VERSION "$Format:%h$"

NS_ :

BS_:

BU_: APB APP APS BCCEN BDY DAS DBG EAS EPAS EPAS2 EPAS3S EPB EPBM ESP GTW GTWU IBST IC MCU OCS PARK PARK3 RADAR RCM RT3000 SCCM SDM SEC TAS TAS2 TAS2DBG TOOL TPMS VCSEATD VCSEATP

BO_ 1513 APP_alertLog: 8 APP
 SG_ APP_alertID M : 0|14@1+ (1,0) [0|0] "" GTW
 SG_ APP_sw144_fanctrldErrorType m144 : 16|8@1+ (1,0) [2|255] "" GTW
 SG_ APP_sw145_pitchSpike m145 : 16|1@1+ (1,0) [0|1] "" GTW
 SG_ APP_sw145_yawSpike m145 : 17|1@1+ (1,0) [0|1] "" GTW
 SG_ APP_sw145_rollSpike m145 : 18|1@1+ (1,0) [0|1] "" GTW
 SG_ APP_sw145_insaneCal m145 : 19|1@1+ (1,0) [0|1] "" GTW
 SG_ APP_sw145_problemSaving m145 : 20|1@1+ (1,0) [0|1] "" GTW
 SG_ APP_sw145_problemCamPosition m145 : 24|4@1+ (1,0) [0|9] "" GTW
 SG_ APP_sw145_camExtPitchCal m145 : 32|9@1- (0.05,0) [-12.5|12.5] "deg" GTW
 SG_ APP_sw145_camExtYawCal m145 : 41|9@1- (0.05,0) [-12.5|12.5] "deg" GTW
 SG_ APP_sw145_camExtRollCal m145 : 50|9@1- (0.05,0) [-12.5|12.5] "deg" GTW
 SG_ APP_sw146_telemProblemType m146 : 16|3@1+ (1,0) [0|7] "" GTW
 SG_ APP_sw146_packageType m146 : 19|3@1+ (1,0) [0|7] "" GTW
 SG_ APP_sw146_numElementsQueued m146 : 22|9@1+ (10,0) [0|5110] "elements" GTW
 SG_ APP_sw146_telemSize m146 : 31|9@1+ (100,0) [0|51100] "kB" GTW
 SG_ APP_sw147_selfieCamI2CbusFault m147 : 16|1@1+ (1,0) [0|1] "" GTW
 SG_ APP_sw147_selfieCamDeserFault m147 : 17|3@1+ (1,0) [0|7] "" GTW
 SG_ APP_sw147_selfieCamSerFault m147 : 21|3@1+ (1,0) [0|7] "" GTW
 SG_ APP_sw147_selfieCamSensorFault m147 : 24|3@1+ (1,0) [0|7] "" GTW
 SG_ APP_sw148_unusedW0 m148 : 16|16@1+ (1,0) [0|0] "" GTW
 SG_ APP_sw148_unusedW1 m148 : 32|16@1+ (1,0) [0|0] "" GTW
 SG_ APP_sw148_unusedW2 m148 : 48|16@1+ (1,0) [0|0] "" GTW
 SG_ APP_sw149_diskUsageVar m149 : 16|8@1+ (1,0) [0|100] "percent" GTW
 SG_ APP_sw149_diskUsageHome m149 : 24|8@1+ (1,0) [0|100] "percent" GTW
 SG_ APP_sw149_diskUsageMap m149 : 32|8@1+ (1,0) [0|100] "percent" GTW
 SG_ APP_sw149_diskUsageAutopilot m149 : 40|8@1+ (1,0) [0|100] "percent" GTW
 SG_ APP_sw161_frameTimeout m161 : 16|1@1+ (1,0) [0|1] "" GTW
 SG_ APP_sw161_hdmiDisplayError m161 : 17|1@1+ (1,0) [0|1] "" GTW
 SG_ APP_sw161_rawImageTimeout m161 : 18|1@1+ (1,0) [0|1] "" GTW
 SG_ APP_sw161_imagerOutOfSpecTemp m161 : 19|1@1+ (1,0) [0|1] "" GTW
 SG_ APP_sw162_colorFilterMismatch m162 : 16|1@1+ (1,0) [0|1] "" GTW
 SG_ APP_sw162_detectedColorFilter m162 : 17|2@1+ (1,0) [0|3] "" GTW
 SG_ APP_sw162_expectedColorFilter m162 : 19|2@1+ (1,0) [0|3] "" GTW
 SG_ APP_sw162_cameraPositionMismatch m162 : 21|1@1+ (1,0) [0|1] "" GTW
 SG_ APP_sw162_blacklistedFuseID m162 : 22|1@1+ (1,0) [0|1] "" GTW
 SG_ APP_sw162_detectedPosition m162 : 24|4@1+ (1,0) [0|9] "" GTW
 SG_ APP_sw163_colorFilterMismatch m163 : 16|1@1+ (1,0) [0|1] "" GTW
 SG_ APP_sw163_detectedColorFilter m163 : 17|2@1+ (1,0) [0|3] "" GTW
 SG_ APP_sw163_expectedColorFilter m163 : 19|2@1+ (1,0) [0|3] "" GTW
 SG_ APP_sw163_cameraPositionMismatch m163 : 21|1@1+ (1,0) [0|1] "" GTW
 SG_ APP_sw163_blacklistedFuseID m163 : 22|1@1+ (1,0) [0|1] "" GTW
 SG_ APP_sw163_detectedPosition m163 : 24|4@1+ (1,0) [0|9] "" GTW
 SG_ APP_sw164_colorFilterMismatch m164 : 16|1@1+ (1,0) [0|1] "" GTW
 SG_ APP_sw164_detectedColorFilter m164 : 17|2@1+ (1,0) [0|3] "" GTW
 SG_ APP_sw164_expectedColorFilter m164 : 19|2@1+ (1,0) [0|3] "" GTW
 SG_ APP_sw164_cameraPositionMismatch m164 : 21|1@1+ (1,0) [0|1] "" GTW
 SG_ APP_sw164_blacklistedFuseID m164 : 22|1@1+ (1,0) [0|1] "" GTW
 SG_ APP_sw164_detectedPosition m164 : 24|4@1+ (1,0) [0|9] "" GTW
 SG_ APP_sw165_colorFilterMismatch m165 : 16|1@1+ (1,0) [0|1] "" GTW
 SG_ APP_sw165_detectedColorFilter m165 : 17|2@1+ (1,0) [0|3] "" GTW
 SG_ APP_sw165_expectedColorFilter m165 : 19|2@1+ (1,0) [0|3] "" GTW
 SG_ APP_sw165_cameraPositionMismatch m165 : 21|1@1+ (1,0) [0|1] "" GTW
 SG_ APP_sw165_blacklistedFuseID m165 : 22|1@1+ (1,0) [0|1] "" GTW
 SG_ APP_sw165_detectedPosition m165 : 24|4@1+ (1,0) [0|9] "" GTW
 SG_ APP_sw166_colorFilterMismatch m166 : 16|1@1+ (1,0) [0|1] "" GTW
 SG_ APP_sw166_detectedColorFilter m166 : 17|2@1+ (1,0) [0|3] "" GTW
 SG_ APP_sw166_expectedColorFilter m166 : 19|2@1+ (1,0) [0|3] "" GTW
 SG_ APP_sw166_cameraPositionMismatch m166 : 21|1@1+ (1,0) [0|1] "" GTW
 SG_ APP_sw166_blacklistedFuseID m166 : 22|1@1+ (1,0) [0|1] "" GTW
 SG_ APP_sw166_detectedPosition m166 : 24|4@1+ (1,0) [0|9] "" GTW
 SG_ APP_sw167_colorFilterMismatch m167 : 16|1@1+ (1,0) [0|1] "" GTW
 SG_ APP_sw167_detectedColorFilter m167 : 17|2@1+ (1,0) [0|3] "" GTW
 SG_ APP_sw167_expectedColorFilter m167 : 19|2@1+ (1,0) [0|3] "" GTW
 SG_ APP_sw167_cameraPositionMismatch m167 : 21|1@1+ (1,0) [0|1] "" GTW
 SG_ APP_sw167_blacklistedFuseID m167 : 22|1@1+ (1,0) [0|1] "" GTW
 SG_ APP_sw167_detectedPosition m167 : 24|4@1+ (1,0) [0|9] "" GTW
 SG_ APP_sw168_colorFilterMismatch m168 : 16|1@1+ (1,0) [0|1] "" GTW
 SG_ APP_sw168_detectedColorFilter m168 : 17|2@1+ (1,0) [0|3] "" GTW
 SG_ APP_sw168_expectedColorFilter m168 : 19|2@1+ (1,0) [0|3] "" GTW
 SG_ APP_sw168_cameraPositionMismatch m168 : 21|1@1+ (1,0) [0|1] "" GTW
 SG_ APP_sw168_blacklistedFuseID m168 : 22|1@1+ (1,0) [0|1] "" GTW
 SG_ APP_sw168_detectedPosition m168 : 24|4@1+ (1,0) [0|9] "" GTW
 SG_ APP_sw169_colorFilterMismatch m169 : 16|1@1+ (1,0) [0|1] "" GTW
 SG_ APP_sw169_detectedColorFilter m169 : 17|2@1+ (1,0) [0|3] "" GTW
 SG_ APP_sw169_expectedColorFilter m169 : 19|2@1+ (1,0) [0|3] "" GTW
 SG_ APP_sw169_cameraPositionMismatch m169 : 21|1@1+ (1,0) [0|1] "" GTW
 SG_ APP_sw169_blacklistedFuseID m169 : 22|1@1+ (1,0) [0|1] "" GTW
 SG_ APP_sw169_detectedPosition m169 : 24|4@1+ (1,0) [0|9] "" GTW
 SG_ APP_sw170_colorFilterMismatch m170 : 16|1@1+ (1,0) [0|1] "" GTW
 SG_ APP_sw170_detectedColorFilter m170 : 17|2@1+ (1,0) [0|3] "" GTW
 SG_ APP_sw170_expectedColorFilter m170 : 19|2@1+ (1,0) [0|3] "" GTW
 SG_ APP_sw170_cameraPositionMismatch m170 : 21|1@1+ (1,0) [0|1] "" GTW
 SG_ APP_sw170_blacklistedFuseID m170 : 22|1@1+ (1,0) [0|1] "" GTW
 SG_ APP_sw170_detectedPosition m170 : 24|4@1+ (1,0) [0|9] "" GTW
 SG_ APP_sw172_fisheyeCamExtNoCalFile m172 : 16|1@1+ (1,0) [0|1] "" GTW,MCU
 SG_ APP_sw172_unusedW0 m172 : 32|16@1+ (1,0) [0|0] "" GTW
 SG_ APP_sw172_unusedW1 m172 : 48|16@1+ (1,0) [0|0] "" GTW
 SG_ APP_sw173_lPillarCamExtNoCalFile m173 : 16|1@1+ (1,0) [0|1] "" GTW,MCU
 SG_ APP_sw173_unusedW0 m173 : 32|16@1+ (1,0) [0|0] "" GTW
 SG_ APP_sw173_unusedW1 m173 : 48|16@1+ (1,0) [0|0] "" GTW
 SG_ APP_sw174_rPillarCamExtNoCalFile m174 : 16|1@1+ (1,0) [0|1] "" GTW,MCU
 SG_ APP_sw174_unusedW0 m174 : 32|16@1+ (1,0) [0|0] "" GTW
 SG_ APP_sw174_unusedW1 m174 : 48|16@1+ (1,0) [0|0] "" GTW
 SG_ APP_sw175_lRepeatCamExtNoCalFile m175 : 16|1@1+ (1,0) [0|1] "" GTW,MCU
 SG_ APP_sw175_unusedW0 m175 : 32|16@1+ (1,0) [0|0] "" GTW
 SG_ APP_sw175_unusedW1 m175 : 48|16@1+ (1,0) [0|0] "" GTW
 SG_ APP_sw176_rRepeatCamExtNoCalFile m176 : 16|1@1+ (1,0) [0|1] "" GTW,MCU
 SG_ APP_sw176_unusedW0 m176 : 32|16@1+ (1,0) [0|0] "" GTW
 SG_ APP_sw176_unusedW1 m176 : 48|16@1+ (1,0) [0|0] "" GTW
 SG_ APP_sw177_fisheyeCamExtPitchCal m177 : 16|9@1- (0.05,0) [-12.5|12.5] "deg" GTW
 SG_ APP_sw177_fisheyeCamExtYawCal m177 : 25|9@1- (0.05,0) [-12.5|12.5] "deg" GTW
 SG_ APP_sw177_fisheyeCamExtRollCal m177 : 34|9@1- (0.05,0) [-12.5|12.5] "deg" GTW
 SG_ APP_sw178_lPillarCamExtPitchCal m178 : 16|9@1- (0.05,0) [-12.5|12.5] "deg" GTW
 SG_ APP_sw178_lPillarCamExtYawCal m178 : 25|9@1- (0.05,0) [-12.5|12.5] "deg" GTW
 SG_ APP_sw178_lPillarCamExtRollCal m178 : 34|9@1- (0.05,0) [-12.5|12.5] "deg" GTW
 SG_ APP_sw179_rPillarCamExtPitchCal m179 : 16|9@1- (0.05,0) [-12.5|12.5] "deg" GTW
 SG_ APP_sw179_rPillarCamExtYawCal m179 : 25|9@1- (0.05,0) [-12.5|12.5] "deg" GTW
 SG_ APP_sw179_rPillarCamExtRollCal m179 : 34|9@1- (0.05,0) [-12.5|12.5] "deg" GTW
 SG_ APP_sw180_lRepeatCamExtPitchCal m180 : 16|9@1- (0.05,0) [-12.5|12.5] "deg" GTW
 SG_ APP_sw180_lRepeatCamExtYawCal m180 : 25|9@1- (0.05,0) [-12.5|12.5] "deg" GTW
 SG_ APP_sw180_lRepeatCamExtRollCal m180 : 34|9@1- (0.05,0) [-12.5|12.5] "deg" GTW
 SG_ APP_sw181_rRepeatCamExtPitchCal m181 : 16|9@1- (0.05,0) [-12.5|12.5] "deg" GTW
 SG_ APP_sw181_rRepeatCamExtYawCal m181 : 25|9@1- (0.05,0) [-12.5|12.5] "deg" GTW
 SG_ APP_sw181_rRepeatCamExtRollCal m181 : 34|9@1- (0.05,0) [-12.5|12.5] "deg" GTW
 SG_ APP_sw182_exitStatus m182 : 16|1@1+ (1,0) [0|1] "" GTW
 SG_ APP_sw182_bufferError m182 : 17|1@1+ (1,0) [0|1] "" GTW
 SG_ APP_sw182_frameGrabFailure m182 : 18|1@1+ (1,0) [0|1] "" GTW
 SG_ APP_sw182_gainControlFailure m182 : 19|1@1+ (1,0) [0|1] "" GTW
 SG_ APP_sw182_tempMonitorFailure m182 : 20|2@1+ (1,0) [0|1] "" GTW
 SG_ APP_sw182_firstFrameGrabFailure m182 : 22|1@1+ (1,0) [0|1] "" GTW
 SG_ APP_sw182_deserParityError m182 : 23|1@1+ (1,0) [0|1] "" GTW
 SG_ APP_sw182_deserLockError m182 : 24|1@1+ (1,0) [0|1] "" GTW
 SG_ APP_sw182_deserCrcError m182 : 25|1@1+ (1,0) [0|1] "" GTW
 SG_ APP_sw182_imagerHeartbeat m182 : 26|2@1+ (1,0) [0|1] "" GTW
 SG_ APP_sw182_serializerCrcErrCount m182 : 28|8@1+ (1,0) [0|254] "" GTW
 SG_ APP_sw182_deserLineLengthError m182 : 36|1@1+ (1,0) [0|1] "" GTW
 SG_ APP_sw182_numCaptureRecoveries m182 : 37|3@1+ (1,0) [0|7] "" GTW
 SG_ APP_sw182_currentTemperature m182 : 40|8@1+ (1,-60) [-60|194] "degC" GTW
 SG_ APP_sw182_minTemperature m182 : 48|8@1+ (1,-60) [-60|194] "degC" GTW
 SG_ APP_sw182_maxTemperature m182 : 56|8@1+ (1,-60) [-60|194] "degC" GTW
 SG_ APP_sw183_exitStatus m183 : 16|1@1+ (1,0) [0|1] "" GTW
 SG_ APP_sw183_bufferError m183 : 17|1@1+ (1,0) [0|1] "" GTW
 SG_ APP_sw183_frameGrabFailure m183 : 18|1@1+ (1,0) [0|1] "" GTW
 SG_ APP_sw183_gainControlFailure m183 : 19|1@1+ (1,0) [0|1] "" GTW
 SG_ APP_sw183_tempMonitorFailure m183 : 20|2@1+ (1,0) [0|1] "" GTW
 SG_ APP_sw183_firstFrameGrabFailure m183 : 22|1@1+ (1,0) [0|1] "" GTW
 SG_ APP_sw183_deserParityError m183 : 23|1@1+ (1,0) [0|1] "" GTW
 SG_ APP_sw183_deserLockError m183 : 24|1@1+ (1,0) [0|1] "" GTW
 SG_ APP_sw183_deserCrcError m183 : 25|1@1+ (1,0) [0|1] "" GTW
 SG_ APP_sw183_imagerHeartbeat m183 : 26|2@1+ (1,0) [0|1] "" GTW
 SG_ APP_sw183_serializerCrcErrCount m183 : 28|8@1+ (1,0) [0|254] "" GTW
 SG_ APP_sw183_deserLineLengthError m183 : 36|1@1+ (1,0) [0|1] "" GTW
 SG_ APP_sw183_numCaptureRecoveries m183 : 37|3@1+ (1,0) [0|7] "" GTW
 SG_ APP_sw183_currentTemperature m183 : 40|8@1+ (1,-60) [-60|194] "degC" GTW
 SG_ APP_sw183_minTemperature m183 : 48|8@1+ (1,-60) [-60|194] "degC" GTW
 SG_ APP_sw183_maxTemperature m183 : 56|8@1+ (1,-60) [-60|194] "degC" GTW
 SG_ APP_sw184_exitStatus m184 : 16|1@1+ (1,0) [0|1] "" GTW
 SG_ APP_sw184_bufferError m184 : 17|1@1+ (1,0) [0|1] "" GTW
 SG_ APP_sw184_frameGrabFailure m184 : 18|1@1+ (1,0) [0|1] "" GTW
 SG_ APP_sw184_gainControlFailure m184 : 19|1@1+ (1,0) [0|1] "" GTW
 SG_ APP_sw184_tempMonitorFailure m184 : 20|2@1+ (1,0) [0|1] "" GTW
 SG_ APP_sw184_firstFrameGrabFailure m184 : 22|1@1+ (1,0) [0|1] "" GTW
 SG_ APP_sw184_deserParityError m184 : 23|1@1+ (1,0) [0|1] "" GTW
 SG_ APP_sw184_deserLockError m184 : 24|1@1+ (1,0) [0|1] "" GTW
 SG_ APP_sw184_deserCrcError m184 : 25|1@1+ (1,0) [0|1] "" GTW
 SG_ APP_sw184_imagerHeartbeat m184 : 26|2@1+ (1,0) [0|1] "" GTW
 SG_ APP_sw184_serializerCrcErrCount m184 : 28|8@1+ (1,0) [0|254] "" GTW
 SG_ APP_sw184_deserLineLengthError m184 : 36|1@1+ (1,0) [0|1] "" GTW
 SG_ APP_sw184_numCaptureRecoveries m184 : 37|3@1+ (1,0) [0|7] "" GTW
 SG_ APP_sw184_currentTemperature m184 : 40|8@1+ (1,-60) [-60|194] "degC" GTW
 SG_ APP_sw184_minTemperature m184 : 48|8@1+ (1,-60) [-60|194] "degC" GTW
 SG_ APP_sw184_maxTemperature m184 : 56|8@1+ (1,-60) [-60|194] "degC" GTW
 SG_ APP_sw185_exitStatus m185 : 16|1@1+ (1,0) [0|1] "" GTW
 SG_ APP_sw185_bufferError m185 : 17|1@1+ (1,0) [0|1] "" GTW
 SG_ APP_sw185_frameGrabFailure m185 : 18|1@1+ (1,0) [0|1] "" GTW
 SG_ APP_sw185_gainControlFailure m185 : 19|1@1+ (1,0) [0|1] "" GTW
 SG_ APP_sw185_tempMonitorFailure m185 : 20|2@1+ (1,0) [0|1] "" GTW
 SG_ APP_sw185_firstFrameGrabFailure m185 : 22|1@1+ (1,0) [0|1] "" GTW
 SG_ APP_sw185_deserParityError m185 : 23|1@1+ (1,0) [0|1] "" GTW
 SG_ APP_sw185_deserLockError m185 : 24|1@1+ (1,0) [0|1] "" GTW
 SG_ APP_sw185_deserCrcError m185 : 25|1@1+ (1,0) [0|1] "" GTW
 SG_ APP_sw185_imagerHeartbeat m185 : 26|2@1+ (1,0) [0|1] "" GTW
 SG_ APP_sw185_serializerCrcErrCount m185 : 28|8@1+ (1,0) [0|254] "" GTW
 SG_ APP_sw185_deserLineLengthError m185 : 36|1@1+ (1,0) [0|1] "" GTW
 SG_ APP_sw185_numCaptureRecoveries m185 : 37|3@1+ (1,0) [0|7] "" GTW
 SG_ APP_sw185_currentTemperature m185 : 40|8@1+ (1,-60) [-60|194] "degC" GTW
 SG_ APP_sw185_minTemperature m185 : 48|8@1+ (1,-60) [-60|194] "degC" GTW
 SG_ APP_sw185_maxTemperature m185 : 56|8@1+ (1,-60) [-60|194] "degC" GTW
 SG_ APP_sw186_exitStatus m186 : 16|1@1+ (1,0) [0|1] "" GTW
 SG_ APP_sw186_bufferError m186 : 17|1@1+ (1,0) [0|1] "" GTW
 SG_ APP_sw186_frameGrabFailure m186 : 18|1@1+ (1,0) [0|1] "" GTW
 SG_ APP_sw186_gainControlFailure m186 : 19|1@1+ (1,0) [0|1] "" GTW
 SG_ APP_sw186_tempMonitorFailure m186 : 20|2@1+ (1,0) [0|1] "" GTW
 SG_ APP_sw186_firstFrameGrabFailure m186 : 22|1@1+ (1,0) [0|1] "" GTW
 SG_ APP_sw186_deserParityError m186 : 23|1@1+ (1,0) [0|1] "" GTW
 SG_ APP_sw186_deserLockError m186 : 24|1@1+ (1,0) [0|1] "" GTW
 SG_ APP_sw186_deserCrcError m186 : 25|1@1+ (1,0) [0|1] "" GTW
 SG_ APP_sw186_imagerHeartbeat m186 : 26|2@1+ (1,0) [0|1] "" GTW
 SG_ APP_sw186_serializerCrcErrCount m186 : 28|8@1+ (1,0) [0|254] "" GTW
 SG_ APP_sw186_deserLineLengthError m186 : 36|1@1+ (1,0) [0|1] "" GTW
 SG_ APP_sw186_numCaptureRecoveries m186 : 37|3@1+ (1,0) [0|7] "" GTW
 SG_ APP_sw186_currentTemperature m186 : 40|8@1+ (1,-60) [-60|194] "degC" GTW
 SG_ APP_sw186_minTemperature m186 : 48|8@1+ (1,-60) [-60|194] "degC" GTW
 SG_ APP_sw186_maxTemperature m186 : 56|8@1+ (1,-60) [-60|194] "degC" GTW
 SG_ APP_sw187_exitStatus m187 : 16|1@1+ (1,0) [0|1] "" GTW
 SG_ APP_sw187_bufferError m187 : 17|1@1+ (1,0) [0|1] "" GTW
 SG_ APP_sw187_frameGrabFailure m187 : 18|1@1+ (1,0) [0|1] "" GTW
 SG_ APP_sw187_gainControlFailure m187 : 19|1@1+ (1,0) [0|1] "" GTW
 SG_ APP_sw187_tempMonitorFailure m187 : 20|2@1+ (1,0) [0|1] "" GTW
 SG_ APP_sw187_firstFrameGrabFailure m187 : 22|1@1+ (1,0) [0|1] "" GTW
 SG_ APP_sw187_deserParityError m187 : 23|1@1+ (1,0) [0|1] "" GTW
 SG_ APP_sw187_deserLockError m187 : 24|1@1+ (1,0) [0|1] "" GTW
 SG_ APP_sw187_deserCrcError m187 : 25|1@1+ (1,0) [0|1] "" GTW
 SG_ APP_sw187_imagerHeartbeat m187 : 26|2@1+ (1,0) [0|1] "" GTW
 SG_ APP_sw187_serializerCrcErrCount m187 : 28|8@1+ (1,0) [0|254] "" GTW
 SG_ APP_sw187_deserLineLengthError m187 : 36|1@1+ (1,0) [0|1] "" GTW
 SG_ APP_sw187_numCaptureRecoveries m187 : 37|3@1+ (1,0) [0|7] "" GTW
 SG_ APP_sw187_currentTemperature m187 : 40|8@1+ (1,-60) [-60|194] "degC" GTW
 SG_ APP_sw187_minTemperature m187 : 48|8@1+ (1,-60) [-60|194] "degC" GTW
 SG_ APP_sw187_maxTemperature m187 : 56|8@1+ (1,-60) [-60|194] "degC" GTW
 SG_ APP_sw188_exitStatus m188 : 16|1@1+ (1,0) [0|1] "" GTW
 SG_ APP_sw188_bufferError m188 : 17|1@1+ (1,0) [0|1] "" GTW
 SG_ APP_sw188_frameGrabFailure m188 : 18|1@1+ (1,0) [0|1] "" GTW
 SG_ APP_sw188_gainControlFailure m188 : 19|1@1+ (1,0) [0|1] "" GTW
 SG_ APP_sw188_tempMonitorFailure m188 : 20|2@1+ (1,0) [0|1] "" GTW
 SG_ APP_sw188_firstFrameGrabFailure m188 : 22|1@1+ (1,0) [0|1] "" GTW
 SG_ APP_sw188_deserParityError m188 : 23|1@1+ (1,0) [0|1] "" GTW
 SG_ APP_sw188_deserLockError m188 : 24|1@1+ (1,0) [0|1] "" GTW
 SG_ APP_sw188_deserCrcError m188 : 25|1@1+ (1,0) [0|1] "" GTW
 SG_ APP_sw188_imagerHeartbeat m188 : 26|2@1+ (1,0) [0|1] "" GTW
 SG_ APP_sw188_serializerCrcErrCount m188 : 28|8@1+ (1,0) [0|254] "" GTW
 SG_ APP_sw188_deserLineLengthError m188 : 36|1@1+ (1,0) [0|1] "" GTW
 SG_ APP_sw188_numCaptureRecoveries m188 : 37|3@1+ (1,0) [0|7] "" GTW
 SG_ APP_sw188_currentTemperature m188 : 40|8@1+ (1,-60) [-60|194] "degC" GTW
 SG_ APP_sw188_minTemperature m188 : 48|8@1+ (1,-60) [-60|194] "degC" GTW
 SG_ APP_sw188_maxTemperature m188 : 56|8@1+ (1,-60) [-60|194] "degC" GTW
 SG_ APP_sw189_exitStatus m189 : 16|1@1+ (1,0) [0|1] "" GTW
 SG_ APP_sw189_bufferError m189 : 17|1@1+ (1,0) [0|1] "" GTW
 SG_ APP_sw189_frameGrabFailure m189 : 18|1@1+ (1,0) [0|1] "" GTW
 SG_ APP_sw189_gainControlFailure m189 : 19|1@1+ (1,0) [0|1] "" GTW
 SG_ APP_sw189_tempMonitorFailure m189 : 20|2@1+ (1,0) [0|1] "" GTW
 SG_ APP_sw189_firstFrameGrabFailure m189 : 22|1@1+ (1,0) [0|1] "" GTW
 SG_ APP_sw189_deserParityError m189 : 23|1@1+ (1,0) [0|1] "" GTW
 SG_ APP_sw189_deserLockError m189 : 24|1@1+ (1,0) [0|1] "" GTW
 SG_ APP_sw189_deserCrcError m189 : 25|1@1+ (1,0) [0|1] "" GTW
 SG_ APP_sw189_imagerHeartbeat m189 : 26|2@1+ (1,0) [0|1] "" GTW
 SG_ APP_sw189_serializerCrcErrCount m189 : 28|8@1+ (1,0) [0|254] "" GTW
 SG_ APP_sw189_deserLineLengthError m189 : 36|1@1+ (1,0) [0|1] "" GTW
 SG_ APP_sw189_numCaptureRecoveries m189 : 37|3@1+ (1,0) [0|7] "" GTW
 SG_ APP_sw189_currentTemperature m189 : 40|8@1+ (1,-60) [-60|194] "degC" GTW
 SG_ APP_sw189_minTemperature m189 : 48|8@1+ (1,-60) [-60|194] "degC" GTW
 SG_ APP_sw189_maxTemperature m189 : 56|8@1+ (1,-60) [-60|194] "degC" GTW
 SG_ APP_sw190_exitStatus m190 : 16|1@1+ (1,0) [0|1] "" GTW
 SG_ APP_sw190_bufferError m190 : 17|1@1+ (1,0) [0|1] "" GTW
 SG_ APP_sw190_frameGrabFailure m190 : 18|1@1+ (1,0) [0|1] "" GTW
 SG_ APP_sw190_gainControlFailure m190 : 19|1@1+ (1,0) [0|1] "" GTW
 SG_ APP_sw190_tempMonitorFailure m190 : 20|2@1+ (1,0) [0|1] "" GTW
 SG_ APP_sw190_firstFrameGrabFailure m190 : 22|1@1+ (1,0) [0|1] "" GTW
 SG_ APP_sw190_deserParityError m190 : 23|1@1+ (1,0) [0|1] "" GTW
 SG_ APP_sw190_deserLockError m190 : 24|1@1+ (1,0) [0|1] "" GTW
 SG_ APP_sw190_deserCrcError m190 : 25|1@1+ (1,0) [0|1] "" GTW
 SG_ APP_sw190_imagerHeartbeat m190 : 26|2@1+ (1,0) [0|1] "" GTW
 SG_ APP_sw190_serializerCrcErrCount m190 : 28|8@1+ (1,0) [0|254] "" GTW
 SG_ APP_sw190_deserLineLengthError m190 : 36|1@1+ (1,0) [0|1] "" GTW
 SG_ APP_sw190_numCaptureRecoveries m190 : 37|3@1+ (1,0) [0|7] "" GTW
 SG_ APP_sw190_currentTemperature m190 : 40|8@1+ (1,-60) [-60|194] "degC" GTW
 SG_ APP_sw190_minTemperature m190 : 48|8@1+ (1,-60) [-60|194] "degC" GTW
 SG_ APP_sw190_maxTemperature m190 : 56|8@1+ (1,-60) [-60|194] "degC" GTW
 SG_ APP_sw191_abortReason m191 : 16|8@1+ (1,0) [0|0] "" GTW
 SG_ APP_sw191_handsOnState m191 : 24|4@1+ (1,0) [0|0] "" GTW
 SG_ APP_sw191_cruiseState m191 : 28|4@1+ (1,0) [0|0] "" GTW
 SG_ APP_sw191_epasErrorCode m191 : 32|4@1+ (1,0) [0|0] "" GTW
 SG_ APP_sw191_viewRange m191 : 36|8@1+ (1,0) [0|0] "m" GTW
 SG_ APP_sw191_roadClass m191 : 44|3@1+ (1,0) [0|0] "" GTW
 SG_ APP_sw191_referenceHealth m191 : 47|3@1+ (1,0) [0|0] "" GTW
 SG_ APP_sw191_solverHealth m191 : 50|3@1+ (1,0) [0|0] "" GTW
 SG_ APP_sw191_roadEstHealth m191 : 53|3@1+ (1,0) [0|0] "" GTW
 SG_ APP_sw191_roadEstMode m191 : 56|3@1+ (1,0) [0|0] "" GTW
 SG_ APP_sw191_radarFault m191 : 59|1@1+ (1,0) [0|0] "" GTW
 SG_ APP_sw191_radarBlind m191 : 60|1@1+ (1,0) [0|0] "" GTW
 SG_ APP_sw191_cameraFailsafes m191 : 61|3@1+ (1,0) [0|0] "" GTW
 SG_ APP_sw192_speakerFailureType m192 : 16|4@1+ (1,0) [0|15] "" GTW
 SG_ APP_sw192_chassisType m192 : 20|4@1+ (1,0) [0|15] "" GTW
 SG_ APP_sw192_hardwareType m192 : 24|4@1+ (1,0) [0|15] "" GTW
 SG_ APP_sw193_outOfFocusImage m193 : 16|1@1+ (1,0) [0|1] "" GTW
 SG_ APP_sw193_impairedVD m193 : 17|1@1+ (1,0) [0|1] "" GTW
 SG_ APP_sw193_blurredImage m193 : 18|1@1+ (1,0) [0|1] "" GTW
 SG_ APP_sw193_smearedSpots m193 : 19|1@1+ (1,0) [0|1] "" GTW
 SG_ APP_sw193_partialBlockage m193 : 20|1@1+ (1,0) [0|1] "" GTW
 SG_ APP_sw193_fullBlockage m193 : 21|1@1+ (1,0) [0|1] "" GTW
 SG_ APP_sw193_smearedHalos m193 : 22|1@1+ (1,0) [0|1] "" GTW
 SG_ APP_sw194_numObstacles m194 : 16|4@1+ (1,0) [0|7] "" GTW
 SG_ APP_sw194_numPedstrian m194 : 20|4@1+ (1,0) [0|7] "" GTW
 SG_ APP_sw194_timeInHold m194 : 31|16@0+ (1,0) [0|1] "" GTW
 SG_ APP_sw194_leadDx m194 : 40|8@1+ (0.1,0) [0|25] "m" GTW
 SG_ APP_sw194_leadVx m194 : 48|6@1- (0.2,0) [-6|6] "m/s" GTW
 SG_ APP_sw194_leadAx m194 : 54|6@1- (0.2,0) [-6|6] "m/s^2" GTW
 SG_ APP_sw194_reasonForHold m194 : 60|4@1+ (1,0) [0|15] "" GTW
 SG_ APP_sw195_sdiSystemStatus m195 : 16|1@1+ (1,0) [0|1] "" GTW
 SG_ APP_sw195_sdiSystemNoise m195 : 17|2@1+ (1,0) [0|3] "" GTW
 SG_ APP_sw195_sdiFrontCC m195 : 24|5@1+ (1,0) [0|31] "" GTW
 SG_ APP_sw195_s1Blocked m195 : 29|1@1+ (1,0) [0|1] "" GTW
 SG_ APP_sw195_s6Blocked m195 : 30|1@1+ (1,0) [0|1] "" GTW
 SG_ APP_sw195_s7Blocked m195 : 31|1@1+ (1,0) [0|1] "" GTW
 SG_ APP_sw195_sdiRearCC m195 : 32|5@1+ (1,0) [0|31] "" GTW
 SG_ APP_sw195_s11Blocked m195 : 37|1@1+ (1,0) [0|1] "" GTW
 SG_ APP_sw195_s12Blocked m195 : 38|1@1+ (1,0) [0|1] "" GTW
 SG_ APP_sw195_s8Blocked m195 : 39|1@1+ (1,0) [0|1] "" GTW
 SG_ APP_sw195_vehicleSpeed m195 : 40|12@1+ (0.1,0) [0|409.6] "kph" GTW
 SG_ APP_sw198_tsrMsgInvalid m198 : 16|1@1+ (1,0) [0|1] "" GTW
 SG_ APP_sw198_tflMsgInvalid m198 : 17|1@1+ (1,0) [0|1] "" GTW
 SG_ APP_sw198_partialBlockage m198 : 18|1@1+ (1,0) [0|1] "" GTW
 SG_ APP_sw198_fullBlockage m198 : 19|1@1+ (1,0) [0|1] "" GTW
 SG_ APP_sw199_numShifts m199 : 16|4@1+ (1,0) [0|15] "" GTW
 SG_ APP_sw199_internalState m199 : 20|4@1+ (1,0) [0|15] "" GTW
 SG_ APP_sw199_abortCodePARK m199 : 24|5@1+ (1,0) [0|15] "" GTW
 SG_ APP_sw199_currentSTW m199 : 29|14@1+ (0.1,-819.2) [-819.2|819] "deg" GTW
 SG_ APP_sw199_abortCodeDas m199 : 43|5@1+ (1,0) [0|31] "" GTW
 SG_ APP_sw199_maxSpeed m199 : 48|8@1+ (0.1,-12.2) [-12.2|12.2] "mph" GTW
 SG_ APP_sw199_currentSpeed m199 : 56|8@1+ (0.1,-12.2) [-12.2|12.2] "mph" GTW
 SG_ APP_sw200_startSpeed m200 : 16|10@1+ (0.1,-50) [-10|92.3] "m/s" GTW
 SG_ APP_sw200_endSpeed m200 : 26|10@1+ (0.1,-50) [-10|92.3] "m/s" GTW
 SG_ APP_sw200_epasHandsOnDetected m200 : 36|1@1+ (1,0) [0|1] "" GTW
 SG_ APP_sw200_autopilotRestricted m200 : 37|1@1+ (1,0) [0|1] "" GTW
 SG_ APP_sw200_autopilotIntState m200 : 40|4@1+ (1,0) [0|1] "" GTW
 SG_ APP_sw201_timeHorizon m201 : 16|8@1+ (0.1,0) [0|25.5] "s" GTW
 SG_ APP_sw201_vehSpeed m201 : 24|8@1+ (1,0) [0|255] "kph" GTW
 SG_ APP_sw201_stwAngleReq m201 : 32|8@1- (1,0) [-128|127] "deg" GTW
 SG_ APP_sw201_viewRangeOAL m201 : 43|3@1+ (1,0) [0|5] "" GTW
 SG_ APP_sw201_steeringErrorOAL m201 : 55|3@1+ (1,0) [0|5] "" GTW
 SG_ APP_sw201_virtualLaneInputOAL m201 : 61|3@1+ (1,0) [0|5] "" GTW
 SG_ APP_sw202_sdiSystemStatus m202 : 16|1@1+ (1,0) [0|1] "" GTW
 SG_ APP_sw202_sdiSystemNoise m202 : 17|2@1+ (1,0) [0|3] "" GTW
 SG_ APP_sw202_sdiFrontCC m202 : 24|5@1+ (1,0) [0|31] "" GTW
 SG_ APP_sw202_s1Blocked m202 : 29|1@1+ (1,0) [0|1] "" GTW
 SG_ APP_sw202_s6Blocked m202 : 30|1@1+ (1,0) [0|1] "" GTW
 SG_ APP_sw202_s7Blocked m202 : 31|1@1+ (1,0) [0|1] "" GTW
 SG_ APP_sw202_sdiRearCC m202 : 32|5@1+ (1,0) [0|31] "" GTW
 SG_ APP_sw202_s8Blocked m202 : 37|1@1+ (1,0) [0|1] "" GTW
 SG_ APP_sw202_s11Blocked m202 : 38|1@1+ (1,0) [0|1] "" GTW
 SG_ APP_sw202_s12Blocked m202 : 39|1@1+ (1,0) [0|1] "" GTW
 SG_ APP_sw202_vehicleSpeed m202 : 40|12@1+ (0.1,0) [0|409.6] "kph" GTW
 SG_ APP_sw203_slotSizeX m203 : 16|8@1+ (4,0) [0|1020] "cm" GTW
 SG_ APP_sw203_slotSizeY m203 : 24|8@1+ (4,0) [0|1020] "cm" GTW
 SG_ APP_sw203_startDistance m203 : 32|11@1+ (1,0) [0|2047] "cm" GTW
 SG_ APP_sw203_roadClass m203 : 43|3@1+ (1,0) [0|7] "" GTW
 SG_ APP_sw203_curbType m203 : 46|2@1+ (1,0) [0|3] "" GTW
 SG_ APP_sw203_controlType m203 : 48|4@1+ (1,0) [0|15] "" GTW
 SG_ APP_sw203_vehicleSkew m203 : 52|12@1+ (0.002,0) [0|8.19] "radians" GTW
 SG_ APP_sw204_frLeftMiddle m204 : 16|8@1+ (1,0) [0|255] "cm" GTW
 SG_ APP_sw204_frRightMiddle m204 : 24|8@1+ (1,0) [0|255] "cm" GTW
 SG_ APP_sw204_frRight m204 : 32|8@1+ (1,0) [0|255] "cm" GTW
 SG_ APP_sw204_frLeft m204 : 40|8@1+ (1,0) [0|255] "cm" GTW
 SG_ APP_sw204_frMiddle m204 : 48|8@1+ (1,0) [0|255] "cm" GTW
 SG_ APP_sw204_maxSpeed m204 : 56|8@1+ (0.1,-12.2) [-12.2|12.2] "mph" GTW
 SG_ APP_sw205_rrRightMiddle m205 : 16|8@1+ (1,0) [0|255] "cm" GTW
 SG_ APP_sw205_rrLeftMiddle m205 : 24|8@1+ (1,0) [0|255] "cm" GTW
 SG_ APP_sw205_rrRight m205 : 32|8@1+ (1,0) [0|255] "cm" GTW
 SG_ APP_sw205_rrLeft m205 : 40|8@1+ (1,0) [0|255] "cm" GTW
 SG_ APP_sw205_rrMiddle m205 : 48|8@1+ (1,0) [0|255] "cm" GTW
 SG_ APP_sw205_oocDistance m205 : 56|8@1+ (1,0) [0|255] "cm" GTW
 SG_ APP_sw207_lcUnavailableReason m207 : 16|8@1+ (1,0) [0|255] "" GTW
 SG_ APP_sw207_appMobileyeStatus m207 : 24|8@1+ (1,0) [0|255] "" GTW
 SG_ APP_sw207_eyeq3MainState m207 : 32|8@1+ (1,0) [0|255] "" GTW
 SG_ APP_sw213_startSpeed m213 : 16|10@1+ (0.1,-50) [-10|92.3] "m/s" GTW
 SG_ APP_sw213_endSpeed m213 : 26|10@1+ (0.1,-50) [-10|92.3] "m/s" GTW
 SG_ APP_sw213_epasHandsOnDetected m213 : 36|1@1+ (1,0) [0|1] "" GTW
 SG_ APP_sw213_autopilotRestricted m213 : 37|1@1+ (1,0) [0|1] "" GTW
 SG_ APP_sw213_autopilotIntState m213 : 40|4@1+ (1,0) [0|1] "" GTW
 SG_ APP_sw218_pedalPosition m218 : 16|7@1+ (1,0) [0|127] "%" GTW
 SG_ APP_sw218_cipvDist m218 : 24|8@1+ (0.2,0) [0|51] "m" GTW
 SG_ APP_sw218_handsOnState m218 : 32|4@1+ (1,0) [0|0] "" GTW
 SG_ APP_sw218_mcuAutosteerRestricted m218 : 36|1@1+ (1,0) [0|0] "" GTW
 SG_ APP_sw218_drivingOnHighway m218 : 37|1@1+ (1,0) [0|0] "" GTW
 SG_ APP_sw219_vehicleSpeed m219 : 16|12@1+ (0.05,-25) [-25|179.75] "mph" GTW
 SG_ APP_sw219_controlledAccess m219 : 28|1@1+ (1,0) [0|0] "" GTW
 SG_ APP_sw219_roadClass m219 : 29|3@1+ (1,0) [0|0] "" GTW
 SG_ APP_sw220_vehicleSpeed m220 : 16|12@1+ (0.05,-25) [-25|179.75] "mph" GTW
 SG_ APP_sw220_controlledAccess m220 : 28|1@1+ (1,0) [0|0] "" GTW
 SG_ APP_sw220_roadClass m220 : 29|3@1+ (1,0) [0|0] "" GTW
 SG_ APP_sw227_sensorSide m227 : 16|4@1+ (1,0) [0|15] "" GTW
 SG_ APP_sw227_sensorNumber m227 : 20|4@1+ (1,0) [0|15] "" GTW
 SG_ APP_sw227_sensorMeasurement m227 : 24|9@1+ (1,0) [0|511] "cm" GTW
 SG_ APP_sw227_vehicleSpeed m227 : 33|12@1+ (0.05,-25) [-25|179.75] "mph" GTW
 SG_ APP_sw227_ambientTemperature m227 : 45|8@1+ (0.5,-40) [-40|87.5] "C" GTW
 SG_ APP_sw230_sensor1Blocked m230 : 16|1@1+ (1,0) [0|1] "" GTW
 SG_ APP_sw230_sensor2Blocked m230 : 17|1@1+ (1,0) [0|1] "" GTW
 SG_ APP_sw230_sensor3Blocked m230 : 18|1@1+ (1,0) [0|1] "" GTW
 SG_ APP_sw230_sensor4Blocked m230 : 19|1@1+ (1,0) [0|1] "" GTW
 SG_ APP_sw230_sensor5Blocked m230 : 20|1@1+ (1,0) [0|1] "" GTW
 SG_ APP_sw230_sensor6Blocked m230 : 21|1@1+ (1,0) [0|1] "" GTW
 SG_ APP_sw230_sensor7Blocked m230 : 22|1@1+ (1,0) [0|1] "" GTW
 SG_ APP_sw230_sensor8Blocked m230 : 23|1@1+ (1,0) [0|1] "" GTW
 SG_ APP_sw230_sensor9Blocked m230 : 24|1@1+ (1,0) [0|1] "" GTW
 SG_ APP_sw230_sensor10Blocked m230 : 25|1@1+ (1,0) [0|1] "" GTW
 SG_ APP_sw230_sensor11Blocked m230 : 26|1@1+ (1,0) [0|1] "" GTW
 SG_ APP_sw230_sensor12Blocked m230 : 27|1@1+ (1,0) [0|1] "" GTW
 SG_ APP_sw231_timeToImpact m231 : 16|9@1+ (1,0) [0|511] "ms" GTW
 SG_ APP_sw231_predImpactVelocity m231 : 25|7@1+ (0.5,0) [0|63.5] "m/s" GTW
 SG_ APP_sw231_targetDistance m231 : 32|7@1+ (0.1,0) [0|12.7] "m" GTW
 SG_ APP_sw231_targetRelVelocity m231 : 39|6@1+ (0.5,0) [0|31.5] "m/s" GTW
 SG_ APP_sw231_targetRelAcceleration m231 : 45|8@1+ (0.1,-12.8) [-12.8|12.7] "m/s2" GTW
 SG_ APP_sw231_targetIsACar m231 : 53|1@1+ (1,0) [0|0] "" GTW
 SG_ APP_sw231_egoVehicleSpeed m231 : 54|5@1+ (5,0) [0|155] "kph" GTW
 SG_ APP_sw231_steeringOverride m231 : 59|1@1+ (1,0) [0|1] "" GTW
 SG_ APP_sw231_predOverlap m231 : 60|4@1+ (10,0) [0|150] "%" GTW
 SG_ APP_sw257_target_dx m257 : 16|8@1+ (0.5,0) [0|127.5] "m" GTW
 SG_ APP_sw257_target_vx m257 : 24|8@1+ (0.2,-51) [-51|0] "m/s" GTW
 SG_ APP_sw257_target_ax m257 : 32|8@1+ (0.1,-15.5) [-15.5|10] "m/s2" GTW
 SG_ APP_sw257_ego_speed m257 : 40|8@1+ (0.2,0) [0|51] "m/s" GTW
 SG_ APP_sw257_driver_reaction_time m257 : 48|8@1+ (0.02,0) [0|5.1] "s" GTW
 SG_ APP_sw257_driver_reqd_accel m257 : 56|6@1+ (0.2,-12.6) [-12.6|0] "m/s2" GTW
 SG_ APP_sw257_user_sensitivity m257 : 62|2@1+ (1,0) [0|3] "" GTW
 SG_ APP_sw258_target_dx m258 : 16|8@1+ (0.5,0) [0|127.5] "m" GTW
 SG_ APP_sw258_target_vx m258 : 24|8@1+ (0.2,-51) [-51|0] "m/s" GTW
 SG_ APP_sw258_target_ax m258 : 32|8@1+ (0.1,-15.5) [-15.5|10] "m/s2" GTW
 SG_ APP_sw258_ego_speed m258 : 40|8@1+ (0.2,0) [0|51] "m/s" GTW
 SG_ APP_sw258_ego_acceleration m258 : 48|8@1+ (0.1,-15.5) [-15.5|10] "m/s2" GTW
 SG_ APP_sw258_driver_reqd_accel m258 : 56|8@1+ (0.05,-12.75) [-12.75|0] "m/s2" GTW
 SG_ APP_sw259_do_turn_indicator m259 : 16|1@1+ (1,0) [0|1] "" GTW
 SG_ APP_sw259_do_accel_pedal m259 : 17|1@1+ (1,0) [0|1] "" GTW
 SG_ APP_sw259_do_aeb_accel_pedal m259 : 18|1@1+ (1,0) [0|1] "" GTW
 SG_ APP_sw259_do_brake_pedal m259 : 19|1@1+ (1,0) [0|1] "" GTW
 SG_ APP_sw259_do_aeb_brake_pedal m259 : 20|1@1+ (1,0) [0|1] "" GTW
 SG_ APP_sw259_do_stw_angle m259 : 21|1@1+ (1,0) [0|1] "" GTW
 SG_ APP_sw259_do_stw_rate m259 : 22|1@1+ (1,0) [0|1] "" GTW
 SG_ APP_sw259_max_dv_reached m259 : 23|1@1+ (1,0) [0|1] "" GTW
 SG_ APP_sw259_ego_speed m259 : 24|8@1+ (0.2,0) [0|51] "m/s" GTW
 SG_ APP_sw259_ego_acceleration m259 : 32|8@1+ (0.1,-15.5) [-15.5|10] "m/s2" GTW
 SG_ APP_sw259_previous_lcm_app_state m259 : 40|4@1+ (1,0) [0|1] "" GTW
 SG_ APP_sw259_unusedN01 m259 : 44|4@1+ (1,0) [0|1] "" GTW
 SG_ APP_sw259_unusedB02 m259 : 48|8@1+ (1,0) [0|1] "" GTW
 SG_ APP_sw259_unusedB03 m259 : 56|8@1+ (1,0) [0|1] "" GTW
 SG_ APP_sw260_target_dx m260 : 16|8@1+ (0.5,0) [0|127.5] "m" GTW
 SG_ APP_sw260_target_vx m260 : 24|8@1+ (0.2,-51) [-51|0] "m/s" GTW
 SG_ APP_sw260_target_ax m260 : 32|8@1+ (0.1,-15.5) [-15.5|10] "m/s2" GTW
 SG_ APP_sw260_ego_speed m260 : 40|8@1+ (0.2,0) [0|51] "m/s" GTW
 SG_ APP_sw260_driver_reaction_time m260 : 48|8@1+ (0.02,0) [0|5.1] "s" GTW
 SG_ APP_sw260_driver_reqd_accel m260 : 56|6@1+ (0.2,-12.6) [-12.6|0] "m/s2" GTW
 SG_ APP_sw260_user_sensitivity m260 : 62|2@1+ (1,0) [0|3] "" GTW
 SG_ APP_sw261_correctableErrors m261 : 16|8@1+ (1,0) [0|255] "" GTW
 SG_ APP_sw261_nonFatalUncorrErrors m261 : 24|8@1+ (1,0) [0|255] "" GTW
 SG_ APP_sw261_fatalUncorrErrors m261 : 32|8@1+ (1,0) [0|255] "" GTW
 SG_ APP_sw263_torsionThreshold m263 : 16|1@1+ (1,0) [0|0] "" GTW
 SG_ APP_sw263_eacStatusNotOk m263 : 17|1@1+ (1,0) [0|0] "" GTW
 SG_ APP_sw263_timerExpired m263 : 18|1@1+ (1,0) [0|0] "" GTW
 SG_ APP_sw263_notStableInLane m263 : 19|1@1+ (1,0) [0|0] "" GTW
 SG_ APP_sw263_outOfSpeedRegion m263 : 20|1@1+ (1,0) [0|0] "" GTW
 SG_ APP_sw263_laneTooNarrow m263 : 21|1@1+ (1,0) [0|0] "" GTW
 SG_ APP_sw263_elkConditionsMet m263 : 22|1@1+ (1,0) [0|0] "" GTW
 SG_ APP_sw263_lkaConditionsMet m263 : 23|1@1+ (1,0) [0|0] "" GTW
 SG_ APP_sw263_ldwConditionsMet m263 : 24|1@1+ (1,0) [0|0] "" GTW
 SG_ APP_sw263_laneWidth m263 : 25|7@1+ (0.05,0) [0|6.375] "m" GTW
 SG_ APP_sw263_speed m263 : 32|8@1+ (1,0) [0|255] "m/s" GTW
 SG_ APP_sw263_markerType m263 : 40|4@1+ (1,0) [0|0] "" GTW
 SG_ APP_sw263_side m263 : 44|1@1+ (1,0) [0|0] "" GTW
 SG_ APP_sw263_multiLane m263 : 45|1@1+ (1,0) [0|0] "" GTW
 SG_ APP_sw263_noCollisionImminent m263 : 46|1@1+ (1,0) [0|0] "" GTW
 SG_ APP_sw263_blinkerActive m263 : 47|1@1+ (1,0) [0|0] "" GTW
 SG_ APP_sw263_notEncroaching m263 : 48|1@1+ (1,0) [0|0] "" GTW
 SG_ APP_sw263_dtleAboveThresholdLdw m263 : 49|1@1+ (1,0) [0|0] "" GTW
 SG_ APP_sw263_vdcActive m263 : 50|1@1+ (1,0) [0|0] "" GTW
 SG_ APP_sw263_construction m263 : 51|1@1+ (1,0) [0|0] "" GTW
 SG_ APP_sw263_snowyRoad m263 : 52|1@1+ (1,0) [0|0] "" GTW
 SG_ APP_sw263_sideObstacle m263 : 53|1@1+ (1,0) [0|0] "" GTW
 SG_ APP_sw263_frontObstacle m263 : 54|1@1+ (1,0) [0|0] "" GTW
 SG_ APP_sw263_turnIndicatorOn m263 : 55|1@1+ (1,0) [0|0] "" GTW
 SG_ APP_sw263_vehicleMuLow m263 : 56|1@1+ (1,0) [0|0] "" GTW
 SG_ APP_sw263_lssAbortReason m263 : 57|5@1+ (1,0) [0|31] "" GTW
 SG_ APP_sw264_faultReason m264 : 16|4@1+ (1,0) [0|0] "" GTW
 SG_ APP_sw265_mpHasRoute m265 : 16|1@1+ (1,0) [0|0] "" GTW
 SG_ APP_sw265_mpLocalizedWay m265 : 17|1@1+ (1,0) [0|0] "" GTW
 SG_ APP_sw265_mmHasRoute m265 : 18|1@1+ (1,0) [0|0] "" GTW
 SG_ APP_sw265_mmLocalizedEdge m265 : 19|1@1+ (1,0) [0|0] "" GTW
 SG_ APP_sw265_surroundCameraStatus m265 : 20|2@1+ (1,0) [0|0] "" GTW
 SG_ APP_sw265_leftPillarBlocked m265 : 22|1@1+ (1,0) [0|0] "" GTW
 SG_ APP_sw265_rightPillarBlocked m265 : 23|1@1+ (1,0) [0|0] "" GTW
 SG_ APP_sw265_unavailableReason m265 : 24|6@1+ (1,0) [0|0] "" GTW
 SG_ APP_sw265_leftRepeaterBlocked m265 : 30|1@1+ (1,0) [0|0] "" GTW
 SG_ APP_sw265_rightRepeaterBlocked m265 : 31|1@1+ (1,0) [0|0] "" GTW
 SG_ APP_sw265_backupBlocked m265 : 32|1@1+ (1,0) [0|0] "" GTW
 SG_ APP_sw265_exceptionListInvalid m265 : 33|1@1+ (1,0) [0|0] "" GTW
 SG_ APP_sw265_lPillarLanesFailsafe m265 : 34|1@1+ (1,0) [0|0] "" GTW
 SG_ APP_sw265_rPillarLanesFailsafe m265 : 35|1@1+ (1,0) [0|0] "" GTW
 SG_ APP_sw265_lRepeaterLanesFailsafe m265 : 36|1@1+ (1,0) [0|0] "" GTW
 SG_ APP_sw265_rRepeaterLanesFailsafe m265 : 37|1@1+ (1,0) [0|0] "" GTW
 SG_ APP_sw266_lPillarStreamStatus m266 : 16|3@1+ (1,0) [0|0] "" GTW
 SG_ APP_sw266_rPillarStreamStatus m266 : 19|3@1+ (1,0) [0|0] "" GTW
 SG_ APP_sw266_lRepeaterStreamStatus m266 : 24|3@1+ (1,0) [0|0] "" GTW
 SG_ APP_sw266_rRepeaterStreamStatus m266 : 27|3@1+ (1,0) [0|0] "" GTW
 SG_ APP_sw266_backupStreamStatus m266 : 32|3@1+ (1,0) [0|0] "" GTW
 SG_ APP_sw268_backupCamExtNoCalFile m268 : 16|1@1+ (1,0) [0|1] "" GTW,MCU
 SG_ APP_sw268_unusedW0 m268 : 32|16@1+ (1,0) [0|0] "" GTW
 SG_ APP_sw268_unusedW1 m268 : 48|16@1+ (1,0) [0|0] "" GTW
 SG_ APP_sw269_lPillarStreamExit m269 : 16|1@1+ (1,0) [0|0] "" GTW
 SG_ APP_sw269_rPillarStreamExit m269 : 17|1@1+ (1,0) [0|0] "" GTW
 SG_ APP_sw269_lRepeaterStreamExit m269 : 18|1@1+ (1,0) [0|0] "" GTW
 SG_ APP_sw269_rRepeaterStreamExit m269 : 19|1@1+ (1,0) [0|0] "" GTW
 SG_ APP_sw269_lPillarBlocked m269 : 20|1@1+ (1,0) [0|0] "" GTW
 SG_ APP_sw269_rPillarBlocked m269 : 21|1@1+ (1,0) [0|0] "" GTW
 SG_ APP_sw269_lRepeaterBlocked m269 : 22|1@1+ (1,0) [0|0] "" GTW
 SG_ APP_sw269_rRepeaterBlocked m269 : 23|1@1+ (1,0) [0|0] "" GTW
 SG_ APP_sw269_lPillarLanesFailsafe m269 : 24|1@1+ (1,0) [0|0] "" GTW
 SG_ APP_sw269_rPillarLanesFailsafe m269 : 25|1@1+ (1,0) [0|0] "" GTW
 SG_ APP_sw269_lRepeaterLanesFailsafe m269 : 26|1@1+ (1,0) [0|0] "" GTW
 SG_ APP_sw269_rRepeaterLanesFailsafe m269 : 27|1@1+ (1,0) [0|0] "" GTW
 SG_ APP_sw269_emergencyLaneKeep m269 : 28|5@1+ (1,0) [0|7] "" GTW
 SG_ APP_sw269_laneKeepAssist m269 : 33|5@1+ (1,0) [0|1] "" GTW
 SG_ APP_sw269_blindspot m269 : 38|5@1+ (1,0) [0|1] "" GTW
 SG_ APP_sw269_laneDepartureWarning m269 : 43|5@1+ (1,0) [0|1] "" GTW
 SG_ APP_sw269_mainStreamExit m269 : 48|1@1+ (1,0) [0|0] "" GTW
 SG_ APP_sw269_mainBlocked m269 : 49|1@1+ (1,0) [0|0] "" GTW
 SG_ APP_sw269_narrowStreamExit m269 : 50|1@1+ (1,0) [0|0] "" GTW
 SG_ APP_sw269_narrowBlocked m269 : 51|1@1+ (1,0) [0|0] "" GTW
 SG_ APP_sw269_fisheyeStreamExit m269 : 52|1@1+ (1,0) [0|0] "" GTW
 SG_ APP_sw269_fisheyeBlocked m269 : 53|1@1+ (1,0) [0|0] "" GTW
 SG_ APP_sw269_aebOffInOffRoadMode m269 : 54|1@1+ (1,0) [0|1] "" GTW
 SG_ APP_sw270_lPillarStreamExit m270 : 16|1@1+ (1,0) [0|0] "" GTW
 SG_ APP_sw270_rPillarStreamExit m270 : 17|1@1+ (1,0) [0|0] "" GTW
 SG_ APP_sw270_lRepeaterStreamExit m270 : 18|1@1+ (1,0) [0|0] "" GTW
 SG_ APP_sw270_rRepeaterStreamExit m270 : 19|1@1+ (1,0) [0|0] "" GTW
 SG_ APP_sw270_lPillarBlocked m270 : 20|1@1+ (1,0) [0|0] "" GTW
 SG_ APP_sw270_rPillarBlocked m270 : 21|1@1+ (1,0) [0|0] "" GTW
 SG_ APP_sw270_lRepeaterBlocked m270 : 22|1@1+ (1,0) [0|0] "" GTW
 SG_ APP_sw270_rRepeaterBlocked m270 : 23|1@1+ (1,0) [0|0] "" GTW
 SG_ APP_sw270_lPillarLanesFailsafe m270 : 24|1@1+ (1,0) [0|0] "" GTW
 SG_ APP_sw270_rPillarLanesFailsafe m270 : 25|1@1+ (1,0) [0|0] "" GTW
 SG_ APP_sw270_lRepeaterLanesFailsafe m270 : 26|1@1+ (1,0) [0|0] "" GTW
 SG_ APP_sw270_rRepeaterLanesFailsafe m270 : 27|1@1+ (1,0) [0|0] "" GTW
 SG_ APP_sw270_mainBlocked m270 : 28|1@1+ (1,0) [0|0] "" GTW
 SG_ APP_sw270_narrowBlocked m270 : 29|1@1+ (1,0) [0|0] "" GTW
 SG_ APP_sw270_fisheyeBlocked m270 : 30|1@1+ (1,0) [0|0] "" GTW
 SG_ APP_sw270_mainStreamExit m270 : 31|1@1+ (1,0) [0|0] "" GTW
 SG_ APP_sw270_emergencyLaneKeep m270 : 32|5@1+ (1,0) [0|7] "" GTW
 SG_ APP_sw270_laneKeepAssist m270 : 37|5@1+ (1,0) [0|1] "" GTW
 SG_ APP_sw270_blindspot m270 : 42|5@1+ (1,0) [0|1] "" GTW
 SG_ APP_sw270_laneDepartureWarning m270 : 47|5@1+ (1,0) [0|1] "" GTW
 SG_ APP_sw270_aebOffInOffRoadMode m270 : 52|1@1+ (1,0) [0|1] "" GTW
 SG_ APP_sw271_abortReason m271 : 16|5@1+ (0,0) [0|0] "" GTW
 SG_ APP_sw271_progress m271 : 21|8@1+ (0.0039215,0) [0|1] "%" GTW
 SG_ APP_sw271_egoSpeed m271 : 29|8@1+ (0.2,0) [0|51] "m/s" GTW
 SG_ APP_sw271_direction m271 : 37|1@1+ (1,0) [0|0] "" GTW
 SG_ APP_sw272_unavailableReason m272 : 16|4@1+ (0,0) [0|0] "" GTW
 SG_ APP_sw272_lPillarStreamExit m272 : 20|1@1+ (0,0) [0|0] "" GTW
 SG_ APP_sw272_rPillarStreamExit m272 : 21|1@1+ (0,0) [0|0] "" GTW
 SG_ APP_sw272_lRepeaterStreamExit m272 : 22|1@1+ (0,0) [0|0] "" GTW
 SG_ APP_sw272_rRepeaterStreamExit m272 : 23|1@1+ (0,0) [0|0] "" GTW
 SG_ APP_sw272_lPillarBlocked m272 : 24|1@1+ (0,0) [0|0] "" GTW
 SG_ APP_sw272_rPillarBlocked m272 : 25|1@1+ (0,0) [0|0] "" GTW
 SG_ APP_sw272_lRepeaterBlocked m272 : 26|1@1+ (0,0) [0|0] "" GTW
 SG_ APP_sw272_rRepeaterBlocked m272 : 27|1@1+ (0,0) [0|0] "" GTW
 SG_ APP_sw273_eventType m273 : 16|1@1+ (1,0) [0|0] "" GTW
 SG_ APP_sw273_collisionType m273 : 17|3@1+ (1,0) [0|7] "" GTW
 SG_ APP_sw273_side m273 : 20|1@1+ (1,0) [0|1] "" GTW
 SG_ APP_sw273_alarmStrikes m273 : 21|3@1+ (1,0) [0|7] "" GTW
 SG_ APP_sw273_timeToCollision m273 : 24|8@1+ (0.02,0) [0|5.11] "s" GTW
 SG_ APP_sw273_lngDistanceToVehicle m273 : 32|8@1+ (0.02,0) [0|5.11] "m" GTW
 SG_ APP_sw273_latDistanceToVehicle m273 : 40|8@1+ (0.02,0) [0|5.11] "m" GTW
 SG_ APP_sw273_timeToLaneExit m273 : 48|7@1+ (0.02,0) [0|2.53] "s" GTW
 SG_ APP_sw273_distanceToLaneExit m273 : 55|8@1+ (0.02,0) [-2.53|2.53] "s" GTW
 SG_ APP_sw273_handsOn m273 : 63|1@1+ (1,0) [0|1] "" GTW
 SG_ APP_sw274_exitStatus m274 : 16|1@1+ (1,0) [0|1] "" GTW
 SG_ APP_sw274_bufferError m274 : 17|1@1+ (1,0) [0|1] "" GTW
 SG_ APP_sw274_frameGrabFailure m274 : 18|1@1+ (1,0) [0|1] "" GTW
 SG_ APP_sw274_gainControlFailure m274 : 19|1@1+ (1,0) [0|1] "" GTW
 SG_ APP_sw274_tempMonitorFailure m274 : 20|2@1+ (1,0) [0|1] "" GTW
 SG_ APP_sw274_firstFrameGrabFailure m274 : 22|1@1+ (1,0) [0|1] "" GTW
 SG_ APP_sw274_deserParityError m274 : 23|1@1+ (1,0) [0|1] "" GTW
 SG_ APP_sw274_deserLockError m274 : 24|1@1+ (1,0) [0|1] "" GTW
 SG_ APP_sw274_deserCrcError m274 : 25|1@1+ (1,0) [0|1] "" GTW
 SG_ APP_sw274_imagerHeartbeat m274 : 26|2@1+ (1,0) [0|1] "" GTW
 SG_ APP_sw274_serializerCrcErrCount m274 : 28|8@1+ (1,0) [0|254] "" GTW
 SG_ APP_sw274_deserLineLengthError m274 : 36|1@1+ (1,0) [0|1] "" GTW
 SG_ APP_sw274_numCaptureRecoveries m274 : 37|3@1+ (1,0) [0|7] "" GTW
 SG_ APP_sw274_currentTemperature m274 : 40|8@1+ (1,-60) [-60|194] "degC" GTW
 SG_ APP_sw274_minTemperature m274 : 48|8@1+ (1,-60) [-60|194] "degC" GTW
 SG_ APP_sw274_maxTemperature m274 : 56|8@1+ (1,-60) [-60|194] "degC" GTW
 SG_ APP_sw275_exitStatus m275 : 16|1@1+ (1,0) [0|1] "" GTW
 SG_ APP_sw275_bufferError m275 : 17|1@1+ (1,0) [0|1] "" GTW
 SG_ APP_sw275_frameGrabFailure m275 : 18|1@1+ (1,0) [0|1] "" GTW
 SG_ APP_sw275_gainControlFailure m275 : 19|1@1+ (1,0) [0|1] "" GTW
 SG_ APP_sw275_tempMonitorFailure m275 : 20|2@1+ (1,0) [0|1] "" GTW
 SG_ APP_sw275_firstFrameGrabFailure m275 : 22|1@1+ (1,0) [0|1] "" GTW
 SG_ APP_sw275_deserParityError m275 : 23|1@1+ (1,0) [0|1] "" GTW
 SG_ APP_sw275_deserLockError m275 : 24|1@1+ (1,0) [0|1] "" GTW
 SG_ APP_sw275_deserCrcError m275 : 25|1@1+ (1,0) [0|1] "" GTW
 SG_ APP_sw275_imagerHeartbeat m275 : 26|2@1+ (1,0) [0|1] "" GTW
 SG_ APP_sw275_serializerCrcErrCount m275 : 28|8@1+ (1,0) [0|254] "" GTW
 SG_ APP_sw275_deserLineLengthError m275 : 36|1@1+ (1,0) [0|1] "" GTW
 SG_ APP_sw275_numCaptureRecoveries m275 : 37|3@1+ (1,0) [0|7] "" GTW
 SG_ APP_sw275_currentTemperature m275 : 40|8@1+ (1,-60) [-60|194] "degC" GTW
 SG_ APP_sw275_minTemperature m275 : 48|8@1+ (1,-60) [-60|194] "degC" GTW
 SG_ APP_sw275_maxTemperature m275 : 56|8@1+ (1,-60) [-60|194] "degC" GTW
 SG_ APP_sw276_exitStatus m276 : 16|1@1+ (1,0) [0|1] "" GTW
 SG_ APP_sw276_bufferError m276 : 17|1@1+ (1,0) [0|1] "" GTW
 SG_ APP_sw276_frameGrabFailure m276 : 18|1@1+ (1,0) [0|1] "" GTW
 SG_ APP_sw276_gainControlFailure m276 : 19|1@1+ (1,0) [0|1] "" GTW
 SG_ APP_sw276_tempMonitorFailure m276 : 20|2@1+ (1,0) [0|1] "" GTW
 SG_ APP_sw276_firstFrameGrabFailure m276 : 22|1@1+ (1,0) [0|1] "" GTW
 SG_ APP_sw276_deserParityError m276 : 23|1@1+ (1,0) [0|1] "" GTW
 SG_ APP_sw276_deserLockError m276 : 24|1@1+ (1,0) [0|1] "" GTW
 SG_ APP_sw276_deserCrcError m276 : 25|1@1+ (1,0) [0|1] "" GTW
 SG_ APP_sw276_imagerHeartbeat m276 : 26|2@1+ (1,0) [0|1] "" GTW
 SG_ APP_sw276_serializerCrcErrCount m276 : 28|8@1+ (1,0) [0|254] "" GTW
 SG_ APP_sw276_deserLineLengthError m276 : 36|1@1+ (1,0) [0|1] "" GTW
 SG_ APP_sw276_numCaptureRecoveries m276 : 37|3@1+ (1,0) [0|7] "" GTW
 SG_ APP_sw276_currentTemperature m276 : 40|8@1+ (1,-60) [-60|194] "degC" GTW
 SG_ APP_sw276_minTemperature m276 : 48|8@1+ (1,-60) [-60|194] "degC" GTW
 SG_ APP_sw276_maxTemperature m276 : 56|8@1+ (1,-60) [-60|194] "degC" GTW
 SG_ APP_sw277_exitStatus m277 : 16|1@1+ (1,0) [0|1] "" GTW
 SG_ APP_sw277_bufferError m277 : 17|1@1+ (1,0) [0|1] "" GTW
 SG_ APP_sw277_frameGrabFailure m277 : 18|1@1+ (1,0) [0|1] "" GTW
 SG_ APP_sw277_gainControlFailure m277 : 19|1@1+ (1,0) [0|1] "" GTW
 SG_ APP_sw277_tempMonitorFailure m277 : 20|2@1+ (1,0) [0|1] "" GTW
 SG_ APP_sw277_firstFrameGrabFailure m277 : 22|1@1+ (1,0) [0|1] "" GTW
 SG_ APP_sw277_deserParityError m277 : 23|1@1+ (1,0) [0|1] "" GTW
 SG_ APP_sw277_deserLockError m277 : 24|1@1+ (1,0) [0|1] "" GTW
 SG_ APP_sw277_deserCrcError m277 : 25|1@1+ (1,0) [0|1] "" GTW
 SG_ APP_sw277_imagerHeartbeat m277 : 26|2@1+ (1,0) [0|1] "" GTW
 SG_ APP_sw277_serializerCrcErrCount m277 : 28|8@1+ (1,0) [0|254] "" GTW
 SG_ APP_sw277_deserLineLengthError m277 : 36|1@1+ (1,0) [0|1] "" GTW
 SG_ APP_sw277_numCaptureRecoveries m277 : 37|3@1+ (1,0) [0|7] "" GTW
 SG_ APP_sw277_currentTemperature m277 : 40|8@1+ (1,-60) [-60|194] "degC" GTW
 SG_ APP_sw277_minTemperature m277 : 48|8@1+ (1,-60) [-60|194] "degC" GTW
 SG_ APP_sw277_maxTemperature m277 : 56|8@1+ (1,-60) [-60|194] "degC" GTW
 SG_ APP_sw278_exitStatus m278 : 16|1@1+ (1,0) [0|1] "" GTW
 SG_ APP_sw278_bufferError m278 : 17|1@1+ (1,0) [0|1] "" GTW
 SG_ APP_sw278_frameGrabFailure m278 : 18|1@1+ (1,0) [0|1] "" GTW
 SG_ APP_sw278_gainControlFailure m278 : 19|1@1+ (1,0) [0|1] "" GTW
 SG_ APP_sw278_tempMonitorFailure m278 : 20|2@1+ (1,0) [0|1] "" GTW
 SG_ APP_sw278_firstFrameGrabFailure m278 : 22|1@1+ (1,0) [0|1] "" GTW
 SG_ APP_sw278_deserParityError m278 : 23|1@1+ (1,0) [0|1] "" GTW
 SG_ APP_sw278_deserLockError m278 : 24|1@1+ (1,0) [0|1] "" GTW
 SG_ APP_sw278_deserCrcError m278 : 25|1@1+ (1,0) [0|1] "" GTW
 SG_ APP_sw278_imagerHeartbeat m278 : 26|2@1+ (1,0) [0|1] "" GTW
 SG_ APP_sw278_serializerCrcErrCount m278 : 28|8@1+ (1,0) [0|254] "" GTW
 SG_ APP_sw278_deserLineLengthError m278 : 36|1@1+ (1,0) [0|1] "" GTW
 SG_ APP_sw278_numCaptureRecoveries m278 : 37|3@1+ (1,0) [0|7] "" GTW
 SG_ APP_sw278_currentTemperature m278 : 40|8@1+ (1,-60) [-60|194] "degC" GTW
 SG_ APP_sw278_minTemperature m278 : 48|8@1+ (1,-60) [-60|194] "degC" GTW
 SG_ APP_sw278_maxTemperature m278 : 56|8@1+ (1,-60) [-60|194] "degC" GTW
 SG_ APP_sw279_exitStatus m279 : 16|1@1+ (1,0) [0|1] "" GTW
 SG_ APP_sw279_bufferError m279 : 17|1@1+ (1,0) [0|1] "" GTW
 SG_ APP_sw279_frameGrabFailure m279 : 18|1@1+ (1,0) [0|1] "" GTW
 SG_ APP_sw279_gainControlFailure m279 : 19|1@1+ (1,0) [0|1] "" GTW
 SG_ APP_sw279_tempMonitorFailure m279 : 20|2@1+ (1,0) [0|1] "" GTW
 SG_ APP_sw279_firstFrameGrabFailure m279 : 22|1@1+ (1,0) [0|1] "" GTW
 SG_ APP_sw279_deserParityError m279 : 23|1@1+ (1,0) [0|1] "" GTW
 SG_ APP_sw279_deserLockError m279 : 24|1@1+ (1,0) [0|1] "" GTW
 SG_ APP_sw279_deserCrcError m279 : 25|1@1+ (1,0) [0|1] "" GTW
 SG_ APP_sw279_imagerHeartbeat m279 : 26|2@1+ (1,0) [0|1] "" GTW
 SG_ APP_sw279_serializerCrcErrCount m279 : 28|8@1+ (1,0) [0|254] "" GTW
 SG_ APP_sw279_deserLineLengthError m279 : 36|1@1+ (1,0) [0|1] "" GTW
 SG_ APP_sw279_numCaptureRecoveries m279 : 37|3@1+ (1,0) [0|7] "" GTW
 SG_ APP_sw279_currentTemperature m279 : 40|8@1+ (1,-60) [-60|194] "degC" GTW
 SG_ APP_sw279_minTemperature m279 : 48|8@1+ (1,-60) [-60|194] "degC" GTW
 SG_ APP_sw279_maxTemperature m279 : 56|8@1+ (1,-60) [-60|194] "degC" GTW
 SG_ APP_sw280_exitStatus m280 : 16|1@1+ (1,0) [0|1] "" GTW
 SG_ APP_sw280_bufferError m280 : 17|1@1+ (1,0) [0|1] "" GTW
 SG_ APP_sw280_frameGrabFailure m280 : 18|1@1+ (1,0) [0|1] "" GTW
 SG_ APP_sw280_gainControlFailure m280 : 19|1@1+ (1,0) [0|1] "" GTW
 SG_ APP_sw280_tempMonitorFailure m280 : 20|2@1+ (1,0) [0|1] "" GTW
 SG_ APP_sw280_firstFrameGrabFailure m280 : 22|1@1+ (1,0) [0|1] "" GTW
 SG_ APP_sw280_deserParityError m280 : 23|1@1+ (1,0) [0|1] "" GTW
 SG_ APP_sw280_deserLockError m280 : 24|1@1+ (1,0) [0|1] "" GTW
 SG_ APP_sw280_deserCrcError m280 : 25|1@1+ (1,0) [0|1] "" GTW
 SG_ APP_sw280_imagerHeartbeat m280 : 26|2@1+ (1,0) [0|1] "" GTW
 SG_ APP_sw280_serializerCrcErrCount m280 : 28|8@1+ (1,0) [0|254] "" GTW
 SG_ APP_sw280_deserLineLengthError m280 : 36|1@1+ (1,0) [0|1] "" GTW
 SG_ APP_sw280_numCaptureRecoveries m280 : 37|3@1+ (1,0) [0|7] "" GTW
 SG_ APP_sw280_currentTemperature m280 : 40|8@1+ (1,-60) [-60|194] "degC" GTW
 SG_ APP_sw280_minTemperature m280 : 48|8@1+ (1,-60) [-60|194] "degC" GTW
 SG_ APP_sw280_maxTemperature m280 : 56|8@1+ (1,-60) [-60|194] "degC" GTW
 SG_ APP_sw281_exitStatus m281 : 16|1@1+ (1,0) [0|1] "" GTW
 SG_ APP_sw281_bufferError m281 : 17|1@1+ (1,0) [0|1] "" GTW
 SG_ APP_sw281_frameGrabFailure m281 : 18|1@1+ (1,0) [0|1] "" GTW
 SG_ APP_sw281_gainControlFailure m281 : 19|1@1+ (1,0) [0|1] "" GTW
 SG_ APP_sw281_tempMonitorFailure m281 : 20|2@1+ (1,0) [0|1] "" GTW
 SG_ APP_sw281_firstFrameGrabFailure m281 : 22|1@1+ (1,0) [0|1] "" GTW
 SG_ APP_sw281_deserParityError m281 : 23|1@1+ (1,0) [0|1] "" GTW
 SG_ APP_sw281_deserLockError m281 : 24|1@1+ (1,0) [0|1] "" GTW
 SG_ APP_sw281_deserCrcError m281 : 25|1@1+ (1,0) [0|1] "" GTW
 SG_ APP_sw281_imagerHeartbeat m281 : 26|2@1+ (1,0) [0|1] "" GTW
 SG_ APP_sw281_serializerCrcErrCount m281 : 28|8@1+ (1,0) [0|254] "" GTW
 SG_ APP_sw281_deserLineLengthError m281 : 36|1@1+ (1,0) [0|1] "" GTW
 SG_ APP_sw281_numCaptureRecoveries m281 : 37|3@1+ (1,0) [0|7] "" GTW
 SG_ APP_sw281_currentTemperature m281 : 40|8@1+ (1,-60) [-60|194] "degC" GTW
 SG_ APP_sw281_minTemperature m281 : 48|8@1+ (1,-60) [-60|194] "degC" GTW
 SG_ APP_sw281_maxTemperature m281 : 56|8@1+ (1,-60) [-60|194] "degC" GTW
 SG_ APP_sw282_exitStatus m282 : 16|1@1+ (1,0) [0|1] "" GTW
 SG_ APP_sw282_bufferError m282 : 17|1@1+ (1,0) [0|1] "" GTW
 SG_ APP_sw282_frameGrabFailure m282 : 18|1@1+ (1,0) [0|1] "" GTW
 SG_ APP_sw282_gainControlFailure m282 : 19|1@1+ (1,0) [0|1] "" GTW
 SG_ APP_sw282_tempMonitorFailure m282 : 20|2@1+ (1,0) [0|1] "" GTW
 SG_ APP_sw282_firstFrameGrabFailure m282 : 22|1@1+ (1,0) [0|1] "" GTW
 SG_ APP_sw282_deserParityError m282 : 23|1@1+ (1,0) [0|1] "" GTW
 SG_ APP_sw282_deserLockError m282 : 24|1@1+ (1,0) [0|1] "" GTW
 SG_ APP_sw282_deserCrcError m282 : 25|1@1+ (1,0) [0|1] "" GTW
 SG_ APP_sw282_imagerHeartbeat m282 : 26|2@1+ (1,0) [0|1] "" GTW
 SG_ APP_sw282_serializerCrcErrCount m282 : 28|8@1+ (1,0) [0|254] "" GTW
 SG_ APP_sw282_deserLineLengthError m282 : 36|1@1+ (1,0) [0|1] "" GTW
 SG_ APP_sw282_numCaptureRecoveries m282 : 37|3@1+ (1,0) [0|7] "" GTW
 SG_ APP_sw282_currentTemperature m282 : 40|8@1+ (1,-60) [-60|194] "degC" GTW
 SG_ APP_sw282_minTemperature m282 : 48|8@1+ (1,-60) [-60|194] "degC" GTW
 SG_ APP_sw282_maxTemperature m282 : 56|8@1+ (1,-60) [-60|194] "degC" GTW
 SG_ APP_sw283_appAbortReason m283 : 16|5@1+ (1,0) [0|31] "" GTW
 SG_ APP_sw283_apsAbortReason m283 : 21|5@1+ (1,0) [0|31] "" GTW
 SG_ APP_sw283_distanceTravelled m283 : 26|10@1+ (1,0.1) [0|102.3] "m" GTW
 SG_ APP_sw283_phoneDistance m283 : 36|10@1+ (1,0.1) [0|102.3] "m" GTW
 SG_ APP_sw283_goalDistance m283 : 46|10@1+ (1,0.1) [0|102.3] "m" GTW
 SG_ APP_sw283_mainCam m283 : 56|1@1+ (1,0) [0|1] "" GTW
 SG_ APP_sw283_narrowCam m283 : 57|1@1+ (1,0) [0|1] "" GTW
 SG_ APP_sw283_fisheyeCam m283 : 58|1@1+ (1,0) [0|1] "" GTW
 SG_ APP_sw283_leftRepeaterCam m283 : 59|1@1+ (1,0) [0|1] "" GTW
 SG_ APP_sw283_rightRepeaterCam m283 : 60|1@1+ (1,0) [0|1] "" GTW
 SG_ APP_sw283_leftPillarCam m283 : 61|1@1+ (1,0) [0|1] "" GTW
 SG_ APP_sw283_rightPillarCam m283 : 62|1@1+ (1,0) [0|1] "" GTW
 SG_ APP_sw283_bucCam m283 : 63|1@1+ (1,0) [0|1] "" GTW
 SG_ APP_sw284_antennaDisconnected m284 : 16|1@1+ (1,0) [0|1] "" GTW
 SG_ APP_sw285_gpsCommMissing m285 : 16|1@1+ (1,0) [0|0] "" GTW
 SG_ APP_sw285_gpsJunkData m285 : 17|1@1+ (1,0) [0|0] "" GTW
 SG_ APP_sw285_gpsNMEAmissing m285 : 18|1@1+ (1,0) [0|0] "" GTW
 SG_ APP_sw285_gpsUBXmissing m285 : 19|1@1+ (1,0) [0|0] "" GTW
 SG_ APP_sw285_fusionModeDisabled m285 : 20|1@1+ (1,0) [0|0] "" GTW
 SG_ APP_sw285_gpsCfgFail m285 : 21|1@1+ (1,0) [0|0] "" GTW
 SG_ APP_sw285_esfStatusMsgMIA m285 : 22|1@1+ (1,0) [0|0] "" GTW
 SG_ APP_sw285_wheelTickCfgMissmatch m285 : 23|1@1+ (1,0) [0|0] "" GTW
 SG_ APP_sw285_exitTransportMode m285 : 24|1@1+ (1,0) [0|0] "" GTW
 SG_ APP_sw285_satRejectionTimeout m285 : 25|1@1+ (1,0) [0|0] "" GTW
 SG_ APP_sw286_cfgBufNull m286 : 16|1@1+ (1,0) [0|0] "" GTW
 SG_ APP_sw286_invalidID m286 : 17|1@1+ (1,0) [0|0] "" GTW
 SG_ APP_sw286_gpsBufferOverflow m286 : 18|1@1+ (1,0) [0|0] "" GTW
 SG_ APP_sw286_navx5CfgFailed m286 : 19|1@1+ (1,0) [0|0] "" GTW
 SG_ APP_sw286_mcuNMEAmsgUDPinvalid m286 : 20|1@1+ (1,0) [0|0] "" GTW
 SG_ APP_sw286_mcuDbgMsgInvalid m286 : 21|1@1+ (1,0) [0|0] "" GTW
 SG_ APP_sw286_mcuDbgMsgTooBig m286 : 22|1@1+ (1,0) [0|0] "" GTW
 SG_ APP_sw286_mcuFwdNMEAfail m286 : 23|1@1+ (1,0) [0|0] "" GTW
 SG_ APP_sw286_NMEAinvalidChecksum m286 : 24|1@1+ (1,0) [0|0] "" GTW
 SG_ APP_sw286_unexpectedNMEAmsg m286 : 25|1@1+ (1,0) [0|0] "" GTW
 SG_ APP_sw286_UARTbusFull m286 : 26|1@1+ (1,0) [0|0] "" GTW
 SG_ APP_sw286_UARTframeError m286 : 27|1@1+ (1,0) [0|0] "" GTW
 SG_ APP_sw286_UBXrxFrameTooBig m286 : 28|1@1+ (1,0) [0|0] "" GTW
 SG_ APP_sw286_emptyValidNMEA m286 : 29|1@1+ (1,0) [0|0] "" GTW
 SG_ APP_sw286_invalidAsciiNMEA m286 : 30|1@1+ (1,0) [0|0] "" GTW
 SG_ APP_sw286_wheeltickUARTfault m286 : 31|1@1+ (1,0) [0|0] "" GTW
 SG_ APP_sw286_baudrateMismatch m286 : 32|1@1+ (1,0) [0|0] "" GTW
 SG_ APP_sw286_wheelTickInvalidSrc m286 : 33|1@1+ (1,0) [0|0] "" GTW
 SG_ APP_sw286_UARTparityError m286 : 34|1@1+ (1,0) [0|0] "" GTW
 SG_ APP_sw286_UARTrxFifoOverflow m286 : 35|1@1+ (1,0) [0|0] "" GTW
 SG_ APP_sw286_UARTrxFifoUnderflow m286 : 36|1@1+ (1,0) [0|0] "" GTW
 SG_ APP_sw286_UARTtxFifoOverflow m286 : 37|1@1+ (1,0) [0|0] "" GTW
 SG_ APP_sw286_esfWtMsgTimeout m286 : 38|1@1+ (1,0) [0|0] "" GTW
 SG_ APP_sw286_PFLASHReadError m286 : 39|1@1+ (1,0) [0|0] "" GTW
 SG_ APP_sw286_PFLASHWriteError m286 : 40|1@1+ (1,0) [0|0] "" GTW
 SG_ APP_sw286_gpsCfgNack m286 : 41|1@1+ (1,0) [0|0] "" GTW
 SG_ APP_sw286_gpsCfgIdFail m286 : 42|6@1+ (1,0) [0|63] "" GTW
 SG_ APP_sw286_gpsSetCfgNoAck m286 : 48|1@1+ (1,0) [0|0] "" GTW
 SG_ APP_sw286_gpsReadCfgNoResponse m286 : 49|1@1+ (1,0) [0|0] "" GTW
 SG_ APP_sw286_ubxErrorReported m286 : 50|1@1+ (1,0) [0|0] "" GTW
 SG_ APP_sw287_fusionStatus m287 : 16|2@1+ (1,0) [0|3] "" GTW
 SG_ APP_sw288_dist_to_stop m288 : 16|8@1+ (0.5,0) [0|127.5] "m" GTW
 SG_ APP_sw288_ego_speed m288 : 24|8@1+ (0.2,0) [0|51] "m/s" GTW
 SG_ APP_sw288_ego_acceleration m288 : 32|8@1+ (0.1,-15.5) [-15.5|10] "m/s2" GTW
 SG_ APP_sw289_numCorrectableErrors m289 : 16|32@1+ (1,0) [0|255] "" GTW
 SG_ APP_sw290_numUncorrectableErrors m290 : 16|32@1+ (1,0) [0|255] "" GTW
 SG_ APP_sw291_dist_to_stop m291 : 16|8@1+ (0.5,0) [0|127.5] "m" GTW
 SG_ APP_sw291_ego_speed m291 : 24|8@1+ (0.2,0) [0|51] "m/s" GTW
 SG_ APP_sw291_ego_acceleration m291 : 32|8@1+ (0.1,-15.5) [-15.5|10] "m/s2" GTW
 SG_ APP_sw292_driverRestraintStsMia m292 : 16|1@1+ (1,0) [0|255] "" GTW
 SG_ APP_sw293_clockFrequencyDrift m293 : 16|16@1- (0.0005,0) [-16.384|16.3835] "%" GTW
 SG_ APP_sw294_clockFrequencyDrift m294 : 16|16@1- (0.0005,0) [-16.384|16.3835] "%" GTW
 SG_ APP_sw295_clockFrequencyDrift m295 : 16|16@1- (0.0005,0) [-16.384|16.3835] "%" GTW
 SG_ APP_sw296_clockFrequencyDrift m296 : 16|16@1- (0.0005,0) [-16.384|16.3835] "%" GTW
 SG_ APP_sw297_clockFrequencyDrift m297 : 16|16@1- (0.0005,0) [-16.384|16.3835] "%" GTW
 SG_ APP_sw298_clockFrequencyDrift m298 : 16|16@1- (0.0005,0) [-16.384|16.3835] "%" GTW
 SG_ APP_sw299_clockFrequencyDrift m299 : 16|16@1- (0.0005,0) [-16.384|16.3835] "%" GTW
 SG_ APP_sw300_clockFrequencyDrift m300 : 16|16@1- (0.0005,0) [-16.384|16.3835] "%" GTW
 SG_ APP_sw301_clockFrequencyDrift m301 : 16|16@1- (0.0005,0) [-16.384|16.3835] "%" GTW
 SG_ APP_sw304_lssLPillarBlocked m304 : 16|1@1+ (1,0) [0|0] "" GTW
 SG_ APP_sw304_lssRPillarBlocked m304 : 17|1@1+ (1,0) [0|0] "" GTW
 SG_ APP_sw304_lssLRepeaterBlocked m304 : 18|1@1+ (1,0) [0|0] "" GTW
 SG_ APP_sw304_lssRRepeaterBlocked m304 : 19|1@1+ (1,0) [0|0] "" GTW
 SG_ APP_sw304_lssMainBlocked m304 : 20|1@1+ (1,0) [0|0] "" GTW
 SG_ APP_sw305_lssLPillarStreamExit m305 : 16|1@1+ (1,0) [0|0] "" GTW
 SG_ APP_sw305_lssRPillarStreamExit m305 : 17|1@1+ (1,0) [0|0] "" GTW
 SG_ APP_sw305_lssLRepeaterStreamExit m305 : 18|1@1+ (1,0) [0|0] "" GTW
 SG_ APP_sw305_lssRRepeaterStreamExit m305 : 19|1@1+ (1,0) [0|0] "" GTW
 SG_ APP_sw306_lssUssS1Blocked m306 : 16|1@1+ (1,0) [0|0] "" GTW
 SG_ APP_sw306_lssUssS2Blocked m306 : 17|1@1+ (1,0) [0|0] "" GTW
 SG_ APP_sw306_lssUssS3Blocked m306 : 18|1@1+ (1,0) [0|0] "" GTW
 SG_ APP_sw306_lssUssS4Blocked m306 : 19|1@1+ (1,0) [0|0] "" GTW
 SG_ APP_sw306_lssUssS5Blocked m306 : 20|1@1+ (1,0) [0|0] "" GTW
 SG_ APP_sw306_lssUssS6Blocked m306 : 21|1@1+ (1,0) [0|0] "" GTW
 SG_ APP_sw306_lssUssS7Blocked m306 : 22|1@1+ (1,0) [0|0] "" GTW
 SG_ APP_sw306_lssUssS8Blocked m306 : 23|1@1+ (1,0) [0|0] "" GTW
 SG_ APP_sw306_lssUssS9Blocked m306 : 24|1@1+ (1,0) [0|0] "" GTW
 SG_ APP_sw306_lssUssS10Blocked m306 : 25|1@1+ (1,0) [0|0] "" GTW
 SG_ APP_sw306_lssUssS11Blocked m306 : 26|1@1+ (1,0) [0|0] "" GTW
 SG_ APP_sw306_lssUssS12Blocked m306 : 27|1@1+ (1,0) [0|0] "" GTW
 SG_ APP_sw307_lssTurnSignalFLFault m307 : 16|1@1+ (1,0) [0|0] "" GTW
 SG_ APP_sw307_lssTurnSignalFRFault m307 : 17|1@1+ (1,0) [0|0] "" GTW
 SG_ APP_sw307_lssTurnSignalRLFault m307 : 18|1@1+ (1,0) [0|0] "" GTW
 SG_ APP_sw307_lssTurnSignalRRFault m307 : 19|1@1+ (1,0) [0|0] "" GTW
 SG_ APP_sw310_txErrThresholdReached m310 : 16|1@1+ (1,0) [0|0] "" GTW
 SG_ APP_sw310_rxErrThresholdReached m310 : 17|1@1+ (1,0) [0|0] "" GTW
 SG_ APP_sw311_txErrThresholdReached m311 : 16|1@1+ (1,0) [0|0] "" GTW
 SG_ APP_sw311_rxErrThresholdReached m311 : 17|1@1+ (1,0) [0|0] "" GTW
 SG_ APP_sw312_expectedSensorModel m312 : 16|2@1+ (1,0) [0|2] "" GTW
 SG_ APP_sw312_detectedSensorModel m312 : 18|2@1+ (1,0) [0|2] "" GTW
 SG_ APP_sw312_sensorModelMismatch m312 : 20|1@1+ (1,0) [0|1] "" GTW
 SG_ APP_sw313_expectedSensorModel m313 : 16|2@1+ (1,0) [0|2] "" GTW
 SG_ APP_sw313_detectedSensorModel m313 : 18|2@1+ (1,0) [0|2] "" GTW
 SG_ APP_sw313_sensorModelMismatch m313 : 20|1@1+ (1,0) [0|1] "" GTW
 SG_ APP_sw314_expectedSensorModel m314 : 16|2@1+ (1,0) [0|2] "" GTW
 SG_ APP_sw314_detectedSensorModel m314 : 18|2@1+ (1,0) [0|2] "" GTW
 SG_ APP_sw314_sensorModelMismatch m314 : 20|1@1+ (1,0) [0|1] "" GTW
 SG_ APP_sw315_expectedSensorModel m315 : 16|2@1+ (1,0) [0|2] "" GTW
 SG_ APP_sw315_detectedSensorModel m315 : 18|2@1+ (1,0) [0|2] "" GTW
 SG_ APP_sw315_sensorModelMismatch m315 : 20|1@1+ (1,0) [0|1] "" GTW
 SG_ APP_sw316_expectedSensorModel m316 : 16|2@1+ (1,0) [0|2] "" GTW
 SG_ APP_sw316_detectedSensorModel m316 : 18|2@1+ (1,0) [0|2] "" GTW
 SG_ APP_sw316_sensorModelMismatch m316 : 20|1@1+ (1,0) [0|1] "" GTW
 SG_ APP_sw317_expectedSensorModel m317 : 16|2@1+ (1,0) [0|2] "" GTW
 SG_ APP_sw317_detectedSensorModel m317 : 18|2@1+ (1,0) [0|2] "" GTW
 SG_ APP_sw317_sensorModelMismatch m317 : 20|1@1+ (1,0) [0|1] "" GTW
 SG_ APP_sw318_expectedSensorModel m318 : 16|2@1+ (1,0) [0|2] "" GTW
 SG_ APP_sw318_detectedSensorModel m318 : 18|2@1+ (1,0) [0|2] "" GTW
 SG_ APP_sw318_sensorModelMismatch m318 : 20|1@1+ (1,0) [0|1] "" GTW
 SG_ APP_sw319_expectedSensorModel m319 : 16|2@1+ (1,0) [0|2] "" GTW
 SG_ APP_sw319_detectedSensorModel m319 : 18|2@1+ (1,0) [0|2] "" GTW
 SG_ APP_sw319_sensorModelMismatch m319 : 20|1@1+ (1,0) [0|1] "" GTW
 SG_ APP_sw320_expectedSensorModel m320 : 16|2@1+ (1,0) [0|2] "" GTW
 SG_ APP_sw320_detectedSensorModel m320 : 18|2@1+ (1,0) [0|2] "" GTW
 SG_ APP_sw320_sensorModelMismatch m320 : 20|1@1+ (1,0) [0|1] "" GTW

BO_ 1045 APP_backupDashCamStatus: 1 APP
 SG_ APP_backupDashCamFeedGood : 0|1@1+ (1,0) [0|1] "" GTW
 SG_ APP_backupDashCamFrameRate : 1|7@1+ (1,0) [0|127] "" GTW

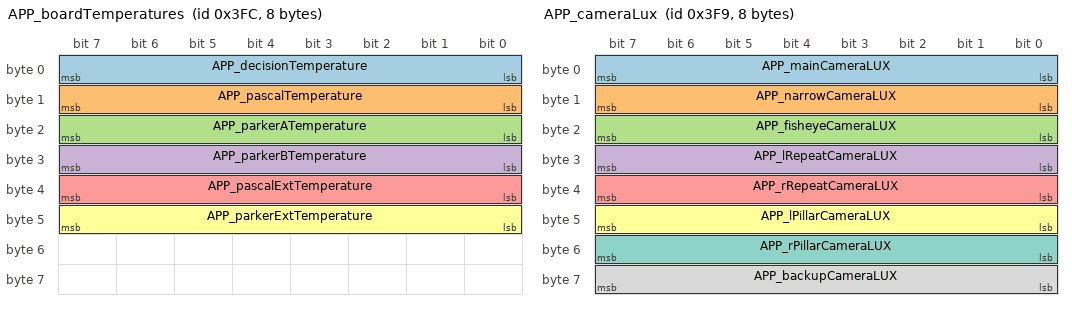
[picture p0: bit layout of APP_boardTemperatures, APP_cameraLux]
BO_ 1020 APP_boardTemperatures: 8 APP
 SG_ APP_decisionTemperature : 0|8@1+ (1,-128) [-128|127] "C" GTW
 SG_ APP_pascalTemperature : 8|8@1+ (1,-128) [-128|127] "C" GTW
 SG_ APP_parkerATemperature : 16|8@1+ (1,-128) [-128|127] "C" GTW
 SG_ APP_parkerBTemperature : 24|8@1+ (1,-128) [-128|127] "C" GTW
 SG_ APP_pascalExtTemperature : 32|8@1+ (1,-128) [-128|127] "C" GTW
 SG_ APP_parkerExtTemperature : 40|8@1+ (1,-128) [-128|127] "C" GTW

BO_ 1010 APP_camCalibrationStatus: 6 APP
 SG_ APP_cameraPosition M : 0|4@1+ (1,0) [0|8] "" GTW
 SG_ APP_mainCamExtPitchCal m1 : 8|9@1+ (0.05,-12.5) [-12.5|12.5] "deg" GTW
 SG_ APP_mainCamExtYawCal m1 : 17|9@1+ (0.05,-12.5) [-12.5|12.5] "deg" GTW
 SG_ APP_mainCalibTime m1 : 26|7@1+ (1,0) [0|512] "min" GTW
 SG_ APP_mainCalibProgress m1 : 33|7@1+ (1,0) [0|100] "percent" GTW
 SG_ APP_mainCalibrated m1 : 40|1@1+ (1,0) [0|1] "" GTW
 SG_ APP_narrowCamExtPitchCal m2 : 8|9@1+ (0.05,-12.5) [-12.5|12.5] "deg" GTW
 SG_ APP_narrowCamExtYawCal m2 : 17|9@1+ (0.05,-12.5) [-12.5|12.5] "deg" GTW
 SG_ APP_narrowCalibTime m2 : 26|7@1+ (1,0) [0|512] "min" GTW
 SG_ APP_narrowCalibProgress m2 : 33|7@1+ (1,0) [0|100] "percent" GTW
 SG_ APP_narrowCalibrated m2 : 40|1@1+ (1,0) [0|1] "" GTW
 SG_ APP_fisheyeCamExtPitchCal m3 : 8|9@1+ (0.05,-12.5) [-12.5|12.5] "deg" GTW
 SG_ APP_fisheyeCamExtYawCal m3 : 17|9@1+ (0.05,-12.5) [-12.5|12.5] "deg" GTW
 SG_ APP_fisheyeCalibTime m3 : 26|7@1+ (1,0) [0|512] "min" GTW
 SG_ APP_fisheyeCalibProgress m3 : 33|7@1+ (1,0) [0|100] "percent" GTW
 SG_ APP_fisheyeCalibrated m3 : 40|1@1+ (1,0) [0|1] "" GTW
 SG_ APP_lPillarCamExtPitchCal m4 : 8|9@1+ (0.05,-12.5) [-12.5|12.5] "deg" GTW
 SG_ APP_lPillarCamExtYawCal m4 : 17|9@1+ (0.05,-12.5) [-12.5|12.5] "deg" GTW
 SG_ APP_lPillarCalibTime m4 : 26|7@1+ (1,0) [0|512] "min" GTW
 SG_ APP_lPillarCalibProgress m4 : 33|7@1+ (1,0) [0|100] "percent" GTW
 SG_ APP_lPillarCalibrated m4 : 40|1@1+ (1,0) [0|1] "" GTW
 SG_ APP_rPillarCamExtPitchCal m5 : 8|9@1+ (0.05,-12.5) [-12.5|12.5] "deg" GTW
 SG_ APP_rPillarCamExtYawCal m5 : 17|9@1+ (0.05,-12.5) [-12.5|12.5] "deg" GTW
 SG_ APP_rPillarCalibTime m5 : 26|7@1+ (1,0) [0|512] "min" GTW
 SG_ APP_rPillarCalibProgress m5 : 33|7@1+ (1,0) [0|100] "percent" GTW
 SG_ APP_rPillarCalibrated m5 : 40|1@1+ (1,0) [0|1] "" GTW
 SG_ APP_lRepeatCamExtPitchCal m6 : 8|9@1+ (0.05,-12.5) [-12.5|12.5] "deg" GTW
 SG_ APP_lRepeatCamExtYawCal m6 : 17|9@1+ (0.05,-12.5) [-12.5|12.5] "deg" GTW
 SG_ APP_lRepeatCalibTime m6 : 26|7@1+ (1,0) [0|512] "min" GTW
 SG_ APP_lRepeatCalibProgress m6 : 33|7@1+ (1,0) [0|100] "percent" GTW
 SG_ APP_lRepeatCalibrated m6 : 40|1@1+ (1,0) [0|1] "" GTW
 SG_ APP_rRepeatCamExtPitchCal m7 : 8|9@1+ (0.05,-12.5) [-12.5|12.5] "deg" GTW
 SG_ APP_rRepeatCamExtYawCal m7 : 17|9@1+ (0.05,-12.5) [-12.5|12.5] "deg" GTW
 SG_ APP_rRepeatCalibTime m7 : 26|7@1+ (1,0) [0|512] "min" GTW
 SG_ APP_rRepeatCalibProgress m7 : 33|7@1+ (1,0) [0|100] "percent" GTW
 SG_ APP_rRepeatCalibrated m7 : 40|1@1+ (1,0) [0|1] "" GTW
 SG_ APP_backupCamExtPitchCal m8 : 8|9@1+ (0.05,-12.5) [-12.5|12.5] "deg" GTW
 SG_ APP_backupCamExtYawCal m8 : 17|9@1+ (0.05,-12.5) [-12.5|12.5] "deg" GTW
 SG_ APP_backupCalibTime m8 : 26|7@1+ (1,0) [0|512] "min" GTW
 SG_ APP_backupCalibProgress m8 : 33|7@1+ (1,0) [0|100] "percent" GTW
 SG_ APP_backupCalibrated m8 : 40|1@1+ (1,0) [0|1] "" GTW

BO_ 1017 APP_cameraLux: 8 APP
 SG_ APP_mainCameraLUX : 0|8@1+ (50,0) [0|12750] "lux" GTW
 SG_ APP_narrowCameraLUX : 8|8@1+ (50,0) [0|12750] "lux" GTW
 SG_ APP_fisheyeCameraLUX : 16|8@1+ (50,0) [0|12750] "lux" GTW
 SG_ APP_lRepeatCameraLUX : 24|8@1+ (50,0) [0|12750] "lux" GTW
 SG_ APP_rRepeatCameraLUX : 32|8@1+ (50,0) [0|12750] "lux" GTW
 SG_ APP_lPillarCameraLUX : 40|8@1+ (50,0) [0|12750] "lux" GTW
 SG_ APP_rPillarCameraLUX : 48|8@1+ (50,0) [0|12750] "lux" GTW
 SG_ APP_backupCameraLUX : 56|8@1+ (50,0) [0|12750] "lux" GTW

BO_ 1040 APP_cameraStatus: 1 APP
 SG_ APP_backupCameraFeedGood : 0|1@1+ (1,0) [0|1] "" GTW
 SG_ APP_backupCameraFrameRate : 1|6@1+ (1,0) [0|63] "" GTW

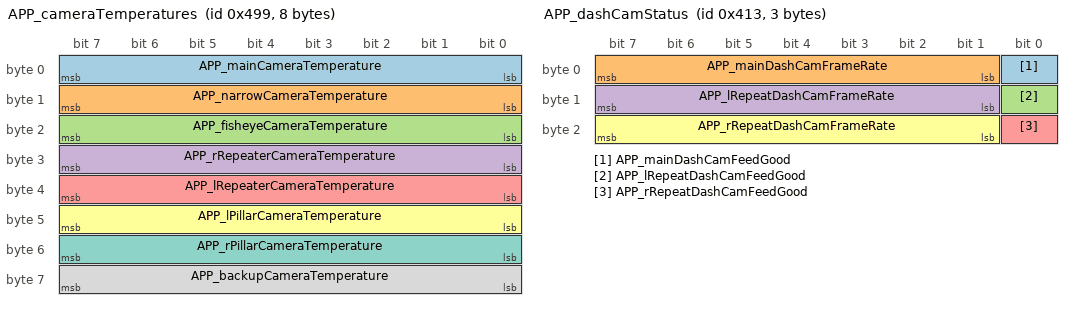
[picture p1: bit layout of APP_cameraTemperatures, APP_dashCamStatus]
BO_ 1177 APP_cameraTemperatures: 8 APP
 SG_ APP_mainCameraTemperature : 0|8@1+ (1,-60) [-60|195] "C" GTW
 SG_ APP_narrowCameraTemperature : 8|8@1+ (1,-60) [-60|195] "C" GTW
 SG_ APP_fisheyeCameraTemperature : 16|8@1+ (1,-60) [-60|195] "C" GTW
 SG_ APP_rRepeaterCameraTemperature : 24|8@1+ (1,-60) [-60|195] "C" GTW
 SG_ APP_lRepeaterCameraTemperature : 32|8@1+ (1,-60) [-60|195] "C" GTW
 SG_ APP_lPillarCameraTemperature : 40|8@1+ (1,-60) [-60|195] "C" GTW
 SG_ APP_rPillarCameraTemperature : 48|8@1+ (1,-60) [-60|195] "C" GTW
 SG_ APP_backupCameraTemperature : 56|8@1+ (1,-60) [-60|195] "C" GTW

BO_ 1043 APP_dashCamStatus: 3 APP
 SG_ APP_mainDashCamFeedGood : 0|1@1+ (1,0) [0|1] "" GTW
 SG_ APP_mainDashCamFrameRate : 1|7@1+ (1,0) [0|127] "" GTW
 SG_ APP_lRepeatDashCamFeedGood : 8|1@1+ (1,0) [0|1] "" GTW
 SG_ APP_lRepeatDashCamFrameRate : 9|7@1+ (1,0) [0|127] "" GTW
 SG_ APP_rRepeatDashCamFeedGood : 16|1@1+ (1,0) [0|1] "" GTW
 SG_ APP_rRepeatDashCamFrameRate : 17|7@1+ (1,0) [0|127] "" GTW

BO_ 608 APP_environment: 1 APP
 SG_ APP_environmentRainy : 0|1@1+ (1,0) [0|1] "" GTW,APS
 SG_ APP_environmentSnowy : 1|1@1+ (1,0) [0|1] "" GTW,APS

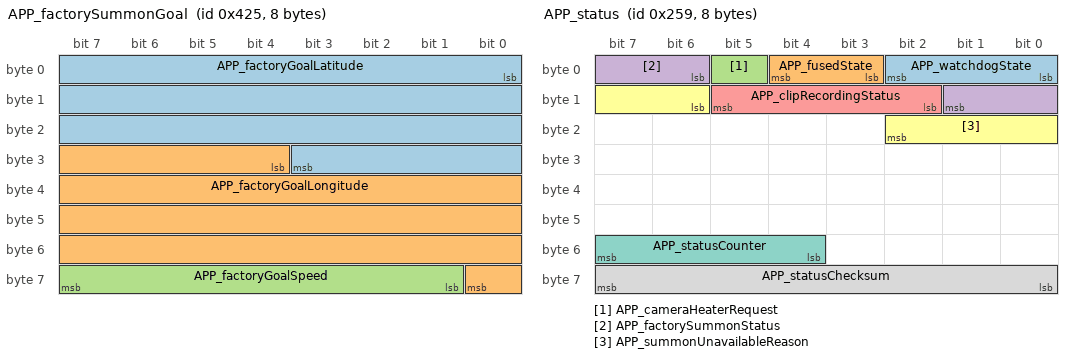
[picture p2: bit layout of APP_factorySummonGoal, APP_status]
BO_ 1061 APP_factorySummonGoal: 8 APP
 SG_ APP_factoryGoalLatitude : 0|28@1- (1E-06,0) [0|0] "deg" GTW
 SG_ APP_factoryGoalLongitude : 28|29@1- (1E-06,0) [0|0] "deg" GTW
 SG_ APP_factoryGoalSpeed : 57|7@1+ (1,0) [0|100] "mph" GTW

BO_ 714 APP_gpsTime: 8 APP
 SG_ APP_gpsSeconds : 0|32@1+ (1,0) [0|4294967295] "" Vector__XXX
 SG_ APP_gpsNanoseconds : 32|32@1+ (1,0) [0|4294967295] "" Vector__XXX

BO_ 1353 APP_info: 8 APP
 SG_ APP_infoIndex M : 0|8@1+ (1,0) [0|0] "" GTW,APS
 SG_ APP_buildType m0 : 8|8@1+ (1,0) [0|0] "" GTW,APS
 SG_ APP_infoAppFwGitHashBytes m1 : 8|56@1+ (1,0) [0|0] "" GTW,APS
 SG_ APP_infoAppApGitHashBytes m2 : 8|56@1+ (1,0) [0|0] "" GTW,APS

BO_ 601 APP_status: 8 APP
 SG_ APP_watchdogState : 0|3@1+ (1,0) [0|7] "" GTW,APS,APB
 SG_ APP_fusedState : 3|2@1+ (1,0) [0|3] "" GTW,APS
 SG_ APP_cameraHeaterRequest : 5|1@1+ (1,0) [0|1] "" GTW,APS
 SG_ APP_factorySummonStatus : 6|4@1+ (1,0) [0|15] "" GTW,APS
 SG_ APP_clipRecordingStatus : 10|4@1+ (1,0) [0|15] "" GTW,APS
 SG_ APP_summonUnavailableReason : 14|5@1+ (1,0) [0|21] "" GTW,APS
 SG_ APP_statusCounter : 52|4@1+ (1,0) [0|15] "" GTW,APS,APB
 SG_ APP_statusChecksum : 56|8@1+ (1,0) [0|255] "" GTW,APS,APB

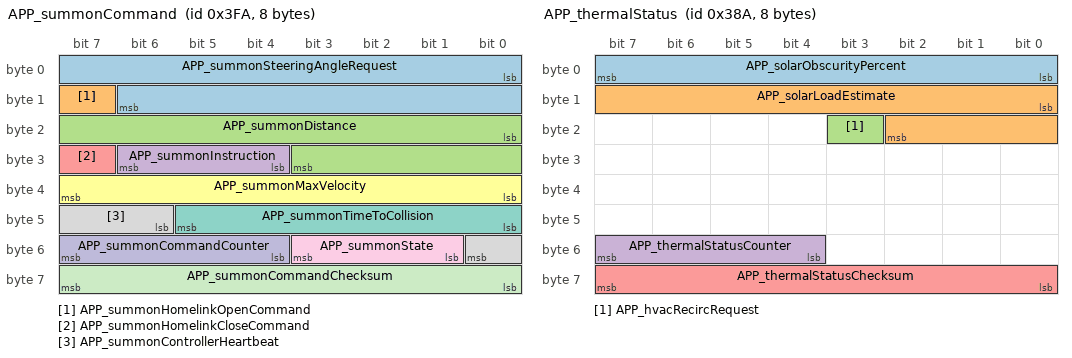
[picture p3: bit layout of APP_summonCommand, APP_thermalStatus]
BO_ 1018 APP_summonCommand: 8 APP
 SG_ APP_summonSteeringAngleRequest : 0|15@1+ (0.1,-1638.35) [-1638.35|1638.35] "deg" APS
 SG_ APP_summonHomelinkOpenCommand : 15|1@1+ (1,0) [0|1] "" APS
 SG_ APP_summonDistance : 16|12@1+ (0.01,0) [0|40.95] "m" APS
 SG_ APP_summonInstruction : 28|3@1+ (1,0) [0|7] "" APS
 SG_ APP_summonHomelinkCloseCommand : 31|1@1+ (1,0) [0|1] "" APS
 SG_ APP_summonMaxVelocity : 32|8@1+ (0.05,0) [0|12.7] "kph" APS
 SG_ APP_summonTimeToCollision : 40|6@1+ (0.1,0) [0|6.3] "s" APS
 SG_ APP_summonControllerHeartbeat : 46|3@1+ (1,0) [0|1] "" APS
 SG_ APP_summonState : 49|3@1+ (1,0) [0|7] "" APS
 SG_ APP_summonCommandCounter : 52|4@1+ (1,0) [0|0] "" APS
 SG_ APP_summonCommandChecksum : 56|8@1+ (1,0) [0|0] "" APS

BO_ 906 APP_thermalStatus: 8 APP
 SG_ APP_solarObscurityPercent : 0|8@1+ (0.5,-25) [-25|100] "%" GTW
 SG_ APP_solarLoadEstimate : 8|11@1+ (1,0) [0|1500] "W/m^2" GTW
 SG_ APP_hvacRecircRequest : 19|1@1+ (1,0) [0|1] "" GTW
 SG_ APP_thermalStatusCounter : 52|4@1+ (1,0) [0|0] "" GTW
 SG_ APP_thermalStatusChecksum : 56|8@1+ (1,0) [0|0] "" GTW

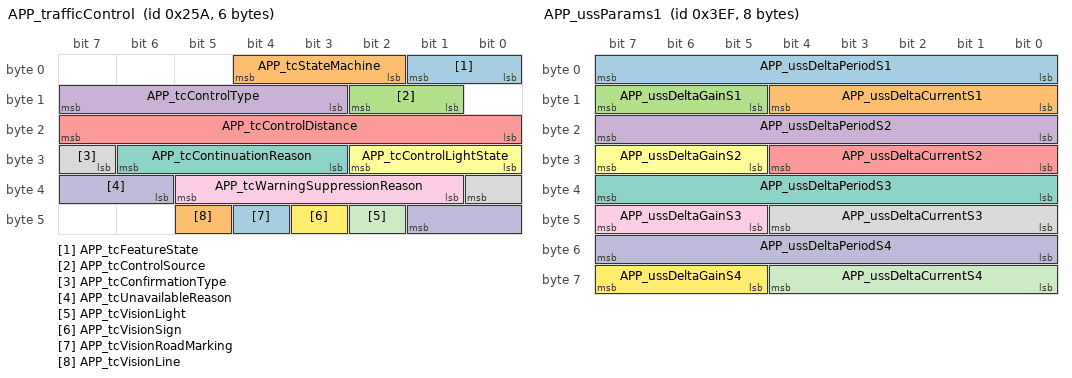
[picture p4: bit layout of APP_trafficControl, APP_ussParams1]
BO_ 602 APP_trafficControl: 6 APP
 SG_ APP_tcFeatureState : 0|2@1+ (1,0) [0|3] "" GTW
 SG_ APP_tcStateMachine : 2|3@1+ (1,0) [0|6] "" GTW
 SG_ APP_tcControlSource : 9|2@1+ (1,0) [0|3] "" GTW
 SG_ APP_tcControlType : 11|5@1+ (1,0) [0|22] "" GTW
 SG_ APP_tcControlDistance : 16|8@1+ (1,0) [0|255] "m" GTW
 SG_ APP_tcControlLightState : 24|3@1+ (1,0) [0|6] "" GTW
 SG_ APP_tcContinuationReason : 27|4@1+ (1,0) [0|14] "" GTW
 SG_ APP_tcConfirmationType : 31|2@1+ (1,0) [0|2] "" GTW
 SG_ APP_tcWarningSuppressionReason : 33|5@1+ (1,0) [0|17] "" GTW
 SG_ APP_tcUnavailableReason : 38|4@1+ (1,0) [0|15] "" GTW
 SG_ APP_tcVisionLight : 42|1@1+ (1,0) [0|1] "" GTW
 SG_ APP_tcVisionSign : 43|1@1+ (1,0) [0|1] "" GTW
 SG_ APP_tcVisionRoadMarking : 44|1@1+ (1,0) [0|1] "" GTW
 SG_ APP_tcVisionLine : 45|1@1+ (1,0) [0|1] "" GTW

BO_ 1007 APP_ussParams1: 8 APP
 SG_ APP_ussDeltaPeriodS1 : 0|8@1- (1,0) [-128|127] "" PARK
 SG_ APP_ussDeltaCurrentS1 : 8|5@1- (1,0) [-16|15] "" PARK
 SG_ APP_ussDeltaGainS1 : 13|3@1- (1,0) [-4|3] "" PARK
 SG_ APP_ussDeltaPeriodS2 : 16|8@1- (1,0) [-128|127] "" PARK
 SG_ APP_ussDeltaCurrentS2 : 24|5@1- (1,0) [-16|15] "" PARK
 SG_ APP_ussDeltaGainS2 : 29|3@1- (1,0) [-4|3] "" PARK
 SG_ APP_ussDeltaPeriodS3 : 32|8@1- (1,0) [-128|127] "" PARK
 SG_ APP_ussDeltaCurrentS3 : 40|5@1- (1,0) [-16|15] "" PARK
 SG_ APP_ussDeltaGainS3 : 45|3@1- (1,0) [-4|3] "" PARK
 SG_ APP_ussDeltaPeriodS4 : 48|8@1- (1,0) [-128|127] "" PARK
 SG_ APP_ussDeltaCurrentS4 : 56|5@1- (1,0) [-16|15] "" PARK
 SG_ APP_ussDeltaGainS4 : 61|3@1- (1,0) [-4|3] "" PARK

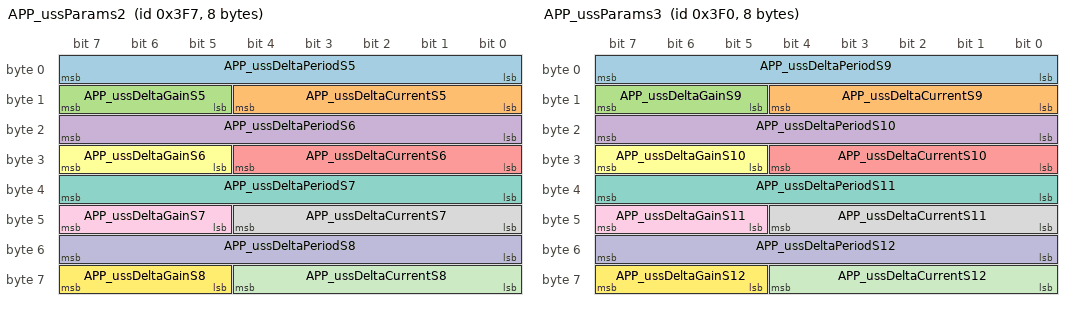
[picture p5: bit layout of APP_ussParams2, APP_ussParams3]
BO_ 1015 APP_ussParams2: 8 APP
 SG_ APP_ussDeltaPeriodS5 : 0|8@1- (1,0) [-128|127] "" PARK
 SG_ APP_ussDeltaCurrentS5 : 8|5@1- (1,0) [-16|15] "" PARK
 SG_ APP_ussDeltaGainS5 : 13|3@1- (1,0) [-4|3] "" PARK
 SG_ APP_ussDeltaPeriodS6 : 16|8@1- (1,0) [-128|127] "" PARK
 SG_ APP_ussDeltaCurrentS6 : 24|5@1- (1,0) [-16|15] "" PARK
 SG_ APP_ussDeltaGainS6 : 29|3@1- (1,0) [-4|3] "" PARK
 SG_ APP_ussDeltaPeriodS7 : 32|8@1- (1,0) [-128|127] "" PARK
 SG_ APP_ussDeltaCurrentS7 : 40|5@1- (1,0) [-16|15] "" PARK
 SG_ APP_ussDeltaGainS7 : 45|3@1- (1,0) [-4|3] "" PARK
 SG_ APP_ussDeltaPeriodS8 : 48|8@1- (1,0) [-128|127] "" PARK
 SG_ APP_ussDeltaCurrentS8 : 56|5@1- (1,0) [-16|15] "" PARK
 SG_ APP_ussDeltaGainS8 : 61|3@1- (1,0) [-4|3] "" PARK

BO_ 1008 APP_ussParams3: 8 APP
 SG_ APP_ussDeltaPeriodS9 : 0|8@1- (1,0) [-128|127] "" PARK
 SG_ APP_ussDeltaCurrentS9 : 8|5@1- (1,0) [-16|15] "" PARK
 SG_ APP_ussDeltaGainS9 : 13|3@1- (1,0) [-4|3] "" PARK
 SG_ APP_ussDeltaPeriodS10 : 16|8@1- (1,0) [-128|127] "" PARK
 SG_ APP_ussDeltaCurrentS10 : 24|5@1- (1,0) [-16|15] "" PARK
 SG_ APP_ussDeltaGainS10 : 29|3@1- (1,0) [-4|3] "" PARK
 SG_ APP_ussDeltaPeriodS11 : 32|8@1- (1,0) [-128|127] "" PARK
 SG_ APP_ussDeltaCurrentS11 : 40|5@1- (1,0) [-16|15] "" PARK
 SG_ APP_ussDeltaGainS11 : 45|3@1- (1,0) [-4|3] "" PARK
 SG_ APP_ussDeltaPeriodS12 : 48|8@1- (1,0) [-128|127] "" PARK
 SG_ APP_ussDeltaCurrentS12 : 56|5@1- (1,0) [-16|15] "" PARK
 SG_ APP_ussDeltaGainS12 : 61|3@1- (1,0) [-4|3] "" PARK

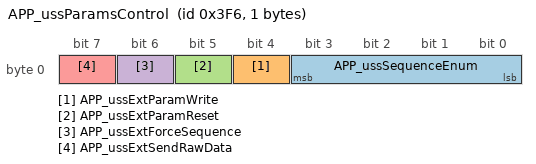
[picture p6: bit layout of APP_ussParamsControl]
BO_ 1014 APP_ussParamsControl: 1 APP
 SG_ APP_ussSequenceEnum : 0|4@1+ (1,0) [0|0] "" PARK
 SG_ APP_ussExtParamWrite : 4|1@1+ (1,0) [0|0] "" PARK
 SG_ APP_ussExtParamReset : 5|1@1+ (1,0) [0|0] "" PARK
 SG_ APP_ussExtForceSequence : 6|1@1+ (1,0) [0|1] "" PARK
 SG_ APP_ussExtSendRawData : 7|1@1+ (1,0) [0|1] "" PARK

BO_ 1097 APP_warningMatrix0: 8 APP
 SG_ APP_w002_ldwDisabled : 1|1@1+ (1,0) [0|1] "" GTW,MCU
 SG_ APP_w003_isaDisabled : 2|1@1+ (1,0) [0|1] "" GTW,MCU
 SG_ APP_w004_accDisabled : 3|1@1+ (1,0) [0|1] "" GTW,MCU
 SG_ APP_w005_fcwCancelled : 4|1@1+ (1,0) [0|1] "" GTW,MCU
 SG_ APP_w006_aebCancelled : 5|1@1+ (1,0) [0|1] "" GTW,MCU
 SG_ APP_w007_ahlbDisabled : 6|1@1+ (1,0) [0|1] "" GTW,MCU
 SG_ APP_w008_parkDisabled : 7|1@1+ (1,0) [0|1] "" GTW,MCU
 SG_ APP_w009_aebFault : 8|1@1+ (1,0) [0|1] "" GTW,MCU
 SG_ APP_w010_radcCalibIssue : 9|1@1+ (1,0) [0|0] "" GTW,MCU
 SG_ APP_w011_scaEvent : 10|1@1+ (1,0) [0|0] "" GTW,MCU
 SG_ APP_w012_Cam_BootFailure : 11|1@1+ (1,0) [0|0] "" GTW,MCU
 SG_ APP_w013_Cam_Watchdog : 12|1@1+ (1,0) [0|0] "" GTW,MCU
 SG_ APP_w014_swAssert : 13|1@1+ (1,0) [0|0] "" GTW,MCU
 SG_ APP_w015_Camera_Failsafes : 14|1@1+ (1,0) [0|0] "" GTW,MCU
 SG_ APP_w016_aeb_e_event : 15|1@1+ (1,0) [0|0] "" GTW,MCU
 SG_ APP_w017_Cam_Msg_MIA : 16|1@1+ (1,0) [0|0] "" GTW,MCU
 SG_ APP_w018_ECU_Power_Issue : 17|1@1+ (1,0) [0|0] "" GTW,MCU
 SG_ APP_w019_ECU_Stack_Overflow : 18|1@1+ (1,0) [0|0] "" GTW,MCU
 SG_ APP_w020_ECU_checkstopError : 19|1@1+ (1,0) [0|0] "" GTW,MCU
 SG_ APP_w021_ECU_Temperature_Issue : 20|1@1+ (1,0) [0|0] "" GTW,MCU
 SG_ APP_w022_ECU_EEPROM_Failure : 21|1@1+ (1,0) [0|0] "" GTW,MCU
 SG_ APP_w023_ECU_Cam_Statemismatc : 22|1@1+ (1,0) [0|0] "" GTW,MCU
 SG_ APP_w024_ECU_Watchdog_Reset : 23|1@1+ (1,0) [0|0] "" GTW,MCU
 SG_ APP_w025_LC_Steering_Override : 24|1@1+ (1,0) [0|0] "" GTW,MCU
 SG_ APP_w026_ECU_timingIssue : 25|1@1+ (1,0) [0|0] "" GTW,MCU
 SG_ APP_w027_ECU_Reset_Fault : 26|1@1+ (1,0) [0|0] "" GTW,MCU
 SG_ APP_w028_spi_rx_error : 27|1@1+ (1,0) [0|0] "" GTW,MCU
 SG_ APP_w029_spi_tx_error : 28|1@1+ (1,0) [0|0] "" GTW,MCU
 SG_ APP_w030_Heater_Issue : 29|1@1+ (1,0) [0|0] "" GTW,MCU
 SG_ APP_w031_canRxError : 30|1@1+ (1,0) [0|0] "" GTW,MCU
 SG_ APP_w032_canTxError : 31|1@1+ (1,0) [0|0] "" GTW,MCU
 SG_ APP_w033_gtwMia : 32|1@1+ (1,0) [0|0] "" GTW,MCU
 SG_ APP_w034_sccmMia : 33|1@1+ (1,0) [0|0] "" GTW,MCU
 SG_ APP_w035_espMia : 34|1@1+ (1,0) [0|0] "" GTW,MCU
 SG_ APP_w036_bdyMia : 35|1@1+ (1,0) [0|0] "" GTW,MCU
 SG_ APP_w037_camTacIssue : 36|1@1+ (1,0) [0|0] "" GTW,MCU
 SG_ APP_w038_camFailure : 37|1@1+ (1,0) [0|0] "" GTW,MCU
 SG_ APP_w039_sdm_rcm_Mia : 38|1@1+ (1,0) [0|0] "" GTW,MCU
 SG_ APP_w040_autopilotAngleSaturated : 39|1@1+ (1,0) [0|0] "" GTW,MCU
 SG_ APP_w041_autopilotRateSaturated : 40|1@1+ (1,0) [0|0] "" GTW,MCU
 SG_ APP_w042_autopilotAborting : 41|1@1+ (1,0) [0|1] "" GTW,MCU
 SG_ APP_w043_camLongRunTime : 42|1@1+ (1,0) [0|1] "" GTW,MCU
 SG_ APP_w044_appMobileyeFailure : 43|1@1+ (1,0) [0|0] "" GTW,MCU
 SG_ APP_w045_radMia : 44|1@1+ (1,0) [0|0] "" GTW,MCU
 SG_ APP_w046_eepromRecordAbsent : 45|1@1+ (1,0) [0|1] "" GTW,MCU
 SG_ APP_w047_edrEvent : 46|1@1+ (1,0) [0|0] "" GTW,MCU
 SG_ APP_w048_APP_Features_Disabled : 47|1@1+ (1,0) [0|0] "" GTW,MCU
 SG_ APP_w049_eyeqVersionMismatch : 48|1@1+ (1,0) [0|1] "" GTW,MCU
 SG_ APP_w050_aeb_event : 49|1@1+ (1,0) [0|1] "" GTW,MCU
 SG_ APP_w051_radcEcuIssue : 50|1@1+ (1,0) [0|1] "" GTW,MCU
 SG_ APP_w052_radcSensorIssue : 51|1@1+ (1,0) [0|1] "" GTW,MCU
 SG_ APP_w053_radcCommIssue : 52|1@1+ (1,0) [0|1] "" GTW,MCU
 SG_ APP_w054_camAutofix : 53|1@1+ (1,0) [0|1] "" GTW,MCU
 SG_ APP_w055_radcVersionMismatch : 54|1@1+ (1,0) [0|1] "" GTW,MCU
 SG_ APP_w056_diMia : 55|1@1+ (1,0) [0|1] "" GTW,MCU
 SG_ APP_w057_mcuMia : 56|1@1+ (1,0) [0|1] "" GTW,MCU
 SG_ APP_w058_epbMia : 57|1@1+ (1,0) [0|1] "" GTW,MCU
 SG_ APP_w059_parkMia : 58|1@1+ (1,0) [0|1] "" GTW,MCU
 SG_ APP_w060_fcw_event : 59|1@1+ (1,0) [0|1] "" GTW,MCU
 SG_ APP_w061_airSuspensionMia : 60|1@1+ (1,0) [0|1] "" GTW,MCU
 SG_ APP_w062_radcAlignment : 61|1@1+ (1,0) [0|1] "" GTW,MCU
 SG_ APP_w063_parkVersionMismatch : 62|1@1+ (1,0) [0|1] "" GTW,MCU
 SG_ APP_w064_epasMia : 63|1@1+ (1,0) [0|1] "" GTW,MCU

BO_ 1049 APP_warningMatrix1: 8 APP
 SG_ APP_w065_deserializerOvercurrent : 0|1@1+ (1,0) [0|1] "" GTW,MCU
 SG_ APP_w066_deserializerLockLost : 1|1@1+ (1,0) [0|1] "" GTW,MCU
 SG_ APP_w067_steeringAlignment : 2|1@1+ (1,0) [0|1] "" GTW,MCU
 SG_ APP_w068_vlInconsistency : 3|1@1+ (1,0) [0|1] "" GTW,MCU
 SG_ APP_w069_apcSpaceMasked : 4|1@1+ (1,0) [0|1] "" GTW,MCU
 SG_ APP_w070_apcIncompleteCal : 5|1@1+ (1,0) [0|1] "" GTW,MCU
 SG_ APP_w071_selfparkStarted : 6|1@1+ (1,0) [0|1] "" GTW,MCU
 SG_ APP_w072_selfparkComplete : 7|1@1+ (1,0) [0|1] "" GTW,MCU
 SG_ APP_w073_issueEscalatedLDW : 8|1@1+ (1,0) [0|1] "" GTW,MCU
 SG_ APP_w074_inPathStationaryObst : 9|1@1+ (1,0) [0|1] "" GTW,MCU
 SG_ APP_w075_scMia : 10|1@1+ (1,0) [0|1] "" GTW,MCU
 SG_ APP_w076_mobilEyeSetC : 11|1@1+ (1,0) [0|1] "" GTW,MCU
 SG_ APP_w077_pmmActive : 12|1@1+ (1,0) [0|1] "" GTW,MCU
 SG_ APP_w078_pmmActive2 : 13|1@1+ (1,0) [0|1] "" GTW,MCU
 SG_ APP_w079_edrAvailable : 14|1@1+ (1,0) [0|1] "" GTW,MCU
 SG_ APP_w080_accFailedActivation : 15|1@1+ (1,0) [0|1] "" GTW,MCU
 SG_ APP_w081_pmmActiveBraking : 16|1@1+ (1,0) [0|1] "" GTW,MCU
 SG_ APP_w082_inPathFSviolation : 17|1@1+ (1,0) [0|1] "" GTW,MCU
 SG_ APP_w083_inPathRADObject : 18|1@1+ (1,0) [0|1] "" GTW,MCU
 SG_ APP_w084_pmmIPSO : 19|1@1+ (1,0) [0|1] "" GTW,MCU
 SG_ APP_w085_pmmSteering : 20|1@1+ (1,0) [0|1] "" GTW,MCU
 SG_ APP_w086_robCollision : 21|1@1+ (1,0) [0|1] "" GTW,MCU
 SG_ APP_w087_DEPRECATED : 22|1@1+ (1,0) [0|1] "" GTW,MCU
 SG_ APP_w088_DEPRECATED : 23|1@1+ (1,0) [0|1] "" GTW,MCU
 SG_ APP_w089_DEPRECATED : 24|1@1+ (1,0) [0|1] "" GTW,MCU
 SG_ APP_w090_DEPRECATED : 25|1@1+ (1,0) [0|1] "" GTW,MCU
 SG_ APP_w091_DEPRECATED : 26|1@1+ (1,0) [0|1] "" GTW,MCU
 SG_ APP_w092_DEPRECATED : 27|1@1+ (1,0) [0|1] "" GTW,MCU
 SG_ APP_w093_DEPRECATED : 28|1@1+ (1,0) [0|1] "" GTW,MCU
 SG_ APP_w094_DEPRECATED : 29|1@1+ (1,0) [0|1] "" GTW,MCU
 SG_ APP_w095_DEPRECATED : 30|1@1+ (1,0) [0|1] "" GTW,MCU
 SG_ APP_w096_DEPRECATED : 31|1@1+ (1,0) [0|1] "" GTW,MCU
 SG_ APP_w097_DEPRECATED : 32|1@1+ (1,0) [0|1] "" GTW,MCU
 SG_ APP_w098_DEPRECATED : 33|1@1+ (1,0) [0|1] "" GTW,MCU
 SG_ APP_w099_DEPRECATED : 34|1@1+ (1,0) [0|1] "" GTW,MCU
 SG_ APP_w100_DEPRECATED : 35|1@1+ (1,0) [0|1] "" GTW,MCU
 SG_ APP_w101_DEPRECATED : 36|1@1+ (1,0) [0|1] "" GTW,MCU
 SG_ APP_w102_DEPRECATED : 37|1@1+ (1,0) [0|1] "" GTW,MCU
 SG_ APP_w103_robExperimentalAEB : 38|1@1+ (1,0) [0|1] "" GTW,MCU
 SG_ APP_w104_DEPRECATED : 39|1@1+ (1,0) [0|1] "" GTW,MCU
 SG_ APP_w105_DEPRECATED : 40|1@1+ (1,0) [0|1] "" GTW,MCU
 SG_ APP_w106_torsionBarCalibrated : 41|1@1+ (1,0) [0|1] "" GTW,MCU

BO_ 1065 APP_warningMatrix2: 8 APP
 SG_ APP_w129_mainCamExtNotCal : 0|1@1+ (1,0) [0|1] "" GTW,MCU
 SG_ APP_w130_narrowCamExtNotCal : 1|1@1+ (1,0) [0|1] "" GTW,MCU
 SG_ APP_w131_mainCamCalSaved : 2|1@1+ (1,0) [0|1] "" GTW,MCU
 SG_ APP_w132_narrowCamCalSaved : 3|1@1+ (1,0) [0|1] "" GTW,MCU
 SG_ APP_w133_mainCamInitFault : 4|1@1+ (1,0) [0|1] "" GTW,MCU
 SG_ APP_w134_narrowCamInitFault : 5|1@1+ (1,0) [0|1] "" GTW,MCU
 SG_ APP_w135_fisheyeCamInitFault : 6|1@1+ (1,0) [0|1] "" GTW,MCU
 SG_ APP_w136_lPillarCamInitFault : 7|1@1+ (1,0) [0|1] "" GTW,MCU
 SG_ APP_w137_rPillarCamInitFault : 8|1@1+ (1,0) [0|1] "" GTW,MCU
 SG_ APP_w138_lRepeatCamInitFault : 9|1@1+ (1,0) [0|1] "" GTW,MCU
 SG_ APP_w139_rRepeatCamInitFault : 10|1@1+ (1,0) [0|1] "" GTW,MCU
 SG_ APP_w140_backupCamInitFault : 11|1@1+ (1,0) [0|1] "" GTW,MCU
 SG_ APP_w141_ECU_Thermal_Issue : 12|1@1+ (1,0) [0|1] "" GTW,MCU
 SG_ APP_w142_fwdCamPitchProblem : 13|1@1+ (1,0) [0|1] "" GTW,MCU
 SG_ APP_w143_IDF_event : 14|1@1+ (1,0) [0|1] "" GTW,MCU
 SG_ APP_w144_fanctrldError : 15|1@1+ (1,0) [0|1] "" GTW,MCU
 SG_ APP_w145_camSelfCalIssue : 16|1@1+ (1,0) [0|1] "" GTW,MCU
 SG_ APP_w146_telemetryProblem : 17|1@1+ (1,0) [0|1] "" GTW,MCU
 SG_ APP_w147_selfieCamInitFault : 18|1@1+ (1,0) [0|1] "" GTW,MCU
 SG_ APP_w148_overlayActive : 19|1@1+ (1,0) [0|1] "" GTW,MCU
 SG_ APP_w149_diskFull : 20|1@1+ (1,0) [0|1] "" GTW,MCU
 SG_ APP_w161_backupCameraUnavailable : 32|1@1+ (1,0) [0|1] "" GTW,MCU
 SG_ APP_w162_mainCameraTypeError : 33|1@1+ (1,0) [0|1] "" GTW,MCU
 SG_ APP_w163_narrowCameraTypeError : 34|1@1+ (1,0) [0|1] "" GTW,MCU
 SG_ APP_w164_fisheyeCameraTypeError : 35|1@1+ (1,0) [0|1] "" GTW,MCU
 SG_ APP_w165_lPillarCameraTypeError : 36|1@1+ (1,0) [0|1] "" GTW,MCU
 SG_ APP_w166_rPillarCameraTypeError : 37|1@1+ (1,0) [0|1] "" GTW,MCU
 SG_ APP_w167_lRepeatCameraTypeError : 38|1@1+ (1,0) [0|1] "" GTW,MCU
 SG_ APP_w168_rRepeatCameraTypeError : 39|1@1+ (1,0) [0|1] "" GTW,MCU
 SG_ APP_w169_backupCameraTypeError : 40|1@1+ (1,0) [0|1] "" GTW,MCU
 SG_ APP_w170_selfieCameraTypeError : 41|1@1+ (1,0) [0|1] "" GTW,MCU
 SG_ APP_w172_fisheyeCamExtNotCal : 43|1@1+ (1,0) [0|1] "" GTW,MCU
 SG_ APP_w173_lPillarCamExtNotCal : 44|1@1+ (1,0) [0|1] "" GTW,MCU
 SG_ APP_w174_rPillarCamExtNotCal : 45|1@1+ (1,0) [0|1] "" GTW,MCU
 SG_ APP_w175_lRepeatCamExtNotCal : 46|1@1+ (1,0) [0|1] "" GTW,MCU
 SG_ APP_w176_rRepeatCamExtNotCal : 47|1@1+ (1,0) [0|1] "" GTW,MCU
 SG_ APP_w177_fisheyeCamCalSaved : 48|1@1+ (1,0) [0|1] "" GTW,MCU
 SG_ APP_w178_lPillarCamCalSaved : 49|1@1+ (1,0) [0|1] "" GTW,MCU
 SG_ APP_w179_rPillarCamCalSaved : 50|1@1+ (1,0) [0|1] "" GTW,MCU
 SG_ APP_w180_lRepeatCamCalSaved : 51|1@1+ (1,0) [0|1] "" GTW,MCU
 SG_ APP_w181_rRepeatCamCalSaved : 52|1@1+ (1,0) [0|1] "" GTW,MCU
 SG_ APP_w182_mainCameraStreamExit : 53|1@1+ (1,0) [0|1] "" GTW,MCU
 SG_ APP_w183_narrowCameraStreamExit : 54|1@1+ (1,0) [0|1] "" GTW,MCU
 SG_ APP_w184_fisheyeCameraStreamExit : 55|1@1+ (1,0) [0|1] "" GTW,MCU
 SG_ APP_w185_lPillarCameraStreamExit : 56|1@1+ (1,0) [0|1] "" GTW,MCU
 SG_ APP_w186_rPillarCameraStreamExit : 57|1@1+ (1,0) [0|1] "" GTW,MCU
 SG_ APP_w187_lRepeatCameraStreamExit : 58|1@1+ (1,0) [0|1] "" GTW,MCU
 SG_ APP_w188_rRepeatCameraStreamExit : 59|1@1+ (1,0) [0|1] "" GTW,MCU
 SG_ APP_w189_backupCameraStreamExit : 60|1@1+ (1,0) [0|1] "" GTW,MCU
 SG_ APP_w190_selfieCameraStreamExit : 61|1@1+ (1,0) [0|1] "" GTW,MCU
 SG_ APP_w191_autopilotAborting : 62|1@1+ (1,0) [0|1] "" GTW,MCU
 SG_ APP_w192_emergencySpeakerFail : 63|1@1+ (1,0) [0|1] "" GTW,MCU

BO_ 1081 APP_warningMatrix3: 8 APP
 SG_ APP_w193_camWindshieldUnclean : 0|1@1+ (1,0) [0|0] "" GTW,MCU
 SG_ APP_w194_accDriverResumeRqrd : 1|1@1+ (1,0) [0|0] "" GTW,MCU
 SG_ APP_w195_scwUnavailable : 2|1@1+ (1,0) [0|0] "" GTW,MCU
 SG_ APP_w196_stopSignWarning : 3|1@1+ (1,0) [0|0] "" GTW,MCU
 SG_ APP_w197_redLightWarning : 4|1@1+ (1,0) [0|0] "" GTW,MCU
 SG_ APP_w198_tsrUnavailable : 5|1@1+ (1,0) [0|0] "" GTW,MCU
 SG_ APP_w199_apcAbort : 6|1@1+ (1,0) [0|0] "" GTW,MCU
 SG_ APP_w200_lcSlowdown : 7|1@1+ (1,0) [0|0] "" GTW,MCU
 SG_ APP_w201_lcAborting : 8|1@1+ (1,0) [0|0] "" GTW,MCU
 SG_ APP_w202_scwNoisyEnvironment : 9|1@1+ (1,0) [0|0] "" GTW,MCU
 SG_ APP_w203_apcActivation : 10|1@1+ (1,0) [0|0] "" GTW,MCU
 SG_ APP_w204_apcFinalFront : 11|1@1+ (1,0) [0|0] "" GTW,MCU
 SG_ APP_w205_apcFinalRear : 12|1@1+ (1,0) [0|0] "" GTW,MCU
 SG_ APP_w206_autosteerNotEnabled : 13|1@1+ (1,0) [0|0] "" GTW,MCU
 SG_ APP_w207_autosteerUnavailable : 14|1@1+ (1,0) [0|0] "" GTW,MCU
 SG_ APP_w208_rackDetected : 15|1@1+ (1,0) [0|0] "" GTW,MCU
 SG_ APP_w209_autoSummonRequest : 16|1@1+ (1,0) [0|0] "" GTW,MCU
 SG_ APP_w210_camObstrcted : 17|1@1+ (1,0) [0|0] "" GTW,MCU
 SG_ APP_w211_accNoSeatBelt : 18|1@1+ (1,0) [0|0] "" GTW,MCU
 SG_ APP_w212_lcUnavailableStrikeOut : 19|1@1+ (1,0) [0|0] "" GTW,MCU
 SG_ APP_w213_autosteerStruckOut : 20|1@1+ (1,0) [0|0] "" GTW,MCU
 SG_ APP_w214_driverNotIntracting : 21|1@1+ (1,0) [0|0] "" GTW,MCU
 SG_ APP_w215_contDriverNotIntracting : 22|1@1+ (1,0) [0|0] "" GTW,MCU
 SG_ APP_w216_driverOverriding : 23|1@1+ (1,0) [0|0] "" GTW,MCU
 SG_ APP_w217_lcUnavailableSpeeding : 24|1@1+ (1,0) [0|0] "" GTW,MCU
 SG_ APP_w218_lcSpeedExceededLimit : 25|1@1+ (1,0) [0|0] "" GTW,MCU
 SG_ APP_w219_lcTempUnavailableSpeed : 26|1@1+ (1,0) [0|0] "" GTW,MCU
 SG_ APP_w220_lcTempUnavailableRoad : 27|1@1+ (1,0) [0|0] "" GTW,MCU
 SG_ APP_w221_accRadarBlind : 28|1@1+ (1,0) [0|0] "" GTW,MCU
 SG_ APP_w222_accCameraBlind : 29|1@1+ (1,0) [0|0] "" GTW,MCU
 SG_ APP_w223_accObjectInPath : 30|1@1+ (1,0) [0|0] "" GTW,MCU
 SG_ APP_w224_accCameraCalibration : 31|1@1+ (1,0) [0|0] "" GTW,MCU
 SG_ APP_w225_lcDegradedVisSpeedLmt : 32|1@1+ (1,0) [0|0] "" GTW,MCU
 SG_ APP_w226_lcCamCalNeededSpeedLmt : 33|1@1+ (1,0) [0|0] "" GTW,MCU
 SG_ APP_w227_virtualWallBlocked : 34|1@1+ (1,0) [0|0] "" GTW,MCU
 SG_ APP_w228_DEPRECATED : 35|1@1+ (1,0) [0|0] "" GTW,MCU
 SG_ APP_w229_alcUltrasoundDamaged : 36|1@1+ (1,0) [0|1] "" GTW,MCU
 SG_ APP_w230_alcUltrasoundBlocked : 37|1@1+ (1,0) [0|1] "" GTW,MCU
 SG_ APP_w231_idfEvent : 38|1@1+ (1,0) [0|1] "" GTW,MCU
 SG_ APP_w232_laneChangeRequested : 39|1@1+ (1,0) [0|1] "" GTW,MCU
 SG_ APP_w233_laneChangeCancelled : 40|1@1+ (1,0) [0|1] "" GTW,MCU

BO_ 1129 APP_warningMatrix4: 8 APP
 SG_ APP_w257_brakeJerkEvent : 0|1@1+ (1,0) [0|1] "" GTW,MCU
 SG_ APP_w258_aebEvent : 1|1@1+ (1,0) [0|1] "" GTW,MCU
 SG_ APP_w259_aebOverrideEvent : 2|1@1+ (1,0) [0|1] "" GTW,MCU
 SG_ APP_w260_collisionWarningEvent : 3|1@1+ (1,0) [0|1] "" GTW,MCU
 SG_ APP_w261_pcieHardwareErrors : 4|1@1+ (1,0) [0|1] "" GTW,MCU
 SG_ APP_w262_apeCalibMode : 5|1@1+ (1,0) [0|1] "" GTW,MCU
 SG_ APP_w263_lssAbort : 6|1@1+ (1,0) [0|1] "" GTW,MCU
 SG_ APP_w264_lssFault : 7|1@1+ (1,0) [0|1] "" GTW,MCU
 SG_ APP_w265_drvOnNavUnavailable : 8|1@1+ (1,0) [0|1] "" GTW,MCU
 SG_ APP_w266_visionScheduleFallback : 9|1@1+ (1,0) [0|1] "" GTW,MCU
 SG_ APP_w267_benchtopEcu : 10|1@1+ (1,0) [0|1] "" GTW,MCU
 SG_ APP_w268_backupCamExtNotCal : 11|1@1+ (1,0) [0|1] "" GTW,MCU
 SG_ APP_w269_autopilotLimited : 12|1@1+ (1,0) [0|1] "" GTW,MCU
 SG_ APP_w270_blindspotRestricted : 13|1@1+ (1,0) [0|1] "" GTW,MCU
 SG_ APP_w271_laneChangeAborted : 14|1@1+ (1,0) [0|1] "" GTW,MCU
 SG_ APP_w272_laneChangeUnavailable : 15|1@1+ (1,0) [0|1] "" GTW,MCU
 SG_ APP_w273_lssEvent : 16|1@1+ (1,0) [0|1] "" GTW,MCU
 SG_ APP_w274_mainCameraStreamErr : 17|1@1+ (1,0) [0|1] "" GTW,MCU
 SG_ APP_w275_narrowCameraStreamErr : 18|1@1+ (1,0) [0|1] "" GTW,MCU
 SG_ APP_w276_fisheyeCameraStreamErr : 19|1@1+ (1,0) [0|1] "" GTW,MCU
 SG_ APP_w277_lPillarCameraStreamErr : 20|1@1+ (1,0) [0|1] "" GTW,MCU
 SG_ APP_w278_rPillarCameraStreamErr : 21|1@1+ (1,0) [0|1] "" GTW,MCU
 SG_ APP_w279_lRepeatCameraStreamErr : 22|1@1+ (1,0) [0|1] "" GTW,MCU
 SG_ APP_w280_rRepeatCameraStreamErr : 23|1@1+ (1,0) [0|1] "" GTW,MCU
 SG_ APP_w281_backupCameraStreamErr : 24|1@1+ (1,0) [0|1] "" GTW,MCU
 SG_ APP_w282_selfieCameraStreamErr : 25|1@1+ (1,0) [0|1] "" GTW,MCU
 SG_ APP_w283_enhancedSummonAbort : 26|1@1+ (1,0) [0|1] "" GTW,MCU
 SG_ APP_w284_gpsAntennaDisconnected : 27|1@1+ (1,0) [0|1] "" GTW,MCU
 SG_ APP_w285_gpsFaultReset : 28|1@1+ (1,0) [0|1] "" GTW,MCU
 SG_ APP_w286_gpsComIssue : 29|1@1+ (1,0) [0|1] "" GTW,MCU
 SG_ APP_w287_gpsFusionStatus : 30|1@1+ (1,0) [0|1] "" GTW,MCU
 SG_ APP_w288_trafficLightWarning : 31|1@1+ (1,0) [0|1] "" GTW,MCU
 SG_ APP_w289_dramCorrEccErrors : 32|1@1+ (1,0) [0|1] "" GTW,MCU
 SG_ APP_w290_dramUncorrEccErrors : 33|1@1+ (1,0) [0|1] "" GTW,MCU
 SG_ APP_w291_stopSignWarning : 34|1@1+ (1,0) [0|1] "" GTW,MCU
 SG_ APP_w292_vcseatMIA : 35|1@1+ (1,0) [0|1] "" GTW,MCU
 SG_ APP_w293_mainCameraSyncFailed : 36|1@1+ (1,0) [0|1] "" GTW,MCU
 SG_ APP_w294_narrowCameraSyncFailed : 37|1@1+ (1,0) [0|1] "" GTW,MCU
 SG_ APP_w295_fisheyeCameraSyncFailed : 38|1@1+ (1,0) [0|1] "" GTW,MCU
 SG_ APP_w296_lPillarCameraSyncFailed : 39|1@1+ (1,0) [0|1] "" GTW,MCU
 SG_ APP_w297_rPillarCameraSyncFailed : 40|1@1+ (1,0) [0|1] "" GTW,MCU
 SG_ APP_w298_lRepeatCameraSyncFailed : 41|1@1+ (1,0) [0|1] "" GTW,MCU
 SG_ APP_w299_rRepeatCameraSyncFailed : 42|1@1+ (1,0) [0|1] "" GTW,MCU
 SG_ APP_w300_backupCameraSyncFailed : 43|1@1+ (1,0) [0|1] "" GTW,MCU
 SG_ APP_w301_selfieCameraSyncFailed : 44|1@1+ (1,0) [0|1] "" GTW,MCU
 SG_ APP_w303_imuIrational : 46|1@1+ (1,0) [0|1] "" GTW,MCU
 SG_ APP_w304_lssCamBlockedStatus : 47|1@1+ (1,0) [0|1] "" GTW,MCU
 SG_ APP_w305_lssCamStreamExit : 48|1@1+ (1,0) [0|1] "" GTW,MCU
 SG_ APP_w306_lssUltrasonicsBlocked : 49|1@1+ (1,0) [0|1] "" GTW,MCU
 SG_ APP_w307_lssTurnSignalFault : 50|1@1+ (1,0) [0|1] "" GTW,MCU
 SG_ APP_w309_selfieDisabledOnCar : 52|1@1+ (1,0) [0|1] "" GTW,MCU
 SG_ APP_w310_eth0FrameErrors : 53|1@1+ (1,0) [0|1] "" GTW,MCU
 SG_ APP_w311_eth1FrameErrors : 54|1@1+ (1,0) [0|1] "" GTW,MCU
 SG_ APP_w312_mainCamTypeMismatch : 55|1@1+ (1,0) [0|1] "" GTW,MCU
 SG_ APP_w313_narrowCamTypeMismatch : 56|1@1+ (1,0) [0|1] "" GTW,MCU
 SG_ APP_w314_fisheyeCamTypeMismatch : 57|1@1+ (1,0) [0|1] "" GTW,MCU
 SG_ APP_w315_lPillarCamTypeMismatch : 58|1@1+ (1,0) [0|1] "" GTW,MCU
 SG_ APP_w316_rPillarCamTypeMismatch : 59|1@1+ (1,0) [0|1] "" GTW,MCU
 SG_ APP_w317_lRepeatCamTypeMismatch : 60|1@1+ (1,0) [0|1] "" GTW,MCU
 SG_ APP_w318_rRepeatCamTypeMismatch : 61|1@1+ (1,0) [0|1] "" GTW,MCU
 SG_ APP_w319_backupCamTypeMismatch : 62|1@1+ (1,0) [0|1] "" GTW,MCU
 SG_ APP_w320_selfieCamTypeMismatch : 63|1@1+ (1,0) [0|1] "" GTW,MCU

CM_ SG_ 1513 APP_sw182_currentTemperature "Last known temprature of image sensor";
CM_ SG_ 1513 APP_sw182_minTemperature "Minimum recorded temperature of image sensor";
CM_ SG_ 1513 APP_sw182_maxTemperature "Maximum recorded temperature of image sensor";
CM_ SG_ 1513 APP_sw183_currentTemperature "Last known temprature of image sensor";
CM_ SG_ 1513 APP_sw183_minTemperature "Minimum recorded temperature of image sensor";
CM_ SG_ 1513 APP_sw183_maxTemperature "Maximum recorded temperature of image sensor";
CM_ SG_ 1513 APP_sw184_currentTemperature "Last known temprature of image sensor";
CM_ SG_ 1513 APP_sw184_minTemperature "Minimum recorded temperature of image sensor";
CM_ SG_ 1513 APP_sw184_maxTemperature "Maximum recorded temperature of image sensor";
CM_ SG_ 1513 APP_sw185_currentTemperature "Last known temprature of image sensor";
CM_ SG_ 1513 APP_sw185_minTemperature "Minimum recorded temperature of image sensor";
CM_ SG_ 1513 APP_sw185_maxTemperature "Maximum recorded temperature of image sensor";
CM_ SG_ 1513 APP_sw186_currentTemperature "Last known temprature of image sensor";
CM_ SG_ 1513 APP_sw186_minTemperature "Minimum recorded temperature of image sensor";
CM_ SG_ 1513 APP_sw186_maxTemperature "Maximum recorded temperature of image sensor";
CM_ SG_ 1513 APP_sw187_currentTemperature "Last known temprature of image sensor";
CM_ SG_ 1513 APP_sw187_minTemperature "Minimum recorded temperature of image sensor";
CM_ SG_ 1513 APP_sw187_maxTemperature "Maximum recorded temperature of image sensor";
CM_ SG_ 1513 APP_sw188_currentTemperature "Last known temprature of image sensor";
CM_ SG_ 1513 APP_sw188_minTemperature "Minimum recorded temperature of image sensor";
CM_ SG_ 1513 APP_sw188_maxTemperature "Maximum recorded temperature of image sensor";
CM_ SG_ 1513 APP_sw189_currentTemperature "Last known temprature of image sensor";
CM_ SG_ 1513 APP_sw189_minTemperature "Minimum recorded temperature of image sensor";
CM_ SG_ 1513 APP_sw189_maxTemperature "Maximum recorded temperature of image sensor";
CM_ SG_ 1513 APP_sw190_currentTemperature "Last known temprature of image sensor";
CM_ SG_ 1513 APP_sw190_minTemperature "Minimum recorded temperature of image sensor";
CM_ SG_ 1513 APP_sw190_maxTemperature "Maximum recorded temperature of image sensor";
CM_ SG_ 1513 APP_sw194_timeInHold "Time in ms since ACC entered HOLD state";
CM_ SG_ 1513 APP_sw274_currentTemperature "Last known temprature of image sensor";
CM_ SG_ 1513 APP_sw274_minTemperature "Minimum recorded temperature of image sensor";
CM_ SG_ 1513 APP_sw274_maxTemperature "Maximum recorded temperature of image sensor";
CM_ SG_ 1513 APP_sw275_currentTemperature "Last known temprature of image sensor";
CM_ SG_ 1513 APP_sw275_minTemperature "Minimum recorded temperature of image sensor";
CM_ SG_ 1513 APP_sw275_maxTemperature "Maximum recorded temperature of image sensor";
CM_ SG_ 1513 APP_sw276_currentTemperature "Last known temprature of image sensor";
CM_ SG_ 1513 APP_sw276_minTemperature "Minimum recorded temperature of image sensor";
CM_ SG_ 1513 APP_sw276_maxTemperature "Maximum recorded temperature of image sensor";
CM_ SG_ 1513 APP_sw277_currentTemperature "Last known temprature of image sensor";
CM_ SG_ 1513 APP_sw277_minTemperature "Minimum recorded temperature of image sensor";
CM_ SG_ 1513 APP_sw277_maxTemperature "Maximum recorded temperature of image sensor";
CM_ SG_ 1513 APP_sw278_currentTemperature "Last known temprature of image sensor";
CM_ SG_ 1513 APP_sw278_minTemperature "Minimum recorded temperature of image sensor";
CM_ SG_ 1513 APP_sw278_maxTemperature "Maximum recorded temperature of image sensor";
CM_ SG_ 1513 APP_sw279_currentTemperature "Last known temprature of image sensor";
CM_ SG_ 1513 APP_sw279_minTemperature "Minimum recorded temperature of image sensor";
CM_ SG_ 1513 APP_sw279_maxTemperature "Maximum recorded temperature of image sensor";
CM_ SG_ 1513 APP_sw280_currentTemperature "Last known temprature of image sensor";
CM_ SG_ 1513 APP_sw280_minTemperature "Minimum recorded temperature of image sensor";
CM_ SG_ 1513 APP_sw280_maxTemperature "Maximum recorded temperature of image sensor";
CM_ SG_ 1513 APP_sw281_currentTemperature "Last known temprature of image sensor";
CM_ SG_ 1513 APP_sw281_minTemperature "Minimum recorded temperature of image sensor";
CM_ SG_ 1513 APP_sw281_maxTemperature "Maximum recorded temperature of image sensor";
CM_ SG_ 1513 APP_sw282_currentTemperature "Last known temprature of image sensor";
CM_ SG_ 1513 APP_sw282_minTemperature "Minimum recorded temperature of image sensor";
CM_ SG_ 1513 APP_sw282_maxTemperature "Maximum recorded temperature of image sensor";
CM_ SG_ 1020 APP_decisionTemperature "Rolling average of Parker and Pascal temperature.";
CM_ SG_ 1020 APP_pascalTemperature "Temperature of Autopilot GPU";
CM_ SG_ 1020 APP_parkerATemperature "Temperature of Autopilot CPU(1)";
CM_ SG_ 1020 APP_parkerBTemperature "Temperature of Autopilot CPU(1)";
CM_ SG_ 1020 APP_pascalExtTemperature "External temperature of Autopilot GPU";
CM_ SG_ 1020 APP_parkerExtTemperature "External temperature of Parker";
CM_ SG_ 714 APP_gpsSeconds "GPS time, integer seconds";
CM_ SG_ 714 APP_gpsNanoseconds "GPS time, integer nanoseconds";
CM_ SG_ 601 APP_statusChecksum "Checksum method for APP_status: sum of all bytes in message + originating CAN ID (0x2 + 0x09 = 0xB)";
CM_ SG_ 602 APP_tcFeatureState "The feature level state of stopping for traffic controls";
CM_ SG_ 602 APP_tcStateMachine "The traffic control state machine's internal control state.";
CM_ SG_ 602 APP_tcControlSource "The input data source for the traffic control object";
CM_ SG_ 602 APP_tcControlType "The specific type of traffic control, note not all are control worthy.";
CM_ SG_ 602 APP_tcControlDistance "The distance to the nearest critical traffic control object.";
CM_ SG_ 602 APP_tcControlLightState "The color of the light of the most relevant traffic control if the traffic control is a light.";
CM_ SG_ 602 APP_tcContinuationReason "The reason the traffic control state machine entered the continue state.";
CM_ SG_ 602 APP_tcConfirmationType "The mechanism of how the driver confirmed the traffic control.";
CM_ SG_ 602 APP_tcWarningSuppressionReason "The suppression reason for the traffic control warning feature.";
CM_ SG_ 602 APP_tcUnavailableReason "The reason why the traffic control feature is currently unavailable.";
CM_ SG_ 602 APP_tcVisionLight "Whether or not the traffic light has a vision measurement.";
CM_ SG_ 602 APP_tcVisionSign "Whether or not the traffic sign has a vision measurement.";
CM_ SG_ 602 APP_tcVisionRoadMarking "Whether or not the road marking has a vision measurement.";
CM_ SG_ 602 APP_tcVisionLine "Whether or not the traffic control line has a vision measurement.";
BA_DEF_ BO_ "AlertLogSubSystemId" INT 0 0;
BA_DEF_ BO_ "AlertType" INT 0 4;
BA_DEF_ BO_ "AppBotschaft" ENUM "nein","ja";
BA_DEF_ BO_ "DiagRequest" ENUM "No","Yes";
BA_DEF_ BO_ "DiagResponse" ENUM "No","Yes";
BA_DEF_ BO_ "ETHGatewayMessageSendType" ENUM "UseGenMsgSendType","onWrite","noAutoCode";
BA_DEF_ BO_ "ETHId" STRING ;
BA_DEF_ BO_ "GatewayHandlerEnum" ENUM "noHandler","uds","alertLog","messageLogOnReception","udsClient";
BA_DEF_ BO_ "GatewayMessageAtomic" ENUM "No","Yes";
BA_DEF_ BO_ "GatewayMessageSendType" ENUM "UseGenMsgSendType","onWrite","noAutoCode";
BA_DEF_ BO_ "GenMsgCycleTime" INT 0 0;
BA_DEF_ BO_ "GenMsgCycleTimeFast" INT 0 0;
BA_DEF_ BO_ "GenMsgDelayTime" INT 0 0;
BA_DEF_ BO_ "GenMsgForceMiaCheck" ENUM "No","Yes";
BA_DEF_ BO_ "GenMsgGatewayNotification" STRING ;
BA_DEF_ BO_ "GenMsgILSupport" ENUM "No","Yes";
BA_DEF_ BO_ "GenMsgSaltingFunction" ENUM "No","Yes";
BA_DEF_ BO_ "GenMsgSendType" ENUM "Cyclic","NotUsed","NotUsed","NotUsed","NotUsed","NotUsed","NotUsed","IfActive","NoMsgSendType","Sporadic";
BA_DEF_ BO_ "GenMsgStartValue" STRING ;
BA_DEF_ BO_ "GenMsgTimeOut" INT 0 0;
BA_DEF_ BO_ "MessageIdType" ENUM "normal","udsRequest","udsResponse","udsReserved","udsFunctionalRequest","networkManagement","bootloader","xcp","dtc","diagnostic","vendorExempt";
BA_DEF_ BO_ "NWMBotschaft" ENUM "nein","ja";
BA_DEF_ BO_ "NmMessage" ENUM "No","Yes";
BA_DEF_ BO_ "SubSystemId" INT 0 256;
BA_DEF_ BO_ "UsesChecksum" ENUM "No","Yes";
BA_DEF_ SG_ "FieldType" STRING ;
BA_DEF_ SG_ "FlexKomComment" STRING ;
BA_DEF_ SG_ "FlexKomIsMotorola" ENUM "nein","ja";
BA_DEF_ SG_ "FlexKomSID" INT 0 2147483647;
BA_DEF_ SG_ "FlexKomSigLaenge" INT 0 64;
BA_DEF_ SG_ "FlexKomSigName" STRING ;
BA_DEF_ SG_ "FlexKomSigStartPos" INT 0 63;
BA_DEF_ SG_ "FlexKomSigStartValue" STRING ;
BA_DEF_ SG_ "Gatewaysignal" INT 0 1;
BA_DEF_ SG_ "GenSigCycleTime" INT 0 0;
BA_DEF_ SG_ "GenSigCycleTimeActive" INT 0 0;
BA_DEF_ SG_ "GenSigPersistent" ENUM "No","Yes";
BA_DEF_ SG_ "GenSigSNA" STRING ;
BA_DEF_ SG_ "GenSigSendType" ENUM "Cyclic","OnWrite","OnWriteWithRepetition","OnChange","OnChangeWithRepetition","IfActive","IfActiveWithRepetition","NoSigSendType","NotUsed","NotUsed","NotUsed","NotUsed","NotUsed";
BA_DEF_ SG_ "GenSigStartValue" INT 0 0;
BA_DEF_ SG_ "GenSigTimeout_CGW" INT 0 65535;
BA_DEF_ SG_ "GenSigTimeout_DRVU" INT 0 65535;
BA_DEF_ SG_ "GenSigTimeout_ECM" INT 0 65535;
BA_DEF_ SG_ "GenSigTimeout_EIS" INT 0 65535;
BA_DEF_ SG_ "GenSigTimeout_EPS" INT 0 65535;
BA_DEF_ SG_ "GenSigTimeout_ESP_ABR" INT 0 65535;
BA_DEF_ SG_ "GenSigTimeout_IC" INT 0 65535;
BA_DEF_ SG_ "GenSigTimeout_MPC" INT 0 65535;
BA_DEF_ SG_ "GenSigTimeout_NV" INT 0 65535;
BA_DEF_ SG_ "GenSigTimeout_ORC" INT 0 65535;
BA_DEF_ SG_ "GenSigTimeout_PTS" INT 0 65535;
BA_DEF_ SG_ "GenSigTimeout_RBTM_FL" INT 0 65535;
BA_DEF_ SG_ "GenSigTimeout_RBTM_FR" INT 0 65535;
BA_DEF_ SG_ "GenSigTimeout_RDU" INT 0 65535;
BA_DEF_ SG_ "GenSigTimeout_SCCM" INT 0 65535;
BA_DEF_ SG_ "GenSigTimeout_SPC" INT 0 65535;
BA_DEF_ SG_ "GenSigTimeout_TPM" INT 0 65535;
BA_DEF_ SG_ "LogSignal" STRING ;
BA_DEF_ SG_ "PektronUpdateBitType" ENUM "Not used","Has update bit","Is update bit";
BA_DEF_REL_ BU_SG_REL_ "GenSigTimeoutTime" INT 0 0;

BA_DEF_DEF_ "AlertLogSubSystemId" 0;
BA_DEF_DEF_ "AlertType" 4;
BA_DEF_DEF_ "AppBotschaft" "nein";
BA_DEF_DEF_ "DiagRequest" "No";
BA_DEF_DEF_ "DiagResponse" "No";
BA_DEF_DEF_ "ETHGatewayMessageSendType" "UseGenMsgSendType";
BA_DEF_DEF_ "ETHId" "";
BA_DEF_DEF_ "FieldType" "";
BA_DEF_DEF_ "FlexKomComment" "";
BA_DEF_DEF_ "FlexKomIsMotorola" "";
BA_DEF_DEF_ "FlexKomSID" 0;
BA_DEF_DEF_ "FlexKomSigLaenge" 0;
BA_DEF_DEF_ "FlexKomSigName" "";
BA_DEF_DEF_ "FlexKomSigStartPos" 0;
BA_DEF_DEF_ "FlexKomSigStartValue" "";
BA_DEF_DEF_ "GatewayHandlerEnum" "noHandler";
BA_DEF_DEF_ "GatewayMessageAtomic" "No";
BA_DEF_DEF_ "GatewayMessageSendType" "UseGenMsgSendType";
BA_DEF_DEF_ "Gatewaysignal" 0;
BA_DEF_DEF_ "GenMsgCycleTime" 0;
BA_DEF_DEF_ "GenMsgCycleTimeFast" 0;
BA_DEF_DEF_ "GenMsgDelayTime" 0;
BA_DEF_DEF_ "GenMsgForceMiaCheck" "No";
BA_DEF_DEF_ "GenMsgGatewayNotification" "";
BA_DEF_DEF_ "GenMsgILSupport" "Yes";
BA_DEF_DEF_ "GenMsgSaltingFunction" "No";
BA_DEF_DEF_ "GenMsgSendType" "Cyclic";
BA_DEF_DEF_ "GenMsgStartValue" "";
BA_DEF_DEF_ "GenMsgTimeOut" 0;
BA_DEF_DEF_ "GenSigCycleTime" 0;
BA_DEF_DEF_ "GenSigCycleTimeActive" 0;
BA_DEF_DEF_ "GenSigPersistent" "No";
BA_DEF_DEF_ "GenSigSNA" "";
BA_DEF_DEF_ "GenSigSendType" "Cyclic";
BA_DEF_DEF_ "GenSigStartValue" 0;
BA_DEF_DEF_ "GenSigTimeout_CGW" 0;
BA_DEF_DEF_ "GenSigTimeout_DRVU" 0;
BA_DEF_DEF_ "GenSigTimeout_ECM" 0;
BA_DEF_DEF_ "GenSigTimeout_EIS" 0;
BA_DEF_DEF_ "GenSigTimeout_EPS" 0;
BA_DEF_DEF_ "GenSigTimeout_ESP_ABR" 0;
BA_DEF_DEF_ "GenSigTimeout_IC" 0;
BA_DEF_DEF_ "GenSigTimeout_MPC" 0;
BA_DEF_DEF_ "GenSigTimeout_NV" 0;
BA_DEF_DEF_ "GenSigTimeout_ORC" 0;
BA_DEF_DEF_ "GenSigTimeout_PTS" 0;
BA_DEF_DEF_ "GenSigTimeout_RBTM_FL" 0;
BA_DEF_DEF_ "GenSigTimeout_RBTM_FR" 0;
BA_DEF_DEF_ "GenSigTimeout_RDU" 0;
BA_DEF_DEF_ "GenSigTimeout_SCCM" 0;
BA_DEF_DEF_ "GenSigTimeout_SPC" 0;
BA_DEF_DEF_ "GenSigTimeout_TPM" 0;
BA_DEF_DEF_ "LogSignal" "";
BA_DEF_DEF_ "MessageIdType" "normal";
BA_DEF_DEF_ "NWMBotschaft" "nein";
BA_DEF_DEF_ "NmMessage" "No";
BA_DEF_DEF_ "PektronUpdateBitType" "Not used";
BA_DEF_DEF_ "SubSystemId" 0;
BA_DEF_DEF_ "UsesChecksum" "No";
BA_DEF_DEF_REL_ "GenSigTimeoutTime" 0;
BA_ "GatewayMessageSendType" BO_ 1045 1;
BA_ "GenMsgCycleTime" BO_ 1045 500;
BA_ "GenMsgCycleTime" BO_ 1020 1000;
BA_ "GenMsgCycleTime" BO_ 1010 1000;
BA_ "GatewayMessageSendType" BO_ 1017 1;
BA_ "GenMsgCycleTime" BO_ 1017 500;
BA_ "GatewayMessageSendType" BO_ 1040 1;
BA_ "GenMsgCycleTime" BO_ 1040 500;
BA_ "GenMsgCycleTime" BO_ 1177 1000;
BA_ "GatewayMessageSendType" BO_ 1043 1;
BA_ "GenMsgCycleTime" BO_ 1043 500;
BA_ "GatewayMessageSendType" BO_ 608 1;
BA_ "GenMsgCycleTime" BO_ 608 1000;
BA_ "GenMsgCycleTime" BO_ 1061 1000;
BA_ "GenMsgSendType" BO_ 1061 1;
BA_ "GenMsgCycleTime" BO_ 714 1000;
BA_ "GenMsgCycleTime" BO_ 1353 1000;
BA_ "GenMsgTimeOut" BO_ 1353 1000;
BA_ "GatewayMessageSendType" BO_ 601 1;
BA_ "GenMsgCycleTime" BO_ 601 100;
BA_ "GenMsgCycleTime" BO_ 1018 40;
BA_ "GatewayMessageSendType" BO_ 906 1;
BA_ "GenMsgCycleTime" BO_ 906 1000;
BA_ "GatewayMessageSendType" BO_ 602 1;
BA_ "GenMsgCycleTime" BO_ 602 500;
BA_ "GenMsgSendType" BO_ 1007 9;
BA_ "GenMsgSendType" BO_ 1015 9;
BA_ "GenMsgSendType" BO_ 1008 9;
BA_ "GenMsgSendType" BO_ 1014 9;
BA_ "AlertType" BO_ 1097 0;
BA_ "ETHId" BO_ 1097 "RETAIN_ID";
BA_ "GatewayMessageSendType" BO_ 1097 1;
BA_ "GenMsgCycleTime" BO_ 1097 1000;
BA_ "AlertType" BO_ 1049 0;
BA_ "ETHId" BO_ 1049 "RETAIN_ID";
BA_ "GatewayMessageSendType" BO_ 1049 1;
BA_ "GenMsgCycleTime" BO_ 1049 1000;
BA_ "AlertType" BO_ 1065 0;
BA_ "ETHId" BO_ 1065 "RETAIN_ID";
BA_ "GatewayMessageSendType" BO_ 1065 1;
BA_ "GenMsgCycleTime" BO_ 1065 1000;
BA_ "AlertType" BO_ 1081 1;
BA_ "ETHId" BO_ 1081 "RETAIN_ID";
BA_ "GatewayMessageSendType" BO_ 1081 1;
BA_ "GenMsgCycleTime" BO_ 1081 1000;
BA_ "AlertType" BO_ 1129 0;
BA_ "ETHId" BO_ 1129 "RETAIN_ID";
BA_ "GatewayMessageSendType" BO_ 1129 1;
BA_ "GenMsgCycleTime" BO_ 1129 1000;
BA_ "FieldType" SG_ 1513 APP_sw144_fanctrldErrorType "FanctrldError";
BA_ "FieldType" SG_ 1513 APP_sw145_problemCamPosition "APP_cameraPosition";
BA_ "FieldType" SG_ 1513 APP_sw147_selfieCamDeserFault "I2C_fault";
BA_ "FieldType" SG_ 1513 APP_sw147_selfieCamSerFault "I2C_fault";
BA_ "FieldType" SG_ 1513 APP_sw147_selfieCamSensorFault "I2C_fault";
BA_ "FieldType" SG_ 1513 APP_sw162_detectedColorFilter "APP_cameraColorFilter";
BA_ "FieldType" SG_ 1513 APP_sw162_expectedColorFilter "APP_cameraColorFilter";
BA_ "FieldType" SG_ 1513 APP_sw162_detectedPosition "APP_cameraPosition";
BA_ "FieldType" SG_ 1513 APP_sw163_detectedColorFilter "APP_cameraColorFilter";
BA_ "FieldType" SG_ 1513 APP_sw163_expectedColorFilter "APP_cameraColorFilter";
BA_ "FieldType" SG_ 1513 APP_sw163_detectedPosition "APP_cameraPosition";
BA_ "FieldType" SG_ 1513 APP_sw164_detectedColorFilter "APP_cameraColorFilter";
BA_ "FieldType" SG_ 1513 APP_sw164_expectedColorFilter "APP_cameraColorFilter";
BA_ "FieldType" SG_ 1513 APP_sw164_detectedPosition "APP_cameraPosition";
BA_ "FieldType" SG_ 1513 APP_sw165_detectedColorFilter "APP_cameraColorFilter";
BA_ "FieldType" SG_ 1513 APP_sw165_expectedColorFilter "APP_cameraColorFilter";
BA_ "FieldType" SG_ 1513 APP_sw165_detectedPosition "APP_cameraPosition";
BA_ "FieldType" SG_ 1513 APP_sw166_detectedColorFilter "APP_cameraColorFilter";
BA_ "FieldType" SG_ 1513 APP_sw166_expectedColorFilter "APP_cameraColorFilter";
BA_ "FieldType" SG_ 1513 APP_sw166_detectedPosition "APP_cameraPosition";
BA_ "FieldType" SG_ 1513 APP_sw167_detectedColorFilter "APP_cameraColorFilter";
BA_ "FieldType" SG_ 1513 APP_sw167_expectedColorFilter "APP_cameraColorFilter";
BA_ "FieldType" SG_ 1513 APP_sw167_detectedPosition "APP_cameraPosition";
BA_ "FieldType" SG_ 1513 APP_sw168_detectedColorFilter "APP_cameraColorFilter";
BA_ "FieldType" SG_ 1513 APP_sw168_expectedColorFilter "APP_cameraColorFilter";
BA_ "FieldType" SG_ 1513 APP_sw168_detectedPosition "APP_cameraPosition";
BA_ "FieldType" SG_ 1513 APP_sw169_detectedColorFilter "APP_cameraColorFilter";
BA_ "FieldType" SG_ 1513 APP_sw169_expectedColorFilter "APP_cameraColorFilter";
BA_ "FieldType" SG_ 1513 APP_sw169_detectedPosition "APP_cameraPosition";
BA_ "FieldType" SG_ 1513 APP_sw170_detectedColorFilter "APP_cameraColorFilter";
BA_ "FieldType" SG_ 1513 APP_sw170_expectedColorFilter "APP_cameraColorFilter";
BA_ "FieldType" SG_ 1513 APP_sw170_detectedPosition "APP_cameraPosition";
BA_ "FieldType" SG_ 1513 APP_sw182_exitStatus "CameraStreamExitStatus";
BA_ "FieldType" SG_ 1513 APP_sw182_tempMonitorFailure "CameraTemperatureMonitorFailure";
BA_ "FieldType" SG_ 1513 APP_sw182_imagerHeartbeat "ImagerHeartbeat";
BA_ "GenSigSNA" SG_ 1513 APP_sw182_imagerHeartbeat "3";
BA_ "GenSigSNA" SG_ 1513 APP_sw182_serializerCrcErrCount "255";
BA_ "GenSigSNA" SG_ 1513 APP_sw182_currentTemperature "255";
BA_ "GenSigSNA" SG_ 1513 APP_sw182_minTemperature "255";
BA_ "GenSigSNA" SG_ 1513 APP_sw182_maxTemperature "255";
BA_ "FieldType" SG_ 1513 APP_sw183_exitStatus "CameraStreamExitStatus";
BA_ "FieldType" SG_ 1513 APP_sw183_tempMonitorFailure "CameraTemperatureMonitorFailure";
BA_ "FieldType" SG_ 1513 APP_sw183_imagerHeartbeat "ImagerHeartbeat";
BA_ "GenSigSNA" SG_ 1513 APP_sw183_imagerHeartbeat "3";
BA_ "GenSigSNA" SG_ 1513 APP_sw183_serializerCrcErrCount "255";
BA_ "GenSigSNA" SG_ 1513 APP_sw183_currentTemperature "255";
BA_ "GenSigSNA" SG_ 1513 APP_sw183_minTemperature "255";
BA_ "GenSigSNA" SG_ 1513 APP_sw183_maxTemperature "255";
BA_ "FieldType" SG_ 1513 APP_sw184_exitStatus "CameraStreamExitStatus";
BA_ "FieldType" SG_ 1513 APP_sw184_tempMonitorFailure "CameraTemperatureMonitorFailure";
BA_ "FieldType" SG_ 1513 APP_sw184_imagerHeartbeat "ImagerHeartbeat";
BA_ "GenSigSNA" SG_ 1513 APP_sw184_imagerHeartbeat "3";
BA_ "GenSigSNA" SG_ 1513 APP_sw184_serializerCrcErrCount "255";
BA_ "GenSigSNA" SG_ 1513 APP_sw184_currentTemperature "255";
BA_ "GenSigSNA" SG_ 1513 APP_sw184_minTemperature "255";
BA_ "GenSigSNA" SG_ 1513 APP_sw184_maxTemperature "255";
BA_ "FieldType" SG_ 1513 APP_sw185_exitStatus "CameraStreamExitStatus";
BA_ "FieldType" SG_ 1513 APP_sw185_tempMonitorFailure "CameraTemperatureMonitorFailure";
BA_ "FieldType" SG_ 1513 APP_sw185_imagerHeartbeat "ImagerHeartbeat";
BA_ "GenSigSNA" SG_ 1513 APP_sw185_imagerHeartbeat "3";
BA_ "GenSigSNA" SG_ 1513 APP_sw185_serializerCrcErrCount "255";
BA_ "GenSigSNA" SG_ 1513 APP_sw185_currentTemperature "255";
BA_ "GenSigSNA" SG_ 1513 APP_sw185_minTemperature "255";
BA_ "GenSigSNA" SG_ 1513 APP_sw185_maxTemperature "255";
BA_ "FieldType" SG_ 1513 APP_sw186_exitStatus "CameraStreamExitStatus";
BA_ "FieldType" SG_ 1513 APP_sw186_tempMonitorFailure "CameraTemperatureMonitorFailure";
BA_ "FieldType" SG_ 1513 APP_sw186_imagerHeartbeat "ImagerHeartbeat";
BA_ "GenSigSNA" SG_ 1513 APP_sw186_imagerHeartbeat "3";
BA_ "GenSigSNA" SG_ 1513 APP_sw186_serializerCrcErrCount "255";
BA_ "GenSigSNA" SG_ 1513 APP_sw186_currentTemperature "255";
BA_ "GenSigSNA" SG_ 1513 APP_sw186_minTemperature "255";
BA_ "GenSigSNA" SG_ 1513 APP_sw186_maxTemperature "255";
BA_ "FieldType" SG_ 1513 APP_sw187_exitStatus "CameraStreamExitStatus";
BA_ "FieldType" SG_ 1513 APP_sw187_tempMonitorFailure "CameraTemperatureMonitorFailure";
BA_ "FieldType" SG_ 1513 APP_sw187_imagerHeartbeat "ImagerHeartbeat";
BA_ "GenSigSNA" SG_ 1513 APP_sw187_imagerHeartbeat "3";
BA_ "GenSigSNA" SG_ 1513 APP_sw187_serializerCrcErrCount "255";
BA_ "GenSigSNA" SG_ 1513 APP_sw187_currentTemperature "255";
BA_ "GenSigSNA" SG_ 1513 APP_sw187_minTemperature "255";
BA_ "GenSigSNA" SG_ 1513 APP_sw187_maxTemperature "255";
BA_ "FieldType" SG_ 1513 APP_sw188_exitStatus "CameraStreamExitStatus";
BA_ "FieldType" SG_ 1513 APP_sw188_tempMonitorFailure "CameraTemperatureMonitorFailure";
BA_ "FieldType" SG_ 1513 APP_sw188_imagerHeartbeat "ImagerHeartbeat";
BA_ "GenSigSNA" SG_ 1513 APP_sw188_imagerHeartbeat "3";
BA_ "GenSigSNA" SG_ 1513 APP_sw188_serializerCrcErrCount "255";
BA_ "GenSigSNA" SG_ 1513 APP_sw188_currentTemperature "255";
BA_ "GenSigSNA" SG_ 1513 APP_sw188_minTemperature "255";
BA_ "GenSigSNA" SG_ 1513 APP_sw188_maxTemperature "255";
BA_ "FieldType" SG_ 1513 APP_sw189_exitStatus "CameraStreamExitStatus";
BA_ "FieldType" SG_ 1513 APP_sw189_tempMonitorFailure "CameraTemperatureMonitorFailure";
BA_ "FieldType" SG_ 1513 APP_sw189_imagerHeartbeat "ImagerHeartbeat";
BA_ "GenSigSNA" SG_ 1513 APP_sw189_imagerHeartbeat "3";
BA_ "GenSigSNA" SG_ 1513 APP_sw189_serializerCrcErrCount "255";
BA_ "GenSigSNA" SG_ 1513 APP_sw189_currentTemperature "255";
BA_ "GenSigSNA" SG_ 1513 APP_sw189_minTemperature "255";
BA_ "GenSigSNA" SG_ 1513 APP_sw189_maxTemperature "255";
BA_ "FieldType" SG_ 1513 APP_sw190_exitStatus "CameraStreamExitStatus";
BA_ "FieldType" SG_ 1513 APP_sw190_tempMonitorFailure "CameraTemperatureMonitorFailure";
BA_ "FieldType" SG_ 1513 APP_sw190_imagerHeartbeat "ImagerHeartbeat";
BA_ "GenSigSNA" SG_ 1513 APP_sw190_imagerHeartbeat "3";
BA_ "GenSigSNA" SG_ 1513 APP_sw190_serializerCrcErrCount "255";
BA_ "GenSigSNA" SG_ 1513 APP_sw190_currentTemperature "255";
BA_ "GenSigSNA" SG_ 1513 APP_sw190_minTemperature "255";
BA_ "GenSigSNA" SG_ 1513 APP_sw190_maxTemperature "255";
BA_ "GenSigSNA" SG_ 1513 APP_sw191_handsOnState "15";
BA_ "GenSigSNA" SG_ 1513 APP_sw191_epasErrorCode "15";
BA_ "GenSigSNA" SG_ 1513 APP_sw194_leadDx "255";
BA_ "GenSigSNA" SG_ 1513 APP_sw194_leadVx "31";
BA_ "GenSigSNA" SG_ 1513 APP_sw194_leadAx "31";
BA_ "GenSigSNA" SG_ 1513 APP_sw194_reasonForHold "15";
BA_ "GenSigSNA" SG_ 1513 APP_sw199_abortCodePARK "31";
BA_ "GenSigSNA" SG_ 1513 APP_sw203_roadClass "0";
BA_ "GenSigSNA" SG_ 1513 APP_sw203_controlType "15";
BA_ "GenSigSNA" SG_ 1513 APP_sw204_frLeftMiddle "255";
BA_ "GenSigSNA" SG_ 1513 APP_sw204_frRightMiddle "255";
BA_ "GenSigSNA" SG_ 1513 APP_sw204_frRight "255";
BA_ "GenSigSNA" SG_ 1513 APP_sw204_frLeft "255";
BA_ "GenSigSNA" SG_ 1513 APP_sw204_frMiddle "255";
BA_ "GenSigSNA" SG_ 1513 APP_sw205_rrRightMiddle "255";
BA_ "GenSigSNA" SG_ 1513 APP_sw205_rrLeftMiddle "255";
BA_ "GenSigSNA" SG_ 1513 APP_sw205_rrRight "255";
BA_ "GenSigSNA" SG_ 1513 APP_sw205_rrLeft "255";
BA_ "GenSigSNA" SG_ 1513 APP_sw205_rrMiddle "255";
BA_ "GenSigSNA" SG_ 1513 APP_sw205_oocDistance "255";
BA_ "FieldType" SG_ 1513 APP_sw207_lcUnavailableReason "LC_unavailableReason";
BA_ "GenSigSNA" SG_ 1513 APP_sw218_handsOnState "15";
BA_ "GenSigSNA" SG_ 1513 APP_sw257_user_sensitivity "3";
BA_ "GenSigSNA" SG_ 1513 APP_sw260_user_sensitivity "3";
BA_ "FieldType" SG_ 1513 APP_sw263_markerType "LSS_markerType";
BA_ "FieldType" SG_ 1513 APP_sw263_side "LSS_side";
BA_ "FieldType" SG_ 1513 APP_sw263_lssAbortReason "LSS_abortReason";
BA_ "FieldType" SG_ 1513 APP_sw264_faultReason "LSS_faultReason";
BA_ "FieldType" SG_ 1513 APP_sw265_surroundCameraStatus "APP_visionCameraStatus";
BA_ "FieldType" SG_ 1513 APP_sw265_unavailableReason "DON_unavailableReason";
BA_ "FieldType" SG_ 1513 APP_sw266_lPillarStreamStatus "APP_cameraStreamStatus";
BA_ "FieldType" SG_ 1513 APP_sw266_rPillarStreamStatus "APP_cameraStreamStatus";
BA_ "FieldType" SG_ 1513 APP_sw266_lRepeaterStreamStatus "APP_cameraStreamStatus";
BA_ "FieldType" SG_ 1513 APP_sw266_rRepeaterStreamStatus "APP_cameraStreamStatus";
BA_ "FieldType" SG_ 1513 APP_sw266_backupStreamStatus "APP_cameraStreamStatus";
BA_ "FieldType" SG_ 1513 APP_sw269_emergencyLaneKeep "LSS_limitedReason";
BA_ "GenSigSNA" SG_ 1513 APP_sw269_emergencyLaneKeep "31";
BA_ "FieldType" SG_ 1513 APP_sw269_laneKeepAssist "LSS_limitedReason";
BA_ "GenSigSNA" SG_ 1513 APP_sw269_laneKeepAssist "31";
BA_ "FieldType" SG_ 1513 APP_sw269_blindspot "LSS_limitedReason";
BA_ "GenSigSNA" SG_ 1513 APP_sw269_blindspot "31";
BA_ "FieldType" SG_ 1513 APP_sw269_laneDepartureWarning "LSS_limitedReason";
BA_ "GenSigSNA" SG_ 1513 APP_sw269_laneDepartureWarning "31";
BA_ "FieldType" SG_ 1513 APP_sw270_emergencyLaneKeep "LSS_limitedReason";
BA_ "GenSigSNA" SG_ 1513 APP_sw270_emergencyLaneKeep "31";
BA_ "FieldType" SG_ 1513 APP_sw270_laneKeepAssist "LSS_limitedReason";
BA_ "GenSigSNA" SG_ 1513 APP_sw270_laneKeepAssist "31";
BA_ "FieldType" SG_ 1513 APP_sw270_blindspot "LSS_limitedReason";
BA_ "GenSigSNA" SG_ 1513 APP_sw270_blindspot "31";
BA_ "FieldType" SG_ 1513 APP_sw270_laneDepartureWarning "LSS_limitedReason";
BA_ "GenSigSNA" SG_ 1513 APP_sw270_laneDepartureWarning "31";
BA_ "FieldType" SG_ 1513 APP_sw271_abortReason "APP_alcAbortReason";
BA_ "FieldType" SG_ 1513 APP_sw271_direction "APP_alcDirection";
BA_ "FieldType" SG_ 1513 APP_sw272_unavailableReason "APP_alcUnavailableReason";
BA_ "FieldType" SG_ 1513 APP_sw273_eventType "APP_lssEventType";
BA_ "FieldType" SG_ 1513 APP_sw273_collisionType "APP_lssCollisionType";
BA_ "FieldType" SG_ 1513 APP_sw273_side "LSS_side";
BA_ "FieldType" SG_ 1513 APP_sw274_exitStatus "CameraStreamExitStatus";
BA_ "FieldType" SG_ 1513 APP_sw274_tempMonitorFailure "CameraTemperatureMonitorFailure";
BA_ "FieldType" SG_ 1513 APP_sw274_imagerHeartbeat "ImagerHeartbeat";
BA_ "GenSigSNA" SG_ 1513 APP_sw274_imagerHeartbeat "3";
BA_ "GenSigSNA" SG_ 1513 APP_sw274_serializerCrcErrCount "255";
BA_ "GenSigSNA" SG_ 1513 APP_sw274_currentTemperature "255";
BA_ "GenSigSNA" SG_ 1513 APP_sw274_minTemperature "255";
BA_ "GenSigSNA" SG_ 1513 APP_sw274_maxTemperature "255";
BA_ "FieldType" SG_ 1513 APP_sw275_exitStatus "CameraStreamExitStatus";
BA_ "FieldType" SG_ 1513 APP_sw275_tempMonitorFailure "CameraTemperatureMonitorFailure";
BA_ "FieldType" SG_ 1513 APP_sw275_imagerHeartbeat "ImagerHeartbeat";
BA_ "GenSigSNA" SG_ 1513 APP_sw275_imagerHeartbeat "3";
BA_ "GenSigSNA" SG_ 1513 APP_sw275_serializerCrcErrCount "255";
BA_ "GenSigSNA" SG_ 1513 APP_sw275_currentTemperature "255";
BA_ "GenSigSNA" SG_ 1513 APP_sw275_minTemperature "255";
BA_ "GenSigSNA" SG_ 1513 APP_sw275_maxTemperature "255";
BA_ "FieldType" SG_ 1513 APP_sw276_exitStatus "CameraStreamExitStatus";
BA_ "FieldType" SG_ 1513 APP_sw276_tempMonitorFailure "CameraTemperatureMonitorFailure";
BA_ "FieldType" SG_ 1513 APP_sw276_imagerHeartbeat "ImagerHeartbeat";
BA_ "GenSigSNA" SG_ 1513 APP_sw276_imagerHeartbeat "3";
BA_ "GenSigSNA" SG_ 1513 APP_sw276_serializerCrcErrCount "255";
BA_ "GenSigSNA" SG_ 1513 APP_sw276_currentTemperature "255";
BA_ "GenSigSNA" SG_ 1513 APP_sw276_minTemperature "255";
BA_ "GenSigSNA" SG_ 1513 APP_sw276_maxTemperature "255";
BA_ "FieldType" SG_ 1513 APP_sw277_exitStatus "CameraStreamExitStatus";
BA_ "FieldType" SG_ 1513 APP_sw277_tempMonitorFailure "CameraTemperatureMonitorFailure";
BA_ "FieldType" SG_ 1513 APP_sw277_imagerHeartbeat "ImagerHeartbeat";
BA_ "GenSigSNA" SG_ 1513 APP_sw277_imagerHeartbeat "3";
BA_ "GenSigSNA" SG_ 1513 APP_sw277_serializerCrcErrCount "255";
BA_ "GenSigSNA" SG_ 1513 APP_sw277_currentTemperature "255";
BA_ "GenSigSNA" SG_ 1513 APP_sw277_minTemperature "255";
BA_ "GenSigSNA" SG_ 1513 APP_sw277_maxTemperature "255";
BA_ "FieldType" SG_ 1513 APP_sw278_exitStatus "CameraStreamExitStatus";
BA_ "FieldType" SG_ 1513 APP_sw278_tempMonitorFailure "CameraTemperatureMonitorFailure";
BA_ "FieldType" SG_ 1513 APP_sw278_imagerHeartbeat "ImagerHeartbeat";
BA_ "GenSigSNA" SG_ 1513 APP_sw278_imagerHeartbeat "3";
BA_ "GenSigSNA" SG_ 1513 APP_sw278_serializerCrcErrCount "255";
BA_ "GenSigSNA" SG_ 1513 APP_sw278_currentTemperature "255";
BA_ "GenSigSNA" SG_ 1513 APP_sw278_minTemperature "255";
BA_ "GenSigSNA" SG_ 1513 APP_sw278_maxTemperature "255";
BA_ "FieldType" SG_ 1513 APP_sw279_exitStatus "CameraStreamExitStatus";
BA_ "FieldType" SG_ 1513 APP_sw279_tempMonitorFailure "CameraTemperatureMonitorFailure";
BA_ "FieldType" SG_ 1513 APP_sw279_imagerHeartbeat "ImagerHeartbeat";
BA_ "GenSigSNA" SG_ 1513 APP_sw279_imagerHeartbeat "3";
BA_ "GenSigSNA" SG_ 1513 APP_sw279_serializerCrcErrCount "255";
BA_ "GenSigSNA" SG_ 1513 APP_sw279_currentTemperature "255";
BA_ "GenSigSNA" SG_ 1513 APP_sw279_minTemperature "255";
BA_ "GenSigSNA" SG_ 1513 APP_sw279_maxTemperature "255";
BA_ "FieldType" SG_ 1513 APP_sw280_exitStatus "CameraStreamExitStatus";
BA_ "FieldType" SG_ 1513 APP_sw280_tempMonitorFailure "CameraTemperatureMonitorFailure";
BA_ "FieldType" SG_ 1513 APP_sw280_imagerHeartbeat "ImagerHeartbeat";
BA_ "GenSigSNA" SG_ 1513 APP_sw280_imagerHeartbeat "3";
BA_ "GenSigSNA" SG_ 1513 APP_sw280_serializerCrcErrCount "255";
BA_ "GenSigSNA" SG_ 1513 APP_sw280_currentTemperature "255";
BA_ "GenSigSNA" SG_ 1513 APP_sw280_minTemperature "255";
BA_ "GenSigSNA" SG_ 1513 APP_sw280_maxTemperature "255";
BA_ "FieldType" SG_ 1513 APP_sw281_exitStatus "CameraStreamExitStatus";
BA_ "FieldType" SG_ 1513 APP_sw281_tempMonitorFailure "CameraTemperatureMonitorFailure";
BA_ "FieldType" SG_ 1513 APP_sw281_imagerHeartbeat "ImagerHeartbeat";
BA_ "GenSigSNA" SG_ 1513 APP_sw281_imagerHeartbeat "3";
BA_ "GenSigSNA" SG_ 1513 APP_sw281_serializerCrcErrCount "255";
BA_ "GenSigSNA" SG_ 1513 APP_sw281_currentTemperature "255";
BA_ "GenSigSNA" SG_ 1513 APP_sw281_minTemperature "255";
BA_ "GenSigSNA" SG_ 1513 APP_sw281_maxTemperature "255";
BA_ "FieldType" SG_ 1513 APP_sw282_exitStatus "CameraStreamExitStatus";
BA_ "FieldType" SG_ 1513 APP_sw282_tempMonitorFailure "CameraTemperatureMonitorFailure";
BA_ "FieldType" SG_ 1513 APP_sw282_imagerHeartbeat "ImagerHeartbeat";
BA_ "GenSigSNA" SG_ 1513 APP_sw282_imagerHeartbeat "3";
BA_ "GenSigSNA" SG_ 1513 APP_sw282_serializerCrcErrCount "255";
BA_ "GenSigSNA" SG_ 1513 APP_sw282_currentTemperature "255";
BA_ "GenSigSNA" SG_ 1513 APP_sw282_minTemperature "255";
BA_ "GenSigSNA" SG_ 1513 APP_sw282_maxTemperature "255";
BA_ "FieldType" SG_ 1513 APP_sw283_mainCam "APP_cameraStatus";
BA_ "FieldType" SG_ 1513 APP_sw283_narrowCam "APP_cameraStatus";
BA_ "FieldType" SG_ 1513 APP_sw283_fisheyeCam "APP_cameraStatus";
BA_ "FieldType" SG_ 1513 APP_sw283_leftRepeaterCam "APP_cameraStatus";
BA_ "FieldType" SG_ 1513 APP_sw283_rightRepeaterCam "APP_cameraStatus";
BA_ "FieldType" SG_ 1513 APP_sw283_leftPillarCam "APP_cameraStatus";
BA_ "FieldType" SG_ 1513 APP_sw283_rightPillarCam "APP_cameraStatus";
BA_ "FieldType" SG_ 1513 APP_sw283_bucCam "APP_cameraStatus";
BA_ "FieldType" SG_ 1513 APP_sw312_expectedSensorModel "APP_cameraSensorModel";
BA_ "FieldType" SG_ 1513 APP_sw312_detectedSensorModel "APP_cameraSensorModel";
BA_ "FieldType" SG_ 1513 APP_sw313_expectedSensorModel "APP_cameraSensorModel";
BA_ "FieldType" SG_ 1513 APP_sw313_detectedSensorModel "APP_cameraSensorModel";
BA_ "FieldType" SG_ 1513 APP_sw314_expectedSensorModel "APP_cameraSensorModel";
BA_ "FieldType" SG_ 1513 APP_sw314_detectedSensorModel "APP_cameraSensorModel";
BA_ "FieldType" SG_ 1513 APP_sw315_expectedSensorModel "APP_cameraSensorModel";
BA_ "FieldType" SG_ 1513 APP_sw315_detectedSensorModel "APP_cameraSensorModel";
BA_ "FieldType" SG_ 1513 APP_sw316_expectedSensorModel "APP_cameraSensorModel";
BA_ "FieldType" SG_ 1513 APP_sw316_detectedSensorModel "APP_cameraSensorModel";
BA_ "FieldType" SG_ 1513 APP_sw317_expectedSensorModel "APP_cameraSensorModel";
BA_ "FieldType" SG_ 1513 APP_sw317_detectedSensorModel "APP_cameraSensorModel";
BA_ "FieldType" SG_ 1513 APP_sw318_expectedSensorModel "APP_cameraSensorModel";
BA_ "FieldType" SG_ 1513 APP_sw318_detectedSensorModel "APP_cameraSensorModel";
BA_ "FieldType" SG_ 1513 APP_sw319_expectedSensorModel "APP_cameraSensorModel";
BA_ "FieldType" SG_ 1513 APP_sw319_detectedSensorModel "APP_cameraSensorModel";
BA_ "FieldType" SG_ 1513 APP_sw320_expectedSensorModel "APP_cameraSensorModel";
BA_ "FieldType" SG_ 1513 APP_sw320_detectedSensorModel "APP_cameraSensorModel";
BA_ "LogSignal" SG_ 1020 APP_decisionTemperature "periodic TEN_SECONDS driveModeModelS";
BA_ "LogSignal" SG_ 1020 APP_pascalTemperature "periodic TEN_SECONDS driveModeModelS";
BA_ "LogSignal" SG_ 1020 APP_parkerATemperature "periodic TEN_SECONDS driveModeModelS";
BA_ "LogSignal" SG_ 1020 APP_parkerBTemperature "periodic TEN_SECONDS driveModeModelS";
BA_ "LogSignal" SG_ 1020 APP_pascalExtTemperature "periodic TEN_SECONDS driveModeModelS";
BA_ "LogSignal" SG_ 1020 APP_parkerExtTemperature "periodic TEN_SECONDS driveModeModelS";
BA_ "FieldType" SG_ 1010 APP_cameraPosition "APP_cameraPosition";
BA_ "GenSigSNA" SG_ 1010 APP_mainCamExtPitchCal "511";
BA_ "LogSignal" SG_ 1010 APP_mainCamExtPitchCal "onChange";
BA_ "GenSigSNA" SG_ 1010 APP_mainCamExtYawCal "511";
BA_ "LogSignal" SG_ 1010 APP_mainCamExtYawCal "onChange";
BA_ "GenSigSNA" SG_ 1010 APP_mainCalibTime "127";
BA_ "LogSignal" SG_ 1010 APP_mainCalibTime "onChange";
BA_ "GenSigSNA" SG_ 1010 APP_mainCalibProgress "127";
BA_ "LogSignal" SG_ 1010 APP_mainCalibProgress "onChange";
BA_ "LogSignal" SG_ 1010 APP_mainCalibrated "onChange";
BA_ "GenSigSNA" SG_ 1010 APP_narrowCamExtPitchCal "511";
BA_ "LogSignal" SG_ 1010 APP_narrowCamExtPitchCal "onChange";
BA_ "GenSigSNA" SG_ 1010 APP_narrowCamExtYawCal "511";
BA_ "LogSignal" SG_ 1010 APP_narrowCamExtYawCal "onChange";
BA_ "GenSigSNA" SG_ 1010 APP_narrowCalibTime "127";
BA_ "LogSignal" SG_ 1010 APP_narrowCalibTime "onChange";
BA_ "GenSigSNA" SG_ 1010 APP_narrowCalibProgress "127";
BA_ "LogSignal" SG_ 1010 APP_narrowCalibProgress "onChange";
BA_ "LogSignal" SG_ 1010 APP_narrowCalibrated "onChange";
BA_ "GenSigSNA" SG_ 1010 APP_fisheyeCamExtPitchCal "511";
BA_ "LogSignal" SG_ 1010 APP_fisheyeCamExtPitchCal "onChange";
BA_ "GenSigSNA" SG_ 1010 APP_fisheyeCamExtYawCal "511";
BA_ "LogSignal" SG_ 1010 APP_fisheyeCamExtYawCal "onChange";
BA_ "GenSigSNA" SG_ 1010 APP_fisheyeCalibTime "127";
BA_ "LogSignal" SG_ 1010 APP_fisheyeCalibTime "onChange";
BA_ "GenSigSNA" SG_ 1010 APP_fisheyeCalibProgress "127";
BA_ "LogSignal" SG_ 1010 APP_fisheyeCalibProgress "onChange";
BA_ "LogSignal" SG_ 1010 APP_fisheyeCalibrated "onChange";
BA_ "GenSigSNA" SG_ 1010 APP_lPillarCamExtPitchCal "511";
BA_ "LogSignal" SG_ 1010 APP_lPillarCamExtPitchCal "onChange";
BA_ "GenSigSNA" SG_ 1010 APP_lPillarCamExtYawCal "511";
BA_ "LogSignal" SG_ 1010 APP_lPillarCamExtYawCal "onChange";
BA_ "GenSigSNA" SG_ 1010 APP_lPillarCalibTime "127";
BA_ "LogSignal" SG_ 1010 APP_lPillarCalibTime "onChange";
BA_ "GenSigSNA" SG_ 1010 APP_lPillarCalibProgress "127";
BA_ "LogSignal" SG_ 1010 APP_lPillarCalibProgress "onChange";
BA_ "LogSignal" SG_ 1010 APP_lPillarCalibrated "onChange";
BA_ "GenSigSNA" SG_ 1010 APP_rPillarCamExtPitchCal "511";
BA_ "LogSignal" SG_ 1010 APP_rPillarCamExtPitchCal "onChange";
BA_ "GenSigSNA" SG_ 1010 APP_rPillarCamExtYawCal "511";
BA_ "LogSignal" SG_ 1010 APP_rPillarCamExtYawCal "onChange";
BA_ "GenSigSNA" SG_ 1010 APP_rPillarCalibTime "127";
BA_ "LogSignal" SG_ 1010 APP_rPillarCalibTime "onChange";
BA_ "GenSigSNA" SG_ 1010 APP_rPillarCalibProgress "127";
BA_ "LogSignal" SG_ 1010 APP_rPillarCalibProgress "onChange";
BA_ "LogSignal" SG_ 1010 APP_rPillarCalibrated "onChange";
BA_ "GenSigSNA" SG_ 1010 APP_lRepeatCamExtPitchCal "511";
BA_ "LogSignal" SG_ 1010 APP_lRepeatCamExtPitchCal "onChange";
BA_ "GenSigSNA" SG_ 1010 APP_lRepeatCamExtYawCal "511";
BA_ "LogSignal" SG_ 1010 APP_lRepeatCamExtYawCal "onChange";
BA_ "GenSigSNA" SG_ 1010 APP_lRepeatCalibTime "127";
BA_ "LogSignal" SG_ 1010 APP_lRepeatCalibTime "onChange";
BA_ "GenSigSNA" SG_ 1010 APP_lRepeatCalibProgress "127";
BA_ "LogSignal" SG_ 1010 APP_lRepeatCalibProgress "onChange";
BA_ "LogSignal" SG_ 1010 APP_lRepeatCalibrated "onChange";
BA_ "GenSigSNA" SG_ 1010 APP_rRepeatCamExtPitchCal "511";
BA_ "LogSignal" SG_ 1010 APP_rRepeatCamExtPitchCal "onChange";
BA_ "GenSigSNA" SG_ 1010 APP_rRepeatCamExtYawCal "511";
BA_ "LogSignal" SG_ 1010 APP_rRepeatCamExtYawCal "onChange";
BA_ "GenSigSNA" SG_ 1010 APP_rRepeatCalibTime "127";
BA_ "LogSignal" SG_ 1010 APP_rRepeatCalibTime "onChange";
BA_ "GenSigSNA" SG_ 1010 APP_rRepeatCalibProgress "127";
BA_ "LogSignal" SG_ 1010 APP_rRepeatCalibProgress "onChange";
BA_ "LogSignal" SG_ 1010 APP_rRepeatCalibrated "onChange";
BA_ "GenSigSNA" SG_ 1010 APP_backupCamExtPitchCal "511";
BA_ "LogSignal" SG_ 1010 APP_backupCamExtPitchCal "onChange";
BA_ "GenSigSNA" SG_ 1010 APP_backupCamExtYawCal "511";
BA_ "LogSignal" SG_ 1010 APP_backupCamExtYawCal "onChange";
BA_ "GenSigSNA" SG_ 1010 APP_backupCalibTime "127";
BA_ "LogSignal" SG_ 1010 APP_backupCalibTime "onChange";
BA_ "GenSigSNA" SG_ 1010 APP_backupCalibProgress "127";
BA_ "LogSignal" SG_ 1010 APP_backupCalibProgress "onChange";
BA_ "LogSignal" SG_ 1010 APP_backupCalibrated "onChange";
BA_ "FieldType" SG_ 1017 APP_mainCameraLUX "APP_cameraLuxValue";
BA_ "GenSigSNA" SG_ 1017 APP_mainCameraLUX "255";
BA_ "FieldType" SG_ 1017 APP_narrowCameraLUX "APP_cameraLuxValue";
BA_ "GenSigSNA" SG_ 1017 APP_narrowCameraLUX "255";
BA_ "FieldType" SG_ 1017 APP_fisheyeCameraLUX "APP_cameraLuxValue";
BA_ "GenSigSNA" SG_ 1017 APP_fisheyeCameraLUX "255";
BA_ "FieldType" SG_ 1017 APP_lRepeatCameraLUX "APP_cameraLuxValue";
BA_ "GenSigSNA" SG_ 1017 APP_lRepeatCameraLUX "255";
BA_ "FieldType" SG_ 1017 APP_rRepeatCameraLUX "APP_cameraLuxValue";
BA_ "GenSigSNA" SG_ 1017 APP_rRepeatCameraLUX "255";
BA_ "FieldType" SG_ 1017 APP_lPillarCameraLUX "APP_cameraLuxValue";
BA_ "GenSigSNA" SG_ 1017 APP_lPillarCameraLUX "255";
BA_ "FieldType" SG_ 1017 APP_rPillarCameraLUX "APP_cameraLuxValue";
BA_ "GenSigSNA" SG_ 1017 APP_rPillarCameraLUX "255";
BA_ "FieldType" SG_ 1017 APP_backupCameraLUX "APP_cameraLuxValue";
BA_ "GenSigSNA" SG_ 1017 APP_backupCameraLUX "255";
BA_ "GenSigSNA" SG_ 1177 APP_mainCameraTemperature "255";
BA_ "LogSignal" SG_ 1177 APP_mainCameraTemperature "periodic ONE_MINUTE accRailOn";
BA_ "GenSigSNA" SG_ 1177 APP_narrowCameraTemperature "255";
BA_ "LogSignal" SG_ 1177 APP_narrowCameraTemperature "periodic ONE_MINUTE accRailOn";
BA_ "GenSigSNA" SG_ 1177 APP_fisheyeCameraTemperature "255";
BA_ "LogSignal" SG_ 1177 APP_fisheyeCameraTemperature "periodic ONE_MINUTE accRailOn";
BA_ "GenSigSNA" SG_ 1177 APP_rRepeaterCameraTemperature "255";
BA_ "LogSignal" SG_ 1177 APP_rRepeaterCameraTemperature "periodic ONE_MINUTE accRailOn";
BA_ "GenSigSNA" SG_ 1177 APP_lRepeaterCameraTemperature "255";
BA_ "LogSignal" SG_ 1177 APP_lRepeaterCameraTemperature "periodic ONE_MINUTE accRailOn";
BA_ "GenSigSNA" SG_ 1177 APP_lPillarCameraTemperature "255";
BA_ "LogSignal" SG_ 1177 APP_lPillarCameraTemperature "periodic ONE_MINUTE accRailOn";
BA_ "GenSigSNA" SG_ 1177 APP_rPillarCameraTemperature "255";
BA_ "LogSignal" SG_ 1177 APP_rPillarCameraTemperature "periodic ONE_MINUTE accRailOn";
BA_ "GenSigSNA" SG_ 1177 APP_backupCameraTemperature "255";
BA_ "LogSignal" SG_ 1177 APP_backupCameraTemperature "periodic ONE_MINUTE accRailOn";
BA_ "LogSignal" SG_ 608 APP_environmentRainy "onChange";
BA_ "LogSignal" SG_ 608 APP_environmentSnowy "onChange";
BA_ "FieldType" SG_ 1353 APP_infoIndex "AP_infoIndex";
BA_ "GenSigCycleTime" SG_ 1353 APP_infoIndex 1000;
BA_ "FieldType" SG_ 1353 APP_buildType "AP_buildType";
BA_ "FieldType" SG_ 601 APP_watchdogState "AP_watchdogState";
BA_ "GenSigSNA" SG_ 601 APP_watchdogState "7";
BA_ "LogSignal" SG_ 601 APP_watchdogState "onChange";
BA_ "FieldType" SG_ 601 APP_fusedState "APP_fusedState";
BA_ "GenSigSNA" SG_ 601 APP_fusedState "3";
BA_ "FieldType" SG_ 601 APP_factorySummonStatus "APP_factorySummonStatus";
BA_ "GenSigSNA" SG_ 601 APP_factorySummonStatus "0";
BA_ "LogSignal" SG_ 601 APP_factorySummonStatus "onChange";
BA_ "FieldType" SG_ 601 APP_summonUnavailableReason "APP_summonUnavailableReason";
BA_ "LogSignal" SG_ 601 APP_summonUnavailableReason "onChange";
BA_ "GenSigSNA" SG_ 1018 APP_summonInstruction "7";
BA_ "GenSigSNA" SG_ 1018 APP_summonState "7";
BA_ "GenSigSNA" SG_ 906 APP_solarObscurityPercent "255";
BA_ "GenSigSNA" SG_ 906 APP_solarLoadEstimate "2047";
BA_ "FieldType" SG_ 602 APP_tcFeatureState "APP_tcFeatureState";
BA_ "LogSignal" SG_ 602 APP_tcFeatureState "onChange";
BA_ "FieldType" SG_ 602 APP_tcStateMachine "APP_tcStateMachine";
BA_ "LogSignal" SG_ 602 APP_tcStateMachine "onChange";
BA_ "FieldType" SG_ 602 APP_tcControlSource "APP_tcControlSource";
BA_ "LogSignal" SG_ 602 APP_tcControlSource "onChange";
BA_ "FieldType" SG_ 602 APP_tcControlType "APP_tcControlType";
BA_ "LogSignal" SG_ 602 APP_tcControlType "onChange";
BA_ "LogSignal" SG_ 602 APP_tcControlDistance "periodic ONE_SECOND driveModeModelS";
BA_ "FieldType" SG_ 602 APP_tcControlLightState "APP_tcControlLightState";
BA_ "LogSignal" SG_ 602 APP_tcControlLightState "onChange";
BA_ "FieldType" SG_ 602 APP_tcContinuationReason "APP_tcContinuationReason";
BA_ "LogSignal" SG_ 602 APP_tcContinuationReason "onChange";
BA_ "FieldType" SG_ 602 APP_tcConfirmationType "APP_tcConfirmationType";
BA_ "LogSignal" SG_ 602 APP_tcConfirmationType "onChange";
BA_ "FieldType" SG_ 602 APP_tcWarningSuppressionReason "APP_tcWarningSuppressionReason";
BA_ "LogSignal" SG_ 602 APP_tcWarningSuppressionReason "onChange";
BA_ "FieldType" SG_ 602 APP_tcUnavailableReason "APP_tcUnavailableReason";
BA_ "LogSignal" SG_ 602 APP_tcUnavailableReason "onChange";
BA_ "LogSignal" SG_ 602 APP_tcVisionLight "onChange";
BA_ "LogSignal" SG_ 602 APP_tcVisionSign "onChange";
BA_ "LogSignal" SG_ 602 APP_tcVisionRoadMarking "onChange";
BA_ "LogSignal" SG_ 602 APP_tcVisionLine "onChange";
VAL_ 1513 APP_sw144_fanctrldErrorType 14 "ERROR_FAILED_SET_FAN_MAX_SPEED" 13 "ERROR_FAILED_SET_FAN_MIN_SPEED" 12 "ERROR_FAILED_DISABLE_FAN" 11 "ERROR_FAILED_ENABLE_FAN" 10 "ERROR_THERMAL_LIMIT" 9 "ERROR_SUB_ZERO" 8 "ERROR_FAILED_CHECK_FAN_STATUS" 7 "ERROR_FAILED_WRITE_RESISTOR" 6 "ERROR_FAILED_READ_MAXIM_TMP" 5 "ERROR_FAILED_READ_PASCAL_TMP" 4 "ERROR_FAILED_READ_PARKER_TMP" 3 "ERROR_FAILED_READ_TMP451_TMP" 2 "ERROR_TERMINATE" 1 "ERROR_INIT" 0 "FANCTRL_NO_ERROR" ;
VAL_ 1513 APP_sw145_problemCamPosition 9 "CAM_SELFIE" 8 "CAM_BACKUP" 7 "CAM_R_REPEATER" 6 "CAM_L_REPEATER" 5 "CAM_R_PILLAR" 4 "CAM_L_PILLAR" 3 "CAM_FISHEYE" 2 "CAM_NARROW" 1 "CAM_MAIN" 0 "CAM_INVALID" ;
VAL_ 1513 APP_sw146_telemProblemType 1 "PACKAGE_EXPIRED" 0 "UNKNOWN" ;
VAL_ 1513 APP_sw146_packageType 1 "S3_UPLOAD" 0 "STREAM" ;
VAL_ 1513 APP_sw147_selfieCamDeserFault 4 "I2C_UNKNOWN_IOCTL_ERR" 3 "I2C_DATA_NACK" 2 "I2C_SLAVE_ADDR_NACK" 1 "I2C_BUS_FAULT" 0 "NO_I2C_FAULT" ;
VAL_ 1513 APP_sw147_selfieCamSerFault 4 "I2C_UNKNOWN_IOCTL_ERR" 3 "I2C_DATA_NACK" 2 "I2C_SLAVE_ADDR_NACK" 1 "I2C_BUS_FAULT" 0 "NO_I2C_FAULT" ;
VAL_ 1513 APP_sw147_selfieCamSensorFault 4 "I2C_UNKNOWN_IOCTL_ERR" 3 "I2C_DATA_NACK" 2 "I2C_SLAVE_ADDR_NACK" 1 "I2C_BUS_FAULT" 0 "NO_I2C_FAULT" ;
VAL_ 1513 APP_sw162_detectedColorFilter 3 "COLOR_FILTER_UNKNOWN" 2 "COLOR_FILTER_RGGB" 1 "COLOR_FILTER_RCCB" 0 "COLOR_FILTER_RCCC" ;
VAL_ 1513 APP_sw162_expectedColorFilter 3 "COLOR_FILTER_UNKNOWN" 2 "COLOR_FILTER_RGGB" 1 "COLOR_FILTER_RCCB" 0 "COLOR_FILTER_RCCC" ;
VAL_ 1513 APP_sw162_detectedPosition 9 "CAM_SELFIE" 8 "CAM_BACKUP" 7 "CAM_R_REPEATER" 6 "CAM_L_REPEATER" 5 "CAM_R_PILLAR" 4 "CAM_L_PILLAR" 3 "CAM_FISHEYE" 2 "CAM_NARROW" 1 "CAM_MAIN" 0 "CAM_INVALID" ;
VAL_ 1513 APP_sw163_detectedColorFilter 3 "COLOR_FILTER_UNKNOWN" 2 "COLOR_FILTER_RGGB" 1 "COLOR_FILTER_RCCB" 0 "COLOR_FILTER_RCCC" ;
VAL_ 1513 APP_sw163_expectedColorFilter 3 "COLOR_FILTER_UNKNOWN" 2 "COLOR_FILTER_RGGB" 1 "COLOR_FILTER_RCCB" 0 "COLOR_FILTER_RCCC" ;
VAL_ 1513 APP_sw163_detectedPosition 9 "CAM_SELFIE" 8 "CAM_BACKUP" 7 "CAM_R_REPEATER" 6 "CAM_L_REPEATER" 5 "CAM_R_PILLAR" 4 "CAM_L_PILLAR" 3 "CAM_FISHEYE" 2 "CAM_NARROW" 1 "CAM_MAIN" 0 "CAM_INVALID" ;
VAL_ 1513 APP_sw164_detectedColorFilter 3 "COLOR_FILTER_UNKNOWN" 2 "COLOR_FILTER_RGGB" 1 "COLOR_FILTER_RCCB" 0 "COLOR_FILTER_RCCC" ;
VAL_ 1513 APP_sw164_expectedColorFilter 3 "COLOR_FILTER_UNKNOWN" 2 "COLOR_FILTER_RGGB" 1 "COLOR_FILTER_RCCB" 0 "COLOR_FILTER_RCCC" ;
VAL_ 1513 APP_sw164_detectedPosition 9 "CAM_SELFIE" 8 "CAM_BACKUP" 7 "CAM_R_REPEATER" 6 "CAM_L_REPEATER" 5 "CAM_R_PILLAR" 4 "CAM_L_PILLAR" 3 "CAM_FISHEYE" 2 "CAM_NARROW" 1 "CAM_MAIN" 0 "CAM_INVALID" ;
VAL_ 1513 APP_sw165_detectedColorFilter 3 "COLOR_FILTER_UNKNOWN" 2 "COLOR_FILTER_RGGB" 1 "COLOR_FILTER_RCCB" 0 "COLOR_FILTER_RCCC" ;
VAL_ 1513 APP_sw165_expectedColorFilter 3 "COLOR_FILTER_UNKNOWN" 2 "COLOR_FILTER_RGGB" 1 "COLOR_FILTER_RCCB" 0 "COLOR_FILTER_RCCC" ;
VAL_ 1513 APP_sw165_detectedPosition 9 "CAM_SELFIE" 8 "CAM_BACKUP" 7 "CAM_R_REPEATER" 6 "CAM_L_REPEATER" 5 "CAM_R_PILLAR" 4 "CAM_L_PILLAR" 3 "CAM_FISHEYE" 2 "CAM_NARROW" 1 "CAM_MAIN" 0 "CAM_INVALID" ;
VAL_ 1513 APP_sw166_detectedColorFilter 3 "COLOR_FILTER_UNKNOWN" 2 "COLOR_FILTER_RGGB" 1 "COLOR_FILTER_RCCB" 0 "COLOR_FILTER_RCCC" ;
VAL_ 1513 APP_sw166_expectedColorFilter 3 "COLOR_FILTER_UNKNOWN" 2 "COLOR_FILTER_RGGB" 1 "COLOR_FILTER_RCCB" 0 "COLOR_FILTER_RCCC" ;
VAL_ 1513 APP_sw166_detectedPosition 9 "CAM_SELFIE" 8 "CAM_BACKUP" 7 "CAM_R_REPEATER" 6 "CAM_L_REPEATER" 5 "CAM_R_PILLAR" 4 "CAM_L_PILLAR" 3 "CAM_FISHEYE" 2 "CAM_NARROW" 1 "CAM_MAIN" 0 "CAM_INVALID" ;
VAL_ 1513 APP_sw167_detectedColorFilter 3 "COLOR_FILTER_UNKNOWN" 2 "COLOR_FILTER_RGGB" 1 "COLOR_FILTER_RCCB" 0 "COLOR_FILTER_RCCC" ;
VAL_ 1513 APP_sw167_expectedColorFilter 3 "COLOR_FILTER_UNKNOWN" 2 "COLOR_FILTER_RGGB" 1 "COLOR_FILTER_RCCB" 0 "COLOR_FILTER_RCCC" ;
VAL_ 1513 APP_sw167_detectedPosition 9 "CAM_SELFIE" 8 "CAM_BACKUP" 7 "CAM_R_REPEATER" 6 "CAM_L_REPEATER" 5 "CAM_R_PILLAR" 4 "CAM_L_PILLAR" 3 "CAM_FISHEYE" 2 "CAM_NARROW" 1 "CAM_MAIN" 0 "CAM_INVALID" ;
VAL_ 1513 APP_sw168_detectedColorFilter 3 "COLOR_FILTER_UNKNOWN" 2 "COLOR_FILTER_RGGB" 1 "COLOR_FILTER_RCCB" 0 "COLOR_FILTER_RCCC" ;
VAL_ 1513 APP_sw168_expectedColorFilter 3 "COLOR_FILTER_UNKNOWN" 2 "COLOR_FILTER_RGGB" 1 "COLOR_FILTER_RCCB" 0 "COLOR_FILTER_RCCC" ;
VAL_ 1513 APP_sw168_detectedPosition 9 "CAM_SELFIE" 8 "CAM_BACKUP" 7 "CAM_R_REPEATER" 6 "CAM_L_REPEATER" 5 "CAM_R_PILLAR" 4 "CAM_L_PILLAR" 3 "CAM_FISHEYE" 2 "CAM_NARROW" 1 "CAM_MAIN" 0 "CAM_INVALID" ;
VAL_ 1513 APP_sw169_detectedColorFilter 3 "COLOR_FILTER_UNKNOWN" 2 "COLOR_FILTER_RGGB" 1 "COLOR_FILTER_RCCB" 0 "COLOR_FILTER_RCCC" ;
VAL_ 1513 APP_sw169_expectedColorFilter 3 "COLOR_FILTER_UNKNOWN" 2 "COLOR_FILTER_RGGB" 1 "COLOR_FILTER_RCCB" 0 "COLOR_FILTER_RCCC" ;
VAL_ 1513 APP_sw169_detectedPosition 9 "CAM_SELFIE" 8 "CAM_BACKUP" 7 "CAM_R_REPEATER" 6 "CAM_L_REPEATER" 5 "CAM_R_PILLAR" 4 "CAM_L_PILLAR" 3 "CAM_FISHEYE" 2 "CAM_NARROW" 1 "CAM_MAIN" 0 "CAM_INVALID" ;
VAL_ 1513 APP_sw170_detectedColorFilter 3 "COLOR_FILTER_UNKNOWN" 2 "COLOR_FILTER_RGGB" 1 "COLOR_FILTER_RCCB" 0 "COLOR_FILTER_RCCC" ;
VAL_ 1513 APP_sw170_expectedColorFilter 3 "COLOR_FILTER_UNKNOWN" 2 "COLOR_FILTER_RGGB" 1 "COLOR_FILTER_RCCB" 0 "COLOR_FILTER_RCCC" ;
VAL_ 1513 APP_sw170_detectedPosition 9 "CAM_SELFIE" 8 "CAM_BACKUP" 7 "CAM_R_REPEATER" 6 "CAM_L_REPEATER" 5 "CAM_R_PILLAR" 4 "CAM_L_PILLAR" 3 "CAM_FISHEYE" 2 "CAM_NARROW" 1 "CAM_MAIN" 0 "CAM_INVALID" ;
VAL_ 1513 APP_sw182_exitStatus 1 "STREAM_EXIT_FAULT" 0 "STREAM_EXIT_NOMINAL" ;
VAL_ 1513 APP_sw182_tempMonitorFailure 2 "TEMPERATURE_MONITOR_OTHER_FAILURE" 1 "TEMPERATURE_OUT_OF_SPEC" 0 "TEMPERATURE_MONITOR_NO_FAILURE" ;
VAL_ 1513 APP_sw182_imagerHeartbeat 3 "IMAGER_HEARTBEAT_SNA" 1 "IMAGER_HEARTBEAT_STATIC" 0 "IMAGER_HEARTBEAT_NOMINAL" ;
VAL_ 1513 APP_sw182_serializerCrcErrCount 255 "SNA" ;
VAL_ 1513 APP_sw182_currentTemperature 255 "SNA" ;
VAL_ 1513 APP_sw182_minTemperature 255 "SNA" ;
VAL_ 1513 APP_sw182_maxTemperature 255 "SNA" ;
VAL_ 1513 APP_sw183_exitStatus 1 "STREAM_EXIT_FAULT" 0 "STREAM_EXIT_NOMINAL" ;
VAL_ 1513 APP_sw183_tempMonitorFailure 2 "TEMPERATURE_MONITOR_OTHER_FAILURE" 1 "TEMPERATURE_OUT_OF_SPEC" 0 "TEMPERATURE_MONITOR_NO_FAILURE" ;
VAL_ 1513 APP_sw183_imagerHeartbeat 3 "IMAGER_HEARTBEAT_SNA" 1 "IMAGER_HEARTBEAT_STATIC" 0 "IMAGER_HEARTBEAT_NOMINAL" ;
VAL_ 1513 APP_sw183_serializerCrcErrCount 255 "SNA" ;
VAL_ 1513 APP_sw183_currentTemperature 255 "SNA" ;
VAL_ 1513 APP_sw183_minTemperature 255 "SNA" ;
VAL_ 1513 APP_sw183_maxTemperature 255 "SNA" ;
VAL_ 1513 APP_sw184_exitStatus 1 "STREAM_EXIT_FAULT" 0 "STREAM_EXIT_NOMINAL" ;
VAL_ 1513 APP_sw184_tempMonitorFailure 2 "TEMPERATURE_MONITOR_OTHER_FAILURE" 1 "TEMPERATURE_OUT_OF_SPEC" 0 "TEMPERATURE_MONITOR_NO_FAILURE" ;
VAL_ 1513 APP_sw184_imagerHeartbeat 3 "IMAGER_HEARTBEAT_SNA" 1 "IMAGER_HEARTBEAT_STATIC" 0 "IMAGER_HEARTBEAT_NOMINAL" ;
VAL_ 1513 APP_sw184_serializerCrcErrCount 255 "SNA" ;
VAL_ 1513 APP_sw184_currentTemperature 255 "SNA" ;
VAL_ 1513 APP_sw184_minTemperature 255 "SNA" ;
VAL_ 1513 APP_sw184_maxTemperature 255 "SNA" ;
VAL_ 1513 APP_sw185_exitStatus 1 "STREAM_EXIT_FAULT" 0 "STREAM_EXIT_NOMINAL" ;
VAL_ 1513 APP_sw185_tempMonitorFailure 2 "TEMPERATURE_MONITOR_OTHER_FAILURE" 1 "TEMPERATURE_OUT_OF_SPEC" 0 "TEMPERATURE_MONITOR_NO_FAILURE" ;
VAL_ 1513 APP_sw185_imagerHeartbeat 3 "IMAGER_HEARTBEAT_SNA" 1 "IMAGER_HEARTBEAT_STATIC" 0 "IMAGER_HEARTBEAT_NOMINAL" ;
VAL_ 1513 APP_sw185_serializerCrcErrCount 255 "SNA" ;
VAL_ 1513 APP_sw185_currentTemperature 255 "SNA" ;
VAL_ 1513 APP_sw185_minTemperature 255 "SNA" ;
VAL_ 1513 APP_sw185_maxTemperature 255 "SNA" ;
VAL_ 1513 APP_sw186_exitStatus 1 "STREAM_EXIT_FAULT" 0 "STREAM_EXIT_NOMINAL" ;
VAL_ 1513 APP_sw186_tempMonitorFailure 2 "TEMPERATURE_MONITOR_OTHER_FAILURE" 1 "TEMPERATURE_OUT_OF_SPEC" 0 "TEMPERATURE_MONITOR_NO_FAILURE" ;
VAL_ 1513 APP_sw186_imagerHeartbeat 3 "IMAGER_HEARTBEAT_SNA" 1 "IMAGER_HEARTBEAT_STATIC" 0 "IMAGER_HEARTBEAT_NOMINAL" ;
VAL_ 1513 APP_sw186_serializerCrcErrCount 255 "SNA" ;
VAL_ 1513 APP_sw186_currentTemperature 255 "SNA" ;
VAL_ 1513 APP_sw186_minTemperature 255 "SNA" ;
VAL_ 1513 APP_sw186_maxTemperature 255 "SNA" ;
VAL_ 1513 APP_sw187_exitStatus 1 "STREAM_EXIT_FAULT" 0 "STREAM_EXIT_NOMINAL" ;
VAL_ 1513 APP_sw187_tempMonitorFailure 2 "TEMPERATURE_MONITOR_OTHER_FAILURE" 1 "TEMPERATURE_OUT_OF_SPEC" 0 "TEMPERATURE_MONITOR_NO_FAILURE" ;
VAL_ 1513 APP_sw187_imagerHeartbeat 3 "IMAGER_HEARTBEAT_SNA" 1 "IMAGER_HEARTBEAT_STATIC" 0 "IMAGER_HEARTBEAT_NOMINAL" ;
VAL_ 1513 APP_sw187_serializerCrcErrCount 255 "SNA" ;
VAL_ 1513 APP_sw187_currentTemperature 255 "SNA" ;
VAL_ 1513 APP_sw187_minTemperature 255 "SNA" ;
VAL_ 1513 APP_sw187_maxTemperature 255 "SNA" ;
VAL_ 1513 APP_sw188_exitStatus 1 "STREAM_EXIT_FAULT" 0 "STREAM_EXIT_NOMINAL" ;
VAL_ 1513 APP_sw188_tempMonitorFailure 2 "TEMPERATURE_MONITOR_OTHER_FAILURE" 1 "TEMPERATURE_OUT_OF_SPEC" 0 "TEMPERATURE_MONITOR_NO_FAILURE" ;
VAL_ 1513 APP_sw188_imagerHeartbeat 3 "IMAGER_HEARTBEAT_SNA" 1 "IMAGER_HEARTBEAT_STATIC" 0 "IMAGER_HEARTBEAT_NOMINAL" ;
VAL_ 1513 APP_sw188_serializerCrcErrCount 255 "SNA" ;
VAL_ 1513 APP_sw188_currentTemperature 255 "SNA" ;
VAL_ 1513 APP_sw188_minTemperature 255 "SNA" ;
VAL_ 1513 APP_sw188_maxTemperature 255 "SNA" ;
VAL_ 1513 APP_sw189_exitStatus 1 "STREAM_EXIT_FAULT" 0 "STREAM_EXIT_NOMINAL" ;
VAL_ 1513 APP_sw189_tempMonitorFailure 2 "TEMPERATURE_MONITOR_OTHER_FAILURE" 1 "TEMPERATURE_OUT_OF_SPEC" 0 "TEMPERATURE_MONITOR_NO_FAILURE" ;
VAL_ 1513 APP_sw189_imagerHeartbeat 3 "IMAGER_HEARTBEAT_SNA" 1 "IMAGER_HEARTBEAT_STATIC" 0 "IMAGER_HEARTBEAT_NOMINAL" ;
VAL_ 1513 APP_sw189_serializerCrcErrCount 255 "SNA" ;
VAL_ 1513 APP_sw189_currentTemperature 255 "SNA" ;
VAL_ 1513 APP_sw189_minTemperature 255 "SNA" ;
VAL_ 1513 APP_sw189_maxTemperature 255 "SNA" ;
VAL_ 1513 APP_sw190_exitStatus 1 "STREAM_EXIT_FAULT" 0 "STREAM_EXIT_NOMINAL" ;
VAL_ 1513 APP_sw190_tempMonitorFailure 2 "TEMPERATURE_MONITOR_OTHER_FAILURE" 1 "TEMPERATURE_OUT_OF_SPEC" 0 "TEMPERATURE_MONITOR_NO_FAILURE" ;
VAL_ 1513 APP_sw190_imagerHeartbeat 3 "IMAGER_HEARTBEAT_SNA" 1 "IMAGER_HEARTBEAT_STATIC" 0 "IMAGER_HEARTBEAT_NOMINAL" ;
VAL_ 1513 APP_sw190_serializerCrcErrCount 255 "SNA" ;
VAL_ 1513 APP_sw190_currentTemperature 255 "SNA" ;
VAL_ 1513 APP_sw190_minTemperature 255 "SNA" ;
VAL_ 1513 APP_sw190_maxTemperature 255 "SNA" ;
VAL_ 1513 APP_sw191_abortReason 255 "ABORT_REASON_MAX" 49 "ABORT_ONCOMING_LANE" 48 "ABORT_HEADLIGHT_OFF_AT_NIGHT" 47 "ABORT_IBOOSTER_MIA" 46 "ABORT_INTEGRATOR_HEALTH_CRITICAL" 45 "ABORT_USER_OVERRIDE_STRIKEOUT" 44 "ABORT_SEATBELT_UNBUCKLED" 43 "ABORT_PERCEPTION_HEALTH_VISION" 42 "ABORT_INVALID_VEHICLE_SPEED" 41 "ABORT_INVALID_DI_PEDAL_POS" 40 "ABORT_W048_FEATURES_DISABLED" 39 "ABORT_EPAS_STEERING_ANGLE_INVALID" 38 "ABORT_STEERING_SATURATED_LANE_DEPARTURE" 37 "ABORT_REACHED_END_OF_NAV_STOP" 36 "ABORT_GORE_INCURSION" 35 "ABORT_MISSION_PLANNER_NO_VISION_LANES_FOUND" 34 "ABORT_CONTROLLER_REF_TOO_SHORT" 33 "ABORT_AEB" 32 "ABORT_CONTROLLER_BAD_REF_UPDATE" 31 "ABORT_CONTROLLER_STALE_LOCALIZATION" 30 "ABORT_CONTROLLER_STALE_REFERENCE" 29 "ABORT_MAP_HEALTH" 28 "ABORT_THERMAL_ISSUE" 27 "ABORT_CONTROLLER_NOT_ALLOWED" 26 "ABORT_CONTROLLER_SOLVER" 25 "ABORT_CONTROLLER_REFERENCE" 24 "ABORT_ROAD_ESTIMATOR_HEALTH" 23 "ABORT_ACC_FAULT" 22 "ABORT_ACC_CANCEL_SILENT" 21 "ABORT_ACC_CANCEL_GENERIC" 20 "ABORT_RADAR_FAULT" 19 "ABORT_RADAR_BLIND" 18 "ABORT_CAMERA_CALIBRATION" 17 "ABORT_CAMERA_FAILSAFES" 16 "ABORT_EPAS_EAC_ERROR" 15 "ABORT_EPAS_EAC_NOT_ACTIVE" 14 "ABORT_VEHICLE_SPEED_ABOVE_MAX" 13 "ABORT_TRAILER_MODE_ACTIVE" 12 "ABORT_USER_DISABLED" 11 "ABORT_CRUISE_NOT_ACTIVE" 10 "ABORT_CRUISE_FAULT" 9 "ABORT_VCRIGHT_MIA" 8 "ABORT_VCFRONT_MIA" 7 "ABORT_RADAR_MIA" 6 "ABORT_SCCM_MIA" 5 "ABORT_GTW_MIA" 4 "ABORT_EPAS_MIA" 3 "ABORT_ESP_MIA" 2 "ABORT_DI_MIA" 1 "ABORT_WATCHDOG_HEALTH" 0 "ABORT_NONE" ;
VAL_ 1513 APP_sw191_handsOnState 15 "LC_HANDS_ON_SNA" 10 "LC_HANDS_ON_REQD_ESCALATED_CHIME_2" 9 "LC_HANDS_ON_REQD_ESCALATED_CHIME_1" 8 "LC_HANDS_ON_SUSPENDED" 7 "LC_HANDS_ON_REQD_STRUCK_OUT" 6 "LC_HANDS_ON_REQD_SLOWING" 5 "LC_HANDS_ON_REQD_CHIME_2" 4 "LC_HANDS_ON_REQD_CHIME_1" 3 "LC_HANDS_ON_REQD_VISUAL" 2 "LC_HANDS_ON_REQD_NOT_DETECTED" 1 "LC_HANDS_ON_REQD_DETECTED" 0 "LC_HANDS_ON_NOT_REQD" ;
VAL_ 1513 APP_sw191_cruiseState 7 "STATE_PRE_CANCEL" 6 "STATE_PRE_FAULT" 5 "STATE_FAULT" 4 "STATE_OVERRIDE" 3 "STATE_STANDSTILL" 2 "STATE_ENABLED" 1 "STATE_STANDBY" 0 "STATE_UNAVAILABLE" ;
VAL_ 1513 APP_sw191_epasErrorCode 15 "SNA" 14 "ERROR_EPB_INHIBIT" 13 "ERROR_PINION_VEL_DIFF" 12 "ERROR_LOW_ASSIST" 11 "ERROR_HIGH_TORSION_SAFETY" 10 "ERROR_HIGH_MMOT_SAFETY" 9 "ERROR_HIGH_ANGLE_RATE_SAFETY" 8 "ERROR_HIGH_ANGLE_SAFETY" 7 "ERROR_HIGH_ANGLE_RATE_REQ" 6 "ERROR_HIGH_ANGLE_REQ" 5 "EAR_ERROR_MAX_STEER_DELTA" 4 "ERROR_TMP_FAULT" 3 "ERROR_HANDS_ON" 2 "ERROR_MAX_SPEED" 1 "ERROR_MIN_SPEED" 0 "ERROR_IDLE" ;
VAL_ 1513 APP_sw191_referenceHealth 2 "REFERENCE_INDETERMINATE" 1 "REFERENCE_UNHEALTHY" 0 "REFERENCE_HEALTHY" ;
VAL_ 1513 APP_sw191_solverHealth 3 "SOLVER_FAILURE" 2 "SOLVER_CRITICAL" 1 "SOLVER_DEGRADED" 0 "SOLVER_HEALTHY" ;
VAL_ 1513 APP_sw191_roadEstHealth 3 "ROAD_ESTIMATOR_CRITICAL" 2 "ROAD_ESTIMATOR_DEGRADED" 1 "ROAD_ESTIMATOR_UNSTABLE_MEASUREMENTS" 0 "ROAD_ESTIMATOR_HEALTHY" ;
VAL_ 1513 APP_sw191_roadEstMode 2 "ROAD_ESTIMATOR_MODE_FULL" 1 "ROAD_ESTIMATOR_MODE_VL" 0 "ROAD_ESTIMATOR_MODE_MAP" ;
VAL_ 1513 APP_sw191_radarFault 1 "RADAR_FAULT" 0 "NONE" ;
VAL_ 1513 APP_sw191_radarBlind 1 "RADAR_BLIND" 0 "NONE" ;
VAL_ 1513 APP_sw192_speakerFailureType 3 "WAKEUP_ERROR" 2 "SETUP_ERROR" 1 "INIT_ERROR" 0 "INIT_WAITING" ;
VAL_ 1513 APP_sw192_chassisType 3 "CHASSIS_MODEL3" 2 "CHASSIS_MODELX" 1 "CHASSIS_MODELS" 0 "CHASSIS_UNKNOWN" ;
VAL_ 1513 APP_sw192_hardwareType 3 "HARDWARE_3" 2 "HARDWARE_25" 1 "HARDWARE_2" 0 "HARDWARE_UNKNOWN" ;
VAL_ 1513 APP_sw193_outOfFocusImage 1 "True" 0 "False" ;
VAL_ 1513 APP_sw193_impairedVD 1 "True" 0 "False" ;
VAL_ 1513 APP_sw193_blurredImage 1 "True" 0 "False" ;
VAL_ 1513 APP_sw193_smearedSpots 1 "True" 0 "False" ;
VAL_ 1513 APP_sw193_partialBlockage 1 "True" 0 "False" ;
VAL_ 1513 APP_sw193_fullBlockage 1 "True" 0 "False" ;
VAL_ 1513 APP_sw193_smearedHalos 1 "True" 0 "False" ;
VAL_ 1513 APP_sw194_leadDx 255 "SNA" ;
VAL_ 1513 APP_sw194_leadVx 31 "SNA" ;
VAL_ 1513 APP_sw194_leadAx 31 "SNA" ;
VAL_ 1513 APP_sw194_reasonForHold 15 "SNA" 12 "STOPS_BUTTON_TOGGLE" 11 "MISSION_PLANNER_SLOWDOWN_REQUEST" 10 "STANDSTILL_STEERING_OVERRIDE" 9 "CAM_ONLY_CONTROL" 8 "MCP_CONTROL" 7 "DRIVER_SEATBELT" 6 "TRAFFIC_LIGHT" 5 "STOP_SIGN" 4 "CAM_STOP_AND_GO" 3 "TARGET_LOSS" 2 "ULTRASONIC_OBSTACLE" 1 "CAM_PEDESTRIAN" 0 "TIMEOUT" ;
VAL_ 1513 APP_sw199_internalState 14 "APC_INT_STATE_CENTER_STW" 13 "APC_INT_STATE_GEAR_CHANGE" 12 "APC_INT_STATE_PARKED" 11 "APC_INT_STATE_COMPLETE_UNPARKED" 10 "APC_INT_STATE_COMPLETE" 9 "APC_INT_STATE_ABORT" 8 "APC_INT_STATE_RESTART" 7 "APC_INT_STATE_PAUSE_USER_CONTROL" 6 "APC_INT_STATE_PAUSE_OBSTACLE_CONTROL" 5 "APC_INT_STATE_REVERSE_CONTROL" 4 "APC_INT_STATE_FORWARD_CONTROL" 3 "APC_INT_STATE_PREGUIDANCE" 2 "APC_INT_STATE_PRECRUISE" 1 "APC_INT_STATE_SEARCHING" 0 "APC_INT_STATE_DISABLED" ;
VAL_ 1513 APP_sw199_abortCodePARK 31 "SNA" 17 "ERROR" 16 "SYSTEM_FAULT" 15 "SYSTEM_SERVICE" 14 "APP_ABORT" 13 "EPAS_FAULT" 12 "VEHICLE_DYNAMICS_INTERVENTION" 11 "HANDS_ON_DETECTED" 10 "FULL_WARNING_ON_BOTH_SIDES" 9 "PARK_SPACE_TOO_SMALL" 8 "OBSTACLE_ON_PATH" 7 "MAX_YAW_ANGLE_REACHED" 6 "MAX_SWA_DEV_EXCEEDED" 5 "OFF_TRACK" 4 "UNCONTROLLED_TRAVEL_DIST_REACHED" 3 "NO_VALID_PATH" 2 "MAX_NUM_OF_MOVES" 1 "VELOCITY_TOO_HIGH" 0 "NONE" ;
VAL_ 1513 APP_sw199_abortCodeDas 28 "APC_ABORT_TOO_MANY_GEAR_CHANGES" 27 "APC_ABORT_TRAILER_MODE" 26 "APC_ABORT_PARKER_HEARTBEAT_MISSING" 25 "APC_ABORT_HEARTBEAT_MISSING" 24 "APC_ABORT_APP_MIA" 23 "APC_ABORT_PAUSE_CYCLES" 22 "APC_ABORT_EPAS_INHIBITED" 21 "APC_ABORT_USER_KEYFOB" 20 "APC_ABORT_SC_MIA" 19 "APC_ABORT_SENSOR_FAILURE" 18 "APC_ABORT_PRECRUISE_TIMEOUT" 17 "APC_ABORT_UI_REQUEST" 16 "APC_ABORT_LOST_DI_CONTROL" 15 "APC_ABORT_PARK_GEAR" 14 "APC_ABORT_RESTART_TIMEOUT" 13 "APC_ABORT_PAUSE_USER_TIMEOUT" 12 "APC_ABORT_PAUSE_OBSTACLE_TIMEOUT" 11 "APC_ABORT_ESP_MIA" 10 "APC_ABORT_SCCM_MIA" 9 "APC_ABORT_MCU_MIA" 8 "APC_ABORT_DI_MIA" 7 "APC_ABORT_EPAS_MIA" 6 "APC_ABORT_PARK_MIA" 5 "APC_ABORT_PREGUIDANCE_TIMEOUT" 4 "APC_ABORT_INVALID_SPACE" 3 "APC_ABORT_MCU_REQUEST_MISMATCH" 2 "APC_ABORT_PARK_GUIDANCE_ENDED" 1 "APC_ABORT_LOST_ANGLE_CONTROL" 0 "APC_ABORT_NONE" ;
VAL_ 1513 APP_sw200_autopilotIntState 15 "PRECANCEL" 14 "DRIVER_STEERING_OVERRIDE" 13 "PREABORTED" 12 "FAULT" 11 "ABORTED" 10 "ABORTING" 9 "CHECK_ACTIVATION_WHILE_UNAVAILABLE" 8 "CHECK_ACTIVATION_WHILE_DISABLED" 7 "ACTIVE_RESTRICTED" 6 "ACTIVE_NOMINAL" 5 "PREACTIVATION" 4 "CHECK_FOR_ACTIVATION" 3 "AVAILABLE" 2 "UNAVAILABLE" 1 "DISABLED" 0 "NO_AUTOPILOT" ;
VAL_ 1513 APP_sw201_viewRangeOAL 5 "ANOMALY_LEVEL_5" 4 "ANOMALY_LEVEL_4" 3 "ANOMALY_LEVEL_3" 2 "ANOMALY_LEVEL_2" 1 "ANOMALY_LEVEL_1" 0 "ANOMALY_LEVEL_0" ;
VAL_ 1513 APP_sw201_steeringErrorOAL 5 "ANOMALY_LEVEL_5" 4 "ANOMALY_LEVEL_4" 3 "ANOMALY_LEVEL_3" 2 "ANOMALY_LEVEL_2" 1 "ANOMALY_LEVEL_1" 0 "ANOMALY_LEVEL_0" ;
VAL_ 1513 APP_sw201_virtualLaneInputOAL 5 "ANOMALY_LEVEL_5" 4 "ANOMALY_LEVEL_4" 3 "ANOMALY_LEVEL_3" 2 "ANOMALY_LEVEL_2" 1 "ANOMALY_LEVEL_1" 0 "ANOMALY_LEVEL_0" ;
VAL_ 1513 APP_sw203_roadClass 6 "CLASS_6_MINOR" 5 "CLASS_5" 4 "CLASS_4" 3 "CLASS_3" 2 "CLASS_2" 1 "CLASS_1_MAJOR" 0 "UNKNOWN_INVALID_SNA" ;
VAL_ 1513 APP_sw203_curbType 2 "HIGH_CURB" 1 "LOW_CURB" 0 "VIRTUAL_CURB" ;
VAL_ 1513 APP_sw203_controlType 15 "SNA" 14 "SUMMON" 10 "PAUSE" 9 "SEARCH" 8 "COMPLETE" 7 "ABORT" 6 "PARALLEL_PULL_OUT_TO_RIGHT" 5 "PARALLEL_PULL_OUT_TO_LEFT" 4 "PARK_RIGHT_CROSS" 3 "PARK_RIGHT_PARALLEL" 2 "PARK_LEFT_CROSS" 1 "PARK_LEFT_PARALLEL" 0 "NONE" ;
VAL_ 1513 APP_sw204_frLeftMiddle 255 "SNA" ;
VAL_ 1513 APP_sw204_frRightMiddle 255 "SNA" ;
VAL_ 1513 APP_sw204_frRight 255 "SNA" ;
VAL_ 1513 APP_sw204_frLeft 255 "SNA" ;
VAL_ 1513 APP_sw204_frMiddle 255 "SNA" ;
VAL_ 1513 APP_sw205_rrRightMiddle 255 "SNA" ;
VAL_ 1513 APP_sw205_rrLeftMiddle 255 "SNA" ;
VAL_ 1513 APP_sw205_rrRight 255 "SNA" ;
VAL_ 1513 APP_sw205_rrLeft 255 "SNA" ;
VAL_ 1513 APP_sw205_rrMiddle 255 "SNA" ;
VAL_ 1513 APP_sw205_oocDistance 255 "SNA" ;
VAL_ 1513 APP_sw207_lcUnavailableReason 255 "LC_UNAVAILABLE_UNKNOWN" 80 "RR_UNAVAILABLE_SYSTEM_HEALTH_CRITICAL" 79 "RR_UNAVAILABLE_PERCEPTION_HEALTH_RADAR" 78 "RR_UNAVAILABLE_PERCEPTION_HEALTH_VISION" 77 "RR_UNAVAILABLE_RADAR_BLIND" 76 "RR_UNAVAILABLE_RADAR_FAULT" 75 "RR_UNAVAILABLE_RADAR_MIA" 74 "RR_UNAVAILABLE_ECU_THERMAL_ISSUE" 73 "RR_UNAVAILABLE_AEB_ACTIVE" 72 "RR_UNAVAILABLE_AUTOPARK_STATE" 71 "RR_UNAVAILABLE_STEERING_WHEEL_ANGLE" 70 "RR_UNAVAILABLE_FAILED_AUTOSTEER_ACTIVATION" 69 "RR_UNAVAILABLE_INVALID_DI_PEDAL_POS" 68 "RR_UNAVAILABLE_INVALID_VEHICLE_SPEED" 67 "RR_UNAVAILABLE_AP_NOT_CONFIGURED" 66 "RR_UNAVAILABLE_INTEGRATOR_HEALTH_CRITICAL" 65 "RR_UNAVAILABLE_RADAR_VERSION_MISMATCH" 64 "RR_UNAVAILABLE_TRACKED_OBSTACLE_DETECTED" 63 "RR_UNAVAILABLE_SONIC_OBSTACLE_DETECTED" 62 "RR_UNAVAILABLE_PEDESTRIAN_PRESENT_OR_NO_VEHICLE" 61 "RR_UNAVAILABLE_AVAILABILITY_CHECK_HYSTERESIS" 60 "RR_UNAVAILABLE_CAMERA_BLOCKED" 59 "RR_UNAVAILABLE_CAMERA_PITCH" 58 "RR_UNAVAILABLE_CAMERA_CALIBRATION" 57 "RR_UNAVAILABLE_DI_MIA" 56 "RR_UNAVAILABLE_GTW_MIA" 55 "RR_UNAVAILABLE_EPAS_MIA" 54 "RR_UNAVAILABLE_ESP_MIA" 53 "RR_UNAVAILABLE_DI_PARTY_MIA" 52 "RR_UNAVAILABLE_EPAS_PARTY_MIA" 51 "RR_UNAVAILABLE_ESP_PARTY_MIA" 50 "RR_UNAVAILABLE_CONTROL_REFERENCE_UNHEALTHY" 49 "RR_UNAVAILABLE_CONTROL_STALE_REFERENCE" 48 "RR_UNAVAILABLE_CONTROL_STALE_LOCALIZATION" 47 "RR_UNAVAILABLE_CONTROL_BAD_UPDATE" 46 "RR_UNAVAILABLE_CONTROL_REFERENCE_TOO_SHORT" 45 "RR_UNAVAILABLE_CONTROL_INDETERMINATE" 44 "RR_UNAVAILABLE_BELOW_MIN_SPEED" 43 "LC_UNAVAILABLE_SEATBELT_UNBUCKLED" 42 "RR_UNAVAILABLE_EPAS_STEERING_ANGLE_INVALID" 41 "RR_UNAVAILABLE_SYNTHESIZED_ACC_LANES_ACTIVE" 40 "RR_UNAVAILABLE_MCU_LATERAL_CONTROL_DISABLED" 39 "RR_UNAVAILABLE_INVALID_LANE_LINE_TYPE" 38 "RR_UNAVAILABLE_ROAD_ESTIMATOR_NOT_ALLOWED" 37 "RR_UNAVAILABLE_VEHICLE_SPEED_ABOVE_MAX_HYST" 36 "RR_UNAVAILABLE_SPEED_LIMIT_EXCEEDED" 35 "RR_UNAVAILABLE_CONTROL_SOLVER_UNHEALTHY" 34 "RR_UNAVAILABLE_CONTROL_PATH_UNHEALTHY" 33 "RR_UNAVAILABLE_CONTROL_OUTSIDE_LIMITS" 32 "RR_UNAVAILABLE_USER_STRIKEOUT" 31 "RR_UNAVAILABLE_EAC_REQUEST_TIMEOUT" 30 "RR_UNAVAILABLE_HK_TW_RESTRICTED" 29 "RR_UNAVAILABLE_TRAILER_MODE_ACTIVE" 28 "RR_UNAVAILABLE_CAMERA_FAILSAFES" 27 "RR_UNAVAILABLE_STEERING_LIMITS_EXCEEDED" 26 "RR_UNAVAILABLE_VEHICLE_SPEED_ABOVE_MAX" 25 "RR_UNAVAILABLE_VEHICLE_NOT_IN_DRIVE" 24 "RR_UNAVAILABLE_CRUISE_FAULT" 23 "RR_UNAVAILABLE_COMPONENT_NOT_READY" 22 "RR_UNAVAILABLE_COMPONENT_MIA" 21 "RR_UNAVAILABLE_EPAS_EAC_DENIED" 20 "RR_UNAVAILABLE_NONE" 19 "LC_UNAVAILABLE_VEHICLE_SPEED_ABOVE_MAX_HYST" 18 "LC_UNAVAILABLE_NOT_ON_HIGHWAY" 17 "LC_UNAVAILABLE_SPEED_LIMIT_EXCEEDED" 16 "LC_UNAVAILABLE_APP_ME_STATE_NOT_VISION" 15 "LC_UNAVAILABLE_ME_MAIN_STATE_NOT_VISION" 14 "LC_UNAVAILABLE_USER_STRIKEOUT" 13 "LC_UNAVAILABLE_EAC_REQUEST_TIMEOUT" 12 "LC_UNAVAILABLE_CAM_MSG_MIA" 11 "LC_UNAVAILABLE_HK_TW_RESTRICTED" 10 "LC_UNAVAILABLE_CAM_WATCHDOG" 9 "LC_UNAVAILABLE_TRAILER_MODE_ACTIVE" 8 "LC_UNAVAILABLE_CAMERA_FAILSAFES" 7 "LC_UNAVAILABLE_STEERING_LIMITS_EXCEEDED" 6 "LC_UNAVAILABLE_VEHICLE_SPEED_ABOVE_MAX" 5 "LC_UNAVAILABLE_VEHICLE_NOT_IN_DRIVE" 4 "LC_UNAVAILABLE_CRUISE_FAULT" 3 "LC_UNAVAILABLE_COMPONENT_NOT_READY" 2 "LC_UNAVAILABLE_COMPONENT_MIA" 1 "LC_UNAVAILABLE_EPAS_EAC_DENIED" 0 "LC_UNAVAILABLE_NONE" ;
VAL_ 1513 APP_sw207_appMobileyeStatus 24 "MOBILEYE_STATUS_UNDEFINED" 23 "MOBILEYE_STATUS_TEARDOWN_FLASH_ACCESS_MODE" 22 "MOBILEYE_STATUS_FLASH_READ_MODE" 21 "MOBILEYE_STATUS_SETUP_FLASH_ACCESS_MODE" 20 "MOBILEYE_STATUS_RUNNING_SPTAC_MODE" 19 "MOBILEYE_STATUS_SPTAC_INIT_SENT" 18 "MOBILEYE_STATUS_WAITING_FOR_SPTAC_INIT" 17 "MOBILEYE_STATUS_BURN_EDR_MODE" 16 "MOBILEYE_STATUS_SPC_INIT_SENT" 15 "MOBILEYE_STATUS_WAITING_FOR_SPC_INIT" 14 "MOBILEYE_STATUS_ERROR" 13 "MOBILEYE_STATUS_LATCHING_FAILURE" 12 "MOBILEYE_STATUS_UPDATING" 11 "MOBILEYE_STATUS_RUNNING_DV_MODE" 10 "MOBILEYE_STATUS_WAITING_FOR_DV" 9 "MOBILEYE_STATUS_RUNNING_TAC_MODE" 8 "MOBILEYE_STATUS_RUNNING_SPC_MODE" 7 "MOBILEYE_STATUS_RUNNING_VISION_MODE" 6 "MOBILEYE_STATUS_TAC_INIT_SENT" 5 "MOBILEYE_STATUS_WAITING_FOR_TAC_INIT" 4 "MOBILEYE_STATUS_VISION_INIT_SENT" 3 "MOBILEYE_STATUS_WAITING_FOR_VISION_INIT" 2 "MOBILEYE_STATUS_WAITING_FOR_BOOT" 1 "MOBILEYE_STATUS_POWER_OFF" 0 "MOBILEYE_STATUS_POWER_CYCLE" ;
VAL_ 1513 APP_sw207_eyeq3MainState 172 "EYEQ_MESP_MAIN_STATE_TAC2" 170 "EYEQ_MESP_MAIN_STATE_DV" 146 "EYEQ_MESP_MAIN_STATE_VISION_INIT_PENDING" 133 "EYEQ_MESP_MAIN_STATE_TAC2_INIT_PENDING" 130 "EYEQ_MESP_MAIN_STATE_SPC_INIT_PENDING" 129 "EYEQ_MESP_MAIN_STATE_SPTAC_INIT_PENDING" 34 "EYEQ_MESP_MAIN_STATE_SPC" 33 "EYEQ_MESP_MAIN_STATE_SPTAC" 2 "EYEQ_MESP_MAIN_STATE_VISION" ;
VAL_ 1513 APP_sw218_handsOnState 15 "LC_HANDS_ON_SNA" 9 "LC_HANDS_ON_REQD_ESCALATED_CHIME_2" 8 "LC_HANDS_ON_REQD_ESCALATED_CHIME_1" 7 "LC_HANDS_ON_REQD_STRUCK_OUT" 5 "LC_HANDS_ON_REQD_CHIME_2" 4 "LC_HANDS_ON_REQD_CHIME_1" 3 "LC_HANDS_ON_REQD_VISUAL" 2 "LC_HANDS_ON_REQD_NOT_DETECTED" 1 "LC_HANDS_ON_REQD_DETECTED" 0 "LC_HANDS_ON_NOT_REQD" ;
VAL_ 1513 APP_sw227_sensorSide 1 "VEHICLE_SIDE_RIGHT" 0 "VEHICLE_SIDE_LEFT" ;
VAL_ 1513 APP_sw227_sensorNumber 1 "SENSOR_MIDDLE" 0 "SENSOR_FRONT" ;
VAL_ 1513 APP_sw257_user_sensitivity 3 "SNA" 2 "AEB_SENSITIVITY_LATE" 1 "AEB_SENSITIVITY_AVERAGE" 0 "AEB_SENSITIVITY_EARLY" ;
VAL_ 1513 APP_sw259_previous_lcm_app_state 10 "LCM_STATE_STATIONARY_MANAGEMENT" 9 "LCM_STATE_AEB_OVERRIDE" 8 "LCM_STATE_AEB_ACTIVE" 7 "LCM_STATE_JERK_OVERRIDE" 6 "LCM_STATE_JERK_ACTIVE" 5 "LCM_STATE_FCW_OVERRIDE" 4 "LCM_STATE_FCW_ACTIVE" 3 "LCM_STATE_AVAILABLE" 2 "LCM_STATE_UNAVAILABLE" 1 "LCM_STATE_OFF" 0 "LCM_STATE_FAULT" ;
VAL_ 1513 APP_sw260_user_sensitivity 3 "SNA" 2 "AEB_SENSITIVITY_LATE" 1 "AEB_SENSITIVITY_AVERAGE" 0 "AEB_SENSITIVITY_EARLY" ;
VAL_ 1513 APP_sw263_markerType 7 "LSS_MARKER_TYPE_DOTTED" 6 "LSS_MARKER_TYPE_DASHED" 5 "LSS_MARKER_TYPE_DOUBLE_SOLID" 4 "LSS_MARKER_TYPE_SOLID" 3 "LSS_MARKER_TYPE_UNMARKED" 2 "LSS_MARKER_TYPE_EDGE" 1 "LSS_MARKER_TYPE_INVALID" 0 "LSS_MARKER_TYPE_UNKNOWN" ;
VAL_ 1513 APP_sw263_side 1 "LSS_SIDE_LEFT" 0 "LSS_SIDE_RIGHT" ;
VAL_ 1513 APP_sw263_lssAbortReason 16 "LSS_ABORT_REASON_STEERING_ANGLE_OUT_OF_BOUNDS" 15 "LSS_ABORT_REASON_STEERING_ANGLE_DELTA_TOO_LARGE" 14 "LSS_ABORT_REASON_LANE_CHANGE" 13 "LSS_ABORT_REASON_VEHICLE_MU_LOW" 12 "LSS_ABORT_REASON_TURN_INDICATOR_ON" 11 "LSS_ABORT_REASON_FRONT_OBSTACLE_AVOIDANCE" 10 "LSS_ABORT_REASON_SIDE_OBSTACLE_AVOIDANCE" 9 "LSS_ABORT_REASON_LANE_TOO_NARROW" 8 "LSS_ABORT_REASON_HILLCREST" 7 "LSS_ABORT_REASON_SNOWY_ROAD" 6 "LSS_ABORT_REASON_CONSTRUCTION" 5 "LSS_ABORT_REASON_VDC_ACTIVE" 4 "LSS_ABORT_REASON_TIMER_EXPIRED" 3 "LSS_ABORT_REASON_EAC_STATUS" 2 "LSS_ABORT_REASON_STEERING_WHEEL_TORSION" 1 "LSS_ABORT_REASON_UNAVAILABLE" 0 "LSS_ABORT_REASON_NO_ABORT" ;
VAL_ 1513 APP_sw264_faultReason 15 "LSS_FAULT_REASON_INVALID" 10 "LSS_FAULT_REASON_ELK_ACTIVATIONS" 9 "LSS_FAULT_REASON_LKA_ACTIVATIONS" 8 "LSS_FAULT_REASON_VDC_FAULT" 7 "LSS_FAULT_REASON_EPAS_FAULT" 6 "LSS_FAULT_REASON_CAMERA_FISHEYE" 5 "LSS_FAULT_REASON_CAMERA_NARROW" 4 "LSS_FAULT_REASON_CAMERA_MAIN" 3 "LSS_FAULT_REASON_EPAS_MIA" 2 "LSS_FAULT_REASON_EPAS_UNRESPONSIVE" 1 "LSS_FAULT_REASON_EAC_INHIBIT" 0 "LSS_FAULT_REASON_NO_FAULT" ;
VAL_ 1513 APP_sw265_surroundCameraStatus 2 "CAMERA_PERMANENT_UNAVAILABLE" 1 "CAMERA_TEMPORARY_UNAVAILABLE" 0 "CAMERA_AVAILABLE" ;
VAL_ 1513 APP_sw265_unavailableReason 24 "DON_UNAVAILABLE_AUDIO" 23 "DON_SCENE_TAG_SUN_GLARE" 22 "DON_SCENE_TAG_SEVERE_WEATHER" 21 "DON_SCENE_TAG_LENS_FLARE" 20 "DON_SCENE_TAG_FULLY_BLOCKED" 19 "DON_SCENE_TAG_FOG" 18 "DON_SCENE_TAG_BLURRY" 17 "DON_SCENE_TAG_BAD_CAMERA" 16 "DON_NAV_ROUTE_NOT_ACTIVE" 15 "DON_FEATURE_NOT_ENABLED" 14 "DON_AUTOPILOT_UNAVAILABLE" 13 "DON_INCOMPATIBLE_WAY" 12 "DON_HIGH_CURVATURE" 11 "DON_TOLLBOOTH_DETECTED" 10 "DON_CONSTRUCTION_DETECTED" 9 "DON_AUTO_WIPER_ACTIVE" 8 "DON_IMPLAUSIBLE_MAP_DATA" 7 "DON_GPS_DEGRADED" 6 "DON_ULTRASONICS_INVALID" 5 "DON_EDGE_LOCALIZATION_FAILED" 4 "DON_ROUTE_DOWNLOAD_FAILED" 3 "DON_UNAVAILABLE_CAMERA_BLOCKED" 2 "DON_CAMERA_UNAVAILABLE" 1 "DON_INVALID_NAV_GOAL" 0 "DON_UNAVAILABLE_NONE" ;
VAL_ 1513 APP_sw266_lPillarStreamStatus 7 "CAMERA_STREAM_FINISHED" 6 "CAMERA_STREAM_FAILED" 5 "CAMERA_STREAM_RECOVERING" 4 "CAMERA_STREAM_ACTIVE" 3 "CAMERA_STREAM_INIT_DEFERRED" 2 "CAMERA_STREAM_INIT_FAILED" 1 "CAMERA_STREAM_INITIALIZING" 0 "CAMERA_STREAM_NOT_ACTIVE" ;
VAL_ 1513 APP_sw266_rPillarStreamStatus 7 "CAMERA_STREAM_FINISHED" 6 "CAMERA_STREAM_FAILED" 5 "CAMERA_STREAM_RECOVERING" 4 "CAMERA_STREAM_ACTIVE" 3 "CAMERA_STREAM_INIT_DEFERRED" 2 "CAMERA_STREAM_INIT_FAILED" 1 "CAMERA_STREAM_INITIALIZING" 0 "CAMERA_STREAM_NOT_ACTIVE" ;
VAL_ 1513 APP_sw266_lRepeaterStreamStatus 7 "CAMERA_STREAM_FINISHED" 6 "CAMERA_STREAM_FAILED" 5 "CAMERA_STREAM_RECOVERING" 4 "CAMERA_STREAM_ACTIVE" 3 "CAMERA_STREAM_INIT_DEFERRED" 2 "CAMERA_STREAM_INIT_FAILED" 1 "CAMERA_STREAM_INITIALIZING" 0 "CAMERA_STREAM_NOT_ACTIVE" ;
VAL_ 1513 APP_sw266_rRepeaterStreamStatus 7 "CAMERA_STREAM_FINISHED" 6 "CAMERA_STREAM_FAILED" 5 "CAMERA_STREAM_RECOVERING" 4 "CAMERA_STREAM_ACTIVE" 3 "CAMERA_STREAM_INIT_DEFERRED" 2 "CAMERA_STREAM_INIT_FAILED" 1 "CAMERA_STREAM_INITIALIZING" 0 "CAMERA_STREAM_NOT_ACTIVE" ;
VAL_ 1513 APP_sw266_backupStreamStatus 7 "CAMERA_STREAM_FINISHED" 6 "CAMERA_STREAM_FAILED" 5 "CAMERA_STREAM_RECOVERING" 4 "CAMERA_STREAM_ACTIVE" 3 "CAMERA_STREAM_INIT_DEFERRED" 2 "CAMERA_STREAM_INIT_FAILED" 1 "CAMERA_STREAM_INITIALIZING" 0 "CAMERA_STREAM_NOT_ACTIVE" ;
VAL_ 1513 APP_sw269_emergencyLaneKeep 31 "LSS_LIMITED_SNA" 15 "LSS_LIMITED_OFF_ROAD_MODE" 14 "LSS_LIMITED_TRACK_MODE" 13 "LSS_LIMITED_ULTRASONICS_BLOCKED" 12 "LSS_LIMITED_ABOVE_MAX_SPEED" 11 "LSS_LIMITED_WEATHER" 10 "LSS_LIMITED_CONSTRUCTION" 9 "LSS_LIMITED_TURN_INDICATOR_FAULT" 8 "LSS_LIMITED_FISHEYE_CAMERA" 7 "LSS_LIMITED_NARROW_CAMERA" 6 "LSS_LIMITED_MAIN_CAMERA" 5 "LSS_LIMITED_BACKUP_CAMERA" 4 "LSS_LIMITED_RIGHT_REPEATER_CAMERA" 3 "LSS_LIMITED_LEFT_REPEATER_CAMERA" 2 "LSS_LIMITED_RIGHT_PILLAR_CAMERA" 1 "LSS_LIMITED_LEFT_PILLAR_CAMERA" 0 "LSS_NOMINAL" ;
VAL_ 1513 APP_sw269_laneKeepAssist 31 "LSS_LIMITED_SNA" 15 "LSS_LIMITED_OFF_ROAD_MODE" 14 "LSS_LIMITED_TRACK_MODE" 13 "LSS_LIMITED_ULTRASONICS_BLOCKED" 12 "LSS_LIMITED_ABOVE_MAX_SPEED" 11 "LSS_LIMITED_WEATHER" 10 "LSS_LIMITED_CONSTRUCTION" 9 "LSS_LIMITED_TURN_INDICATOR_FAULT" 8 "LSS_LIMITED_FISHEYE_CAMERA" 7 "LSS_LIMITED_NARROW_CAMERA" 6 "LSS_LIMITED_MAIN_CAMERA" 5 "LSS_LIMITED_BACKUP_CAMERA" 4 "LSS_LIMITED_RIGHT_REPEATER_CAMERA" 3 "LSS_LIMITED_LEFT_REPEATER_CAMERA" 2 "LSS_LIMITED_RIGHT_PILLAR_CAMERA" 1 "LSS_LIMITED_LEFT_PILLAR_CAMERA" 0 "LSS_NOMINAL" ;
VAL_ 1513 APP_sw269_blindspot 31 "LSS_LIMITED_SNA" 15 "LSS_LIMITED_OFF_ROAD_MODE" 14 "LSS_LIMITED_TRACK_MODE" 13 "LSS_LIMITED_ULTRASONICS_BLOCKED" 12 "LSS_LIMITED_ABOVE_MAX_SPEED" 11 "LSS_LIMITED_WEATHER" 10 "LSS_LIMITED_CONSTRUCTION" 9 "LSS_LIMITED_TURN_INDICATOR_FAULT" 8 "LSS_LIMITED_FISHEYE_CAMERA" 7 "LSS_LIMITED_NARROW_CAMERA" 6 "LSS_LIMITED_MAIN_CAMERA" 5 "LSS_LIMITED_BACKUP_CAMERA" 4 "LSS_LIMITED_RIGHT_REPEATER_CAMERA" 3 "LSS_LIMITED_LEFT_REPEATER_CAMERA" 2 "LSS_LIMITED_RIGHT_PILLAR_CAMERA" 1 "LSS_LIMITED_LEFT_PILLAR_CAMERA" 0 "LSS_NOMINAL" ;
VAL_ 1513 APP_sw269_laneDepartureWarning 31 "LSS_LIMITED_SNA" 15 "LSS_LIMITED_OFF_ROAD_MODE" 14 "LSS_LIMITED_TRACK_MODE" 13 "LSS_LIMITED_ULTRASONICS_BLOCKED" 12 "LSS_LIMITED_ABOVE_MAX_SPEED" 11 "LSS_LIMITED_WEATHER" 10 "LSS_LIMITED_CONSTRUCTION" 9 "LSS_LIMITED_TURN_INDICATOR_FAULT" 8 "LSS_LIMITED_FISHEYE_CAMERA" 7 "LSS_LIMITED_NARROW_CAMERA" 6 "LSS_LIMITED_MAIN_CAMERA" 5 "LSS_LIMITED_BACKUP_CAMERA" 4 "LSS_LIMITED_RIGHT_REPEATER_CAMERA" 3 "LSS_LIMITED_LEFT_REPEATER_CAMERA" 2 "LSS_LIMITED_RIGHT_PILLAR_CAMERA" 1 "LSS_LIMITED_LEFT_PILLAR_CAMERA" 0 "LSS_NOMINAL" ;
VAL_ 1513 APP_sw270_emergencyLaneKeep 31 "LSS_LIMITED_SNA" 15 "LSS_LIMITED_OFF_ROAD_MODE" 14 "LSS_LIMITED_TRACK_MODE" 13 "LSS_LIMITED_ULTRASONICS_BLOCKED" 12 "LSS_LIMITED_ABOVE_MAX_SPEED" 11 "LSS_LIMITED_WEATHER" 10 "LSS_LIMITED_CONSTRUCTION" 9 "LSS_LIMITED_TURN_INDICATOR_FAULT" 8 "LSS_LIMITED_FISHEYE_CAMERA" 7 "LSS_LIMITED_NARROW_CAMERA" 6 "LSS_LIMITED_MAIN_CAMERA" 5 "LSS_LIMITED_BACKUP_CAMERA" 4 "LSS_LIMITED_RIGHT_REPEATER_CAMERA" 3 "LSS_LIMITED_LEFT_REPEATER_CAMERA" 2 "LSS_LIMITED_RIGHT_PILLAR_CAMERA" 1 "LSS_LIMITED_LEFT_PILLAR_CAMERA" 0 "LSS_NOMINAL" ;
VAL_ 1513 APP_sw270_laneKeepAssist 31 "LSS_LIMITED_SNA" 15 "LSS_LIMITED_OFF_ROAD_MODE" 14 "LSS_LIMITED_TRACK_MODE" 13 "LSS_LIMITED_ULTRASONICS_BLOCKED" 12 "LSS_LIMITED_ABOVE_MAX_SPEED" 11 "LSS_LIMITED_WEATHER" 10 "LSS_LIMITED_CONSTRUCTION" 9 "LSS_LIMITED_TURN_INDICATOR_FAULT" 8 "LSS_LIMITED_FISHEYE_CAMERA" 7 "LSS_LIMITED_NARROW_CAMERA" 6 "LSS_LIMITED_MAIN_CAMERA" 5 "LSS_LIMITED_BACKUP_CAMERA" 4 "LSS_LIMITED_RIGHT_REPEATER_CAMERA" 3 "LSS_LIMITED_LEFT_REPEATER_CAMERA" 2 "LSS_LIMITED_RIGHT_PILLAR_CAMERA" 1 "LSS_LIMITED_LEFT_PILLAR_CAMERA" 0 "LSS_NOMINAL" ;
VAL_ 1513 APP_sw270_blindspot 31 "LSS_LIMITED_SNA" 15 "LSS_LIMITED_OFF_ROAD_MODE" 14 "LSS_LIMITED_TRACK_MODE" 13 "LSS_LIMITED_ULTRASONICS_BLOCKED" 12 "LSS_LIMITED_ABOVE_MAX_SPEED" 11 "LSS_LIMITED_WEATHER" 10 "LSS_LIMITED_CONSTRUCTION" 9 "LSS_LIMITED_TURN_INDICATOR_FAULT" 8 "LSS_LIMITED_FISHEYE_CAMERA" 7 "LSS_LIMITED_NARROW_CAMERA" 6 "LSS_LIMITED_MAIN_CAMERA" 5 "LSS_LIMITED_BACKUP_CAMERA" 4 "LSS_LIMITED_RIGHT_REPEATER_CAMERA" 3 "LSS_LIMITED_LEFT_REPEATER_CAMERA" 2 "LSS_LIMITED_RIGHT_PILLAR_CAMERA" 1 "LSS_LIMITED_LEFT_PILLAR_CAMERA" 0 "LSS_NOMINAL" ;
VAL_ 1513 APP_sw270_laneDepartureWarning 31 "LSS_LIMITED_SNA" 15 "LSS_LIMITED_OFF_ROAD_MODE" 14 "LSS_LIMITED_TRACK_MODE" 13 "LSS_LIMITED_ULTRASONICS_BLOCKED" 12 "LSS_LIMITED_ABOVE_MAX_SPEED" 11 "LSS_LIMITED_WEATHER" 10 "LSS_LIMITED_CONSTRUCTION" 9 "LSS_LIMITED_TURN_INDICATOR_FAULT" 8 "LSS_LIMITED_FISHEYE_CAMERA" 7 "LSS_LIMITED_NARROW_CAMERA" 6 "LSS_LIMITED_MAIN_CAMERA" 5 "LSS_LIMITED_BACKUP_CAMERA" 4 "LSS_LIMITED_RIGHT_REPEATER_CAMERA" 3 "LSS_LIMITED_LEFT_REPEATER_CAMERA" 2 "LSS_LIMITED_RIGHT_PILLAR_CAMERA" 1 "LSS_LIMITED_LEFT_PILLAR_CAMERA" 0 "LSS_NOMINAL" ;
VAL_ 1513 APP_sw271_abortReason 23 "ALC_ABORT_DESTINATION_LANE_UNSTABLE" 22 "ALC_ABORT_ULC_SNOOZED" 21 "ALC_ABORT_SOURCE_AND_TARGET_LANES_MERGED" 20 "ALC_ABORT_NO_HANDS_ON" 19 "ALC_ABORT_TOLL_BOOTH_DETECTED" 18 "ALC_ABORT_CONSTRUCTION_DETECTED" 17 "ALC_ABORT_GORE_POINT" 16 "ALC_ABORT_ALC_REQUEST_BEFORE_ULC_CONFIRM" 15 "ALC_ABORT_ULC_CONFIRMATION_TIMEOUT" 14 "ALC_ABORT_HIGH_ALC_PROGRESS_ERROR" 13 "ALC_ABORT_ULC_BLINKER_TIMEOUT" 12 "ALC_ABORT_REQUESTED_BEHAVIOR_CHANGED" 11 "ALC_ABORT_BELOW_MIN_SPEED" 10 "ALC_ABORT_INVALID_BEHAVIOR" 9 "ALC_ABORT_AUTOSTEER_ACTIVATED" 8 "ALC_ABORT_LOST_VISION_POSE" 7 "ALC_ABORT_INVALID_MODE" 6 "ALC_ABORT_FORK_AVAILABLE" 5 "ALC_ABORT_LINE_TYPE" 4 "ALC_ABORT_BLIND_SPOT_OCCUPIED_TIMEOUT" 3 "ALC_ABORT_BLINKER_CHANGE" 2 "ALC_ABORT_ALC_TIMEOUT" 1 "ALC_ABORT_CONTROL_INACTIVE" 0 "ALC_ABORT_NONE" ;
VAL_ 1513 APP_sw271_direction 1 "ALC_DIRECTION_LEFT" 0 "ALC_DIRECTION_RIGHT" ;
VAL_ 1513 APP_sw272_unavailableReason 11 "ALC_AUTOPILOT_ABORTING" 10 "ALC_BLINKER_UNLATCHED" 9 "ALC_NO_REAR_OBJECT_DETECTED" 8 "ALC_CRITICAL_SITUATION" 7 "ALC_BLINDSPOT_RESTRICTED" 6 "ALC_ULTRASONICS_NOT_READY" 5 "ALC_FORK_MODE" 4 "ALC_NO_LANES" 3 "ALC_SPEED" 2 "ALC_ROAD_NOT_APPROPRIATE" 1 "ALC_NOT_ENABLED" 0 "ALC_NONE" ;
VAL_ 1513 APP_sw273_eventType 1 "APP_LSS_EVENT_TYPE_ELK" 0 "APP_LSS_EVENT_TYPE_LKA" ;
VAL_ 1513 APP_sw273_collisionType 4 "APP_LSS_COLLISION_TYPE_ROAD_EDGE" 3 "APP_LSS_COLLISION_TYPE_ONCOMING" 2 "APP_LSS_COLLISION_TYPE_ADJACENT" 1 "APP_LSS_COLLISION_TYPE_OVERTAKING" 0 "APP_LSS_COLLISION_TYPE_NONE" ;
VAL_ 1513 APP_sw273_side 1 "LSS_SIDE_LEFT" 0 "LSS_SIDE_RIGHT" ;
VAL_ 1513 APP_sw274_exitStatus 1 "STREAM_EXIT_FAULT" 0 "STREAM_EXIT_NOMINAL" ;
VAL_ 1513 APP_sw274_tempMonitorFailure 2 "TEMPERATURE_MONITOR_OTHER_FAILURE" 1 "TEMPERATURE_OUT_OF_SPEC" 0 "TEMPERATURE_MONITOR_NO_FAILURE" ;
VAL_ 1513 APP_sw274_imagerHeartbeat 3 "IMAGER_HEARTBEAT_SNA" 1 "IMAGER_HEARTBEAT_STATIC" 0 "IMAGER_HEARTBEAT_NOMINAL" ;
VAL_ 1513 APP_sw274_serializerCrcErrCount 255 "SNA" ;
VAL_ 1513 APP_sw274_currentTemperature 255 "SNA" ;
VAL_ 1513 APP_sw274_minTemperature 255 "SNA" ;
VAL_ 1513 APP_sw274_maxTemperature 255 "SNA" ;
VAL_ 1513 APP_sw275_exitStatus 1 "STREAM_EXIT_FAULT" 0 "STREAM_EXIT_NOMINAL" ;
VAL_ 1513 APP_sw275_tempMonitorFailure 2 "TEMPERATURE_MONITOR_OTHER_FAILURE" 1 "TEMPERATURE_OUT_OF_SPEC" 0 "TEMPERATURE_MONITOR_NO_FAILURE" ;
VAL_ 1513 APP_sw275_imagerHeartbeat 3 "IMAGER_HEARTBEAT_SNA" 1 "IMAGER_HEARTBEAT_STATIC" 0 "IMAGER_HEARTBEAT_NOMINAL" ;
VAL_ 1513 APP_sw275_serializerCrcErrCount 255 "SNA" ;
VAL_ 1513 APP_sw275_currentTemperature 255 "SNA" ;
VAL_ 1513 APP_sw275_minTemperature 255 "SNA" ;
VAL_ 1513 APP_sw275_maxTemperature 255 "SNA" ;
VAL_ 1513 APP_sw276_exitStatus 1 "STREAM_EXIT_FAULT" 0 "STREAM_EXIT_NOMINAL" ;
VAL_ 1513 APP_sw276_tempMonitorFailure 2 "TEMPERATURE_MONITOR_OTHER_FAILURE" 1 "TEMPERATURE_OUT_OF_SPEC" 0 "TEMPERATURE_MONITOR_NO_FAILURE" ;
VAL_ 1513 APP_sw276_imagerHeartbeat 3 "IMAGER_HEARTBEAT_SNA" 1 "IMAGER_HEARTBEAT_STATIC" 0 "IMAGER_HEARTBEAT_NOMINAL" ;
VAL_ 1513 APP_sw276_serializerCrcErrCount 255 "SNA" ;
VAL_ 1513 APP_sw276_currentTemperature 255 "SNA" ;
VAL_ 1513 APP_sw276_minTemperature 255 "SNA" ;
VAL_ 1513 APP_sw276_maxTemperature 255 "SNA" ;
VAL_ 1513 APP_sw277_exitStatus 1 "STREAM_EXIT_FAULT" 0 "STREAM_EXIT_NOMINAL" ;
VAL_ 1513 APP_sw277_tempMonitorFailure 2 "TEMPERATURE_MONITOR_OTHER_FAILURE" 1 "TEMPERATURE_OUT_OF_SPEC" 0 "TEMPERATURE_MONITOR_NO_FAILURE" ;
VAL_ 1513 APP_sw277_imagerHeartbeat 3 "IMAGER_HEARTBEAT_SNA" 1 "IMAGER_HEARTBEAT_STATIC" 0 "IMAGER_HEARTBEAT_NOMINAL" ;
VAL_ 1513 APP_sw277_serializerCrcErrCount 255 "SNA" ;
VAL_ 1513 APP_sw277_currentTemperature 255 "SNA" ;
VAL_ 1513 APP_sw277_minTemperature 255 "SNA" ;
VAL_ 1513 APP_sw277_maxTemperature 255 "SNA" ;
VAL_ 1513 APP_sw278_exitStatus 1 "STREAM_EXIT_FAULT" 0 "STREAM_EXIT_NOMINAL" ;
VAL_ 1513 APP_sw278_tempMonitorFailure 2 "TEMPERATURE_MONITOR_OTHER_FAILURE" 1 "TEMPERATURE_OUT_OF_SPEC" 0 "TEMPERATURE_MONITOR_NO_FAILURE" ;
VAL_ 1513 APP_sw278_imagerHeartbeat 3 "IMAGER_HEARTBEAT_SNA" 1 "IMAGER_HEARTBEAT_STATIC" 0 "IMAGER_HEARTBEAT_NOMINAL" ;
VAL_ 1513 APP_sw278_serializerCrcErrCount 255 "SNA" ;
VAL_ 1513 APP_sw278_currentTemperature 255 "SNA" ;
VAL_ 1513 APP_sw278_minTemperature 255 "SNA" ;
VAL_ 1513 APP_sw278_maxTemperature 255 "SNA" ;
VAL_ 1513 APP_sw279_exitStatus 1 "STREAM_EXIT_FAULT" 0 "STREAM_EXIT_NOMINAL" ;
VAL_ 1513 APP_sw279_tempMonitorFailure 2 "TEMPERATURE_MONITOR_OTHER_FAILURE" 1 "TEMPERATURE_OUT_OF_SPEC" 0 "TEMPERATURE_MONITOR_NO_FAILURE" ;
VAL_ 1513 APP_sw279_imagerHeartbeat 3 "IMAGER_HEARTBEAT_SNA" 1 "IMAGER_HEARTBEAT_STATIC" 0 "IMAGER_HEARTBEAT_NOMINAL" ;
VAL_ 1513 APP_sw279_serializerCrcErrCount 255 "SNA" ;
VAL_ 1513 APP_sw279_currentTemperature 255 "SNA" ;
VAL_ 1513 APP_sw279_minTemperature 255 "SNA" ;
VAL_ 1513 APP_sw279_maxTemperature 255 "SNA" ;
VAL_ 1513 APP_sw280_exitStatus 1 "STREAM_EXIT_FAULT" 0 "STREAM_EXIT_NOMINAL" ;
VAL_ 1513 APP_sw280_tempMonitorFailure 2 "TEMPERATURE_MONITOR_OTHER_FAILURE" 1 "TEMPERATURE_OUT_OF_SPEC" 0 "TEMPERATURE_MONITOR_NO_FAILURE" ;
VAL_ 1513 APP_sw280_imagerHeartbeat 3 "IMAGER_HEARTBEAT_SNA" 1 "IMAGER_HEARTBEAT_STATIC" 0 "IMAGER_HEARTBEAT_NOMINAL" ;
VAL_ 1513 APP_sw280_serializerCrcErrCount 255 "SNA" ;
VAL_ 1513 APP_sw280_currentTemperature 255 "SNA" ;
VAL_ 1513 APP_sw280_minTemperature 255 "SNA" ;
VAL_ 1513 APP_sw280_maxTemperature 255 "SNA" ;
VAL_ 1513 APP_sw281_exitStatus 1 "STREAM_EXIT_FAULT" 0 "STREAM_EXIT_NOMINAL" ;
VAL_ 1513 APP_sw281_tempMonitorFailure 2 "TEMPERATURE_MONITOR_OTHER_FAILURE" 1 "TEMPERATURE_OUT_OF_SPEC" 0 "TEMPERATURE_MONITOR_NO_FAILURE" ;
VAL_ 1513 APP_sw281_imagerHeartbeat 3 "IMAGER_HEARTBEAT_SNA" 1 "IMAGER_HEARTBEAT_STATIC" 0 "IMAGER_HEARTBEAT_NOMINAL" ;
VAL_ 1513 APP_sw281_serializerCrcErrCount 255 "SNA" ;
VAL_ 1513 APP_sw281_currentTemperature 255 "SNA" ;
VAL_ 1513 APP_sw281_minTemperature 255 "SNA" ;
VAL_ 1513 APP_sw281_maxTemperature 255 "SNA" ;
VAL_ 1513 APP_sw282_exitStatus 1 "STREAM_EXIT_FAULT" 0 "STREAM_EXIT_NOMINAL" ;
VAL_ 1513 APP_sw282_tempMonitorFailure 2 "TEMPERATURE_MONITOR_OTHER_FAILURE" 1 "TEMPERATURE_OUT_OF_SPEC" 0 "TEMPERATURE_MONITOR_NO_FAILURE" ;
VAL_ 1513 APP_sw282_imagerHeartbeat 3 "IMAGER_HEARTBEAT_SNA" 1 "IMAGER_HEARTBEAT_STATIC" 0 "IMAGER_HEARTBEAT_NOMINAL" ;
VAL_ 1513 APP_sw282_serializerCrcErrCount 255 "SNA" ;
VAL_ 1513 APP_sw282_currentTemperature 255 "SNA" ;
VAL_ 1513 APP_sw282_minTemperature 255 "SNA" ;
VAL_ 1513 APP_sw282_maxTemperature 255 "SNA" ;
VAL_ 1513 APP_sw283_appAbortReason 17 "PUBLIC_ROAD_BOUNDARIES_NOT_VALID" 16 "ULTRASONIC_STALE" 15 "VISION_HEALTH_CRITICAL" 14 "RADAR_HEALTH_CRITICAL" 13 "PUBLIC_ROAD" 12 "END_OF_LEASH" 11 "MAX_ALLOWED_DISTANCE" 10 "MAX_ALLOWED_TIME" 9 "AURIX_NOT_ACTIVE" 8 "PHONE_IS_TOO_FAR" 7 "EGO_GPS_UNAVAILABLE" 6 "PHONE_GPS_UNAVAILABLE" 5 "NO_VALID_PATH" 4 "ULTRASONIC_FAULT" 3 "ULTRASONIC_BLOCKED" 2 "CAMERA_BLOCKED" 1 "CAMERA_STREAM" 0 "NONE" ;
VAL_ 1513 APP_sw283_apsAbortReason 28 "APC_ABORT_TOO_MANY_GEAR_CHANGES" 27 "APC_ABORT_TRAILER_MODE" 26 "APC_ABORT_PARKER_HEARTBEAT_MISSING" 25 "APC_ABORT_HEARTBEAT_MISSING" 24 "APC_ABORT_APP_MIA" 23 "APC_ABORT_PAUSE_CYCLES" 22 "APC_ABORT_EPAS_INHIBITED" 21 "APC_ABORT_USER_KEYFOB" 20 "APC_ABORT_SC_MIA" 19 "APC_ABORT_SENSOR_FAILURE" 18 "APC_ABORT_PRECRUISE_TIMEOUT" 17 "APC_ABORT_UI_REQUEST" 16 "APC_ABORT_LOST_DI_CONTROL" 15 "APC_ABORT_PARK_GEAR" 14 "APC_ABORT_RESTART_TIMEOUT" 13 "APC_ABORT_PAUSE_USER_TIMEOUT" 12 "APC_ABORT_PAUSE_OBSTACLE_TIMEOUT" 11 "APC_ABORT_ESP_MIA" 10 "APC_ABORT_SCCM_MIA" 9 "APC_ABORT_MCU_MIA" 8 "APC_ABORT_DI_MIA" 7 "APC_ABORT_EPAS_MIA" 6 "APC_ABORT_PARK_MIA" 5 "APC_ABORT_PREGUIDANCE_TIMEOUT" 4 "APC_ABORT_INVALID_SPACE" 3 "APC_ABORT_MCU_REQUEST_MISMATCH" 2 "APC_ABORT_PARK_GUIDANCE_ENDED" 1 "APC_ABORT_LOST_ANGLE_CONTROL" 0 "APC_ABORT_NONE" ;
VAL_ 1513 APP_sw283_mainCam 1 "HEALTHY" 0 "FAULTED" ;
VAL_ 1513 APP_sw283_narrowCam 1 "HEALTHY" 0 "FAULTED" ;
VAL_ 1513 APP_sw283_fisheyeCam 1 "HEALTHY" 0 "FAULTED" ;
VAL_ 1513 APP_sw283_leftRepeaterCam 1 "HEALTHY" 0 "FAULTED" ;
VAL_ 1513 APP_sw283_rightRepeaterCam 1 "HEALTHY" 0 "FAULTED" ;
VAL_ 1513 APP_sw283_leftPillarCam 1 "HEALTHY" 0 "FAULTED" ;
VAL_ 1513 APP_sw283_rightPillarCam 1 "HEALTHY" 0 "FAULTED" ;
VAL_ 1513 APP_sw283_bucCam 1 "HEALTHY" 0 "FAULTED" ;
VAL_ 1513 APP_sw312_expectedSensorModel 2 "CAMERA_SENSOR_AR0136" 1 "CAMERA_SENSOR_AR0132" 0 "CAMERA_SENSOR_UNKNOWN" ;
VAL_ 1513 APP_sw312_detectedSensorModel 2 "CAMERA_SENSOR_AR0136" 1 "CAMERA_SENSOR_AR0132" 0 "CAMERA_SENSOR_UNKNOWN" ;
VAL_ 1513 APP_sw313_expectedSensorModel 2 "CAMERA_SENSOR_AR0136" 1 "CAMERA_SENSOR_AR0132" 0 "CAMERA_SENSOR_UNKNOWN" ;
VAL_ 1513 APP_sw313_detectedSensorModel 2 "CAMERA_SENSOR_AR0136" 1 "CAMERA_SENSOR_AR0132" 0 "CAMERA_SENSOR_UNKNOWN" ;
VAL_ 1513 APP_sw314_expectedSensorModel 2 "CAMERA_SENSOR_AR0136" 1 "CAMERA_SENSOR_AR0132" 0 "CAMERA_SENSOR_UNKNOWN" ;
VAL_ 1513 APP_sw314_detectedSensorModel 2 "CAMERA_SENSOR_AR0136" 1 "CAMERA_SENSOR_AR0132" 0 "CAMERA_SENSOR_UNKNOWN" ;
VAL_ 1513 APP_sw315_expectedSensorModel 2 "CAMERA_SENSOR_AR0136" 1 "CAMERA_SENSOR_AR0132" 0 "CAMERA_SENSOR_UNKNOWN" ;
VAL_ 1513 APP_sw315_detectedSensorModel 2 "CAMERA_SENSOR_AR0136" 1 "CAMERA_SENSOR_AR0132" 0 "CAMERA_SENSOR_UNKNOWN" ;
VAL_ 1513 APP_sw316_expectedSensorModel 2 "CAMERA_SENSOR_AR0136" 1 "CAMERA_SENSOR_AR0132" 0 "CAMERA_SENSOR_UNKNOWN" ;
VAL_ 1513 APP_sw316_detectedSensorModel 2 "CAMERA_SENSOR_AR0136" 1 "CAMERA_SENSOR_AR0132" 0 "CAMERA_SENSOR_UNKNOWN" ;
VAL_ 1513 APP_sw317_expectedSensorModel 2 "CAMERA_SENSOR_AR0136" 1 "CAMERA_SENSOR_AR0132" 0 "CAMERA_SENSOR_UNKNOWN" ;
VAL_ 1513 APP_sw317_detectedSensorModel 2 "CAMERA_SENSOR_AR0136" 1 "CAMERA_SENSOR_AR0132" 0 "CAMERA_SENSOR_UNKNOWN" ;
VAL_ 1513 APP_sw318_expectedSensorModel 2 "CAMERA_SENSOR_AR0136" 1 "CAMERA_SENSOR_AR0132" 0 "CAMERA_SENSOR_UNKNOWN" ;
VAL_ 1513 APP_sw318_detectedSensorModel 2 "CAMERA_SENSOR_AR0136" 1 "CAMERA_SENSOR_AR0132" 0 "CAMERA_SENSOR_UNKNOWN" ;
VAL_ 1513 APP_sw319_expectedSensorModel 2 "CAMERA_SENSOR_AR0136" 1 "CAMERA_SENSOR_AR0132" 0 "CAMERA_SENSOR_UNKNOWN" ;
VAL_ 1513 APP_sw319_detectedSensorModel 2 "CAMERA_SENSOR_AR0136" 1 "CAMERA_SENSOR_AR0132" 0 "CAMERA_SENSOR_UNKNOWN" ;
VAL_ 1513 APP_sw320_expectedSensorModel 2 "CAMERA_SENSOR_AR0136" 1 "CAMERA_SENSOR_AR0132" 0 "CAMERA_SENSOR_UNKNOWN" ;
VAL_ 1513 APP_sw320_detectedSensorModel 2 "CAMERA_SENSOR_AR0136" 1 "CAMERA_SENSOR_AR0132" 0 "CAMERA_SENSOR_UNKNOWN" ;
VAL_ 1020 APP_decisionTemperature 0 "UNKNOWN" ;
VAL_ 1020 APP_pascalTemperature 0 "UNKNOWN" ;
VAL_ 1020 APP_parkerATemperature 0 "UNKNOWN" ;
VAL_ 1020 APP_parkerBTemperature 0 "UNKNOWN" ;
VAL_ 1020 APP_pascalExtTemperature 0 "UNKNOWN" ;
VAL_ 1020 APP_parkerExtTemperature 0 "UNKNOWN" ;
VAL_ 1010 APP_cameraPosition 9 "CAM_SELFIE" 8 "CAM_BACKUP" 7 "CAM_R_REPEATER" 6 "CAM_L_REPEATER" 5 "CAM_R_PILLAR" 4 "CAM_L_PILLAR" 3 "CAM_FISHEYE" 2 "CAM_NARROW" 1 "CAM_MAIN" 0 "CAM_INVALID" ;
VAL_ 1010 APP_mainCamExtPitchCal 511 "SNA" ;
VAL_ 1010 APP_mainCamExtYawCal 511 "SNA" ;
VAL_ 1010 APP_mainCalibTime 127 "SNA" ;
VAL_ 1010 APP_mainCalibProgress 127 "SNA" ;
VAL_ 1010 APP_narrowCamExtPitchCal 511 "SNA" ;
VAL_ 1010 APP_narrowCamExtYawCal 511 "SNA" ;
VAL_ 1010 APP_narrowCalibTime 127 "SNA" ;
VAL_ 1010 APP_narrowCalibProgress 127 "SNA" ;
VAL_ 1010 APP_fisheyeCamExtPitchCal 511 "SNA" ;
VAL_ 1010 APP_fisheyeCamExtYawCal 511 "SNA" ;
VAL_ 1010 APP_fisheyeCalibTime 127 "SNA" ;
VAL_ 1010 APP_fisheyeCalibProgress 127 "SNA" ;
VAL_ 1010 APP_lPillarCamExtPitchCal 511 "SNA" ;
VAL_ 1010 APP_lPillarCamExtYawCal 511 "SNA" ;
VAL_ 1010 APP_lPillarCalibTime 127 "SNA" ;
VAL_ 1010 APP_lPillarCalibProgress 127 "SNA" ;
VAL_ 1010 APP_rPillarCamExtPitchCal 511 "SNA" ;
VAL_ 1010 APP_rPillarCamExtYawCal 511 "SNA" ;
VAL_ 1010 APP_rPillarCalibTime 127 "SNA" ;
VAL_ 1010 APP_rPillarCalibProgress 127 "SNA" ;
VAL_ 1010 APP_lRepeatCamExtPitchCal 511 "SNA" ;
VAL_ 1010 APP_lRepeatCamExtYawCal 511 "SNA" ;
VAL_ 1010 APP_lRepeatCalibTime 127 "SNA" ;
VAL_ 1010 APP_lRepeatCalibProgress 127 "SNA" ;
VAL_ 1010 APP_rRepeatCamExtPitchCal 511 "SNA" ;
VAL_ 1010 APP_rRepeatCamExtYawCal 511 "SNA" ;
VAL_ 1010 APP_rRepeatCalibTime 127 "SNA" ;
VAL_ 1010 APP_rRepeatCalibProgress 127 "SNA" ;
VAL_ 1010 APP_backupCamExtPitchCal 511 "SNA" ;
VAL_ 1010 APP_backupCamExtYawCal 511 "SNA" ;
VAL_ 1010 APP_backupCalibTime 127 "SNA" ;
VAL_ 1010 APP_backupCalibProgress 127 "SNA" ;
VAL_ 1017 APP_mainCameraLUX 255 "CAMERA_LUX_SNA" 254 "CAMERA_LUX_SATURATED" ;
VAL_ 1017 APP_narrowCameraLUX 255 "CAMERA_LUX_SNA" 254 "CAMERA_LUX_SATURATED" ;
VAL_ 1017 APP_fisheyeCameraLUX 255 "CAMERA_LUX_SNA" 254 "CAMERA_LUX_SATURATED" ;
VAL_ 1017 APP_lRepeatCameraLUX 255 "CAMERA_LUX_SNA" 254 "CAMERA_LUX_SATURATED" ;
VAL_ 1017 APP_rRepeatCameraLUX 255 "CAMERA_LUX_SNA" 254 "CAMERA_LUX_SATURATED" ;
VAL_ 1017 APP_lPillarCameraLUX 255 "CAMERA_LUX_SNA" 254 "CAMERA_LUX_SATURATED" ;
VAL_ 1017 APP_rPillarCameraLUX 255 "CAMERA_LUX_SNA" 254 "CAMERA_LUX_SATURATED" ;
VAL_ 1017 APP_backupCameraLUX 255 "CAMERA_LUX_SNA" 254 "CAMERA_LUX_SATURATED" ;
VAL_ 1177 APP_mainCameraTemperature 255 "SNA" ;
VAL_ 1177 APP_narrowCameraTemperature 255 "SNA" ;
VAL_ 1177 APP_fisheyeCameraTemperature 255 "SNA" ;
VAL_ 1177 APP_rRepeaterCameraTemperature 255 "SNA" ;
VAL_ 1177 APP_lRepeaterCameraTemperature 255 "SNA" ;
VAL_ 1177 APP_lPillarCameraTemperature 255 "SNA" ;
VAL_ 1177 APP_rPillarCameraTemperature 255 "SNA" ;
VAL_ 1177 APP_backupCameraTemperature 255 "SNA" ;
VAL_ 1353 APP_infoIndex 2 "AP_GITHASH" 1 "FW_GITHASH" 0 "AP_BUILD_TYPE" ;
VAL_ 1353 APP_buildType 3 "AP_BUILDTYPE_REPO" 1 "AP_BUILDTYPE_LOCAL" 0 "AP_BUILDTYPE_SIGNED" ;
VAL_ 601 APP_watchdogState 7 "AP_WDOG_STATE_SNA" 3 "AP_WDOG_STATE_HEALTHY" 2 "AP_WDOG_STATE_CRITICAL" 1 "AP_WDOG_STATE_DEGRADED" 0 "AP_WDOG_STATE_UNKNOWN" ;
VAL_ 601 APP_fusedState 3 "APP_FUSE_SNA" 2 "APP_FUSE_FUSED" 1 "APP_FUSE_UNFUSED" 0 "APP_FUSE_UNKNOWN" ;
VAL_ 601 APP_factorySummonStatus 8 "FACTORY_SUMMON_END_OF_ROUTE" 7 "FACTORY_SUMMON_UNAVAILABLE_HEADING_NOT_INITIALIZED" 6 "FACTORY_SUMMON_UNAVAILABLE_VEHICLE_SPEED_INVALID" 5 "FACTORY_SUMMON_UNAVAILABLE_NO_GPS" 4 "FACTORY_SUMMON_UNAVAILABLE_GOAL_TOO_FAR" 3 "FACTORY_SUMMON_UNAVAILABLE_NO_QR_INSTRUCTION" 2 "FACTORY_SUMMON_AVAILABLE" 1 "FACTORY_SUMMON_ACTIVE" 0 "FACTORY_SUMMON_SNA" ;
VAL_ 601 APP_clipRecordingStatus 4 "APP_CLIP_FAULTED" 3 "APP_CLIP_TRIGGERED" 2 "APP_CLIP_RECORDING" 1 "APP_CLIP_IDLE" 0 "APP_CLIP_NO_DRIVE" ;
VAL_ 601 APP_summonUnavailableReason 20 "SMART_SUMMON_UNAVAILABLE_NO_CONTEXT" 19 "SMART_SUMMON_UNAVAILABLE_PUBLIC_ROAD_BOUNDARIES_NOT_VALID" 18 "SMART_SUMMON_UNAVAILABLE_ALL_SENSORS_OCCLUDED" 17 "SMART_SUMMON_UNAVAILABLE_ULTRASONIC_STALE" 16 "SMART_SUMMON_UNAVAILABLE_VISION_HEALTH_CRITICAL" 15 "SMART_SUMMON_UNAVAILABLE_CAMERA_NOT_CALIBRATED" 14 "SMART_SUMMON_UNAVAILABLE_END_OF_LEASH" 13 "SMART_SUMMON_UNAVAILABLE_PHONE_IS_TOO_FAR" 12 "SMART_SUMMON_UNAVAILABLE_EGO_GPS_UNAVAILABLE" 11 "SMART_SUMMON_UNAVAILABLE_PHONE_GPS_UNAVAILABLE" 10 "SMART_SUMMON_UNAVAILABLE_POOR_CONNECTION" 9 "SMART_SUMMON_UNAVAILABLE_PUBLIC_ROAD" 8 "SMART_SUMMON_UNAVAILABLE_EAC_UNAVAILABLE" 7 "SMART_SUMMON_UNAVAILABLE_CRUISE_UNAVAILABLE" 6 "SMART_SUMMON_UNAVAILABLE_ULTRASONIC_FAULT" 5 "SMART_SUMMON_UNAVAILABLE_ULTRASONIC_BLOCKED" 4 "SMART_SUMMON_UNAVAILABLE_CAMERA_BLOCKED" 3 "SMART_SUMMON_UNAVAILABLE_CAMERA_STREAM" 2 "SMART_SUMMON_UNAVAILABLE_NOT_IN_PARK" 1 "SMART_SUMMON_UNAVAILABLE_NONE" 0 "SMART_SUMMON_UNAVAILABLE_UNKNOWN" ;
VAL_ 1018 APP_summonInstruction 7 "SNA" 4 "ABORTED" 3 "DRIVE_BACKWARD" 2 "DRIVE_FORWARD" 1 "STOP" 0 "NO_MESSAGE" ;
VAL_ 1018 APP_summonState 7 "SNA" 6 "FAULT" 5 "GUIDANCE_FINISHED" 4 "PRE_GUIDANCE" 3 "GUIDANCE_RIGHT" 2 "GUIDANCE_LEFT" 1 "SEARCHING" 0 "NOT_AVAILABLE" ;
VAL_ 906 APP_solarObscurityPercent 255 "SNA" ;
VAL_ 906 APP_solarLoadEstimate 2047 "SNA" ;
VAL_ 602 APP_tcFeatureState 3 "TC_ACTIVE" 2 "TC_AVAILABLE" 1 "TC_UNAVAILABLE" 0 "TC_DISABLED" ;
VAL_ 602 APP_tcStateMachine 6 "TCSM_CONTINUING" 5 "TCSM_STOPPED" 4 "TCSM_STOPPING" 3 "TCSM_WARNING" 2 "TCSM_AWARE" 1 "TCSM_STANDBY" 0 "TCSM_DISABLED" ;
VAL_ 602 APP_tcControlSource 3 "TC_SOURCE_MAP_AND_VISION" 2 "TC_SOURCE_VISION" 1 "TC_SOURCE_MAP" 0 "TC_SOURCE_NONE" ;
VAL_ 602 APP_tcControlType 22 "TC_TYPE_T_ARM" 21 "TC_TYPE_BEV_JUNCTION" 20 "TC_TYPE_T_IMPLICIT_BY_GEOM" 19 "TC_TYPE_T_IMPLICIT_BY_NAME" 18 "TC_TYPE_T_IMPLICIT" 17 "TC_TYPE_NO_STOP" 16 "TC_TYPE_BIKE_MERGE_FROM_RIGHT" 15 "TC_TYPE_BIKE_MERGE_FROM_LEFT" 14 "TC_TYPE_ALL_WAY_STOP_SIGN" 13 "TC_TYPE_TRAFFIC_RULE" 12 "TC_TYPE_SPEED_HUMP" 11 "TC_TYPE_SPEED_BUMP" 10 "TC_TYPE_RAMP_METER" 9 "TC_TYPE_PEDESTRIAN_CROSSING" 8 "TC_TYPE_SUICIDE_LEFT" 7 "TC_TYPE_KEEP_CLEAR_EXIT" 6 "TC_TYPE_KEEP_CLEAR_ENTER" 5 "TC_TYPE_CROSSWALK" 4 "TC_TYPE_YIELD" 3 "TC_TYPE_TRAFFIC_LIGHT" 2 "TC_TYPE_STOP_SIGN" 1 "TC_TYPE_UNKNOWN" 0 "TC_TYPE_INVALID" ;
VAL_ 602 APP_tcControlLightState 6 "TC_LIGHTSTATE_OTHER" 5 "TC_LIGHTSTAET_WHITE" 4 "TC_LIGHTSTATE_OFF" 3 "TC_LIGHTSTATE_YELLOW" 2 "TC_LIGHTSTATE_GREEN" 1 "TC_LIGHTSTATE_RED" 0 "TC_LIGHTSTATE_NONE" ;
VAL_ 602 APP_tcContinuationReason 13 "TC_CONTINUE_CONTROL_UNAVAILABLE" 12 "TC_CONTINUE_SUMMON_TIMEOUT" 11 "TC_CONTINUE_CLEAR_TO_GO" 10 "TC_CONTINUE_WARNING_TIMEOUT" 9 "TC_CONTINUE_INVALID_MAP_OR_VISION_CONTROL" 8 "TC_CONTINUE_PASSED_STOP" 7 "TC_CONTINUE_ASSUMED_DRIVER_STOPPED" 6 "TC_CONTINUE_AP_ACTIVATED_ON_HARD_STOP" 5 "TC_CONTINUE_VISION_SIGNALS" 4 "TC_CONTINUE_REQUIRED_DECEL_TOO_HIGH" 3 "TC_CONTINUE_USER_INPUT_ON_RED" 2 "TC_CONTINUE_USER_INPUT_ON_GREEN" 1 "TC_CONTINUE_GREEN_LIGHT_WITH_CIPV" 0 "TC_CONTINUE_NONE" ;
VAL_ 602 APP_tcConfirmationType 2 "TC_CONFIRM_PEDAL" 1 "TC_CONFIRM_STALK" 0 "TC_CONFIRM_NONE" ;
VAL_ 602 APP_tcWarningSuppressionReason 18 "TC_WARNING_SUPPRESS_TOO_FAR_FROM_PREDICTED_JUNCTION" 17 "TC_WARNING_SUPPRESS_NOT_SUPPORTED_BY_MEASUREMENTS" 16 "TC_WARNING_SUPPRESS_NO_ASSOCIATED_VISION_LINE" 15 "TC_WARNING_SUPPRESS_AMBIGUOUS_VISION_TYPE" 14 "TC_WARNING_SUPPRESS_CIPV_DID_NOT_STOP" 13 "TC_WARNING_SUPPRESS_STALE_SIGN_DETECTION" 12 "TC_WARNING_SUPPRESS_WRONG_MAP_TYPE" 11 "TC_WARNING_SUPPRESS_LIGHT_UNASSOCIATED" 10 "TC_WARNING_SUPPRESS_CIPV_CONTINUING" 9 "TC_WARNING_SUPPRESS_PEDAL_OVERRIDE" 8 "TC_WARNING_SUPPRESS_LOCALIZATION_DEGRADED" 7 "TC_WARNING_SUPPRESS_HARD_TURN" 6 "TC_WARNING_SUPPRESS_ASSUMED_YELLOW" 5 "TC_WARNING_SUPPRESS_DRIVER_SLOWING_DOWN" 4 "TC_WARNING_SUPPRESS_BELOW_MIN_SPEED" 3 "TC_WARNING_SUPPRESS_SLOWDOWN_PLANNED" 2 "TC_WARNING_SUPPRESS_INSUFFICIENT_DATA" 1 "TC_WARNING_SUPPRESS_FEATURE_DISABLED" 0 "TC_WARNING_SUPPRESS_NONE" ;
VAL_ 602 APP_tcUnavailableReason 9 "AP_UNAVAILBLE_SUN_GLARE_ON_ROAD_RESTRICTED" 8 "AP_UNAVAILBLE_CAMERA_BLINDED_ON_ROAD_RESTRICTED" 7 "AP_UNAVAILBLE_GPS_DEGRADED" 6 "AP_UNAVAILBLE_ROAD_ESTIMATOR_UNHEALTHY" 5 "AP_UNAVAILBLE_SUN_GLARE" 4 "AP_UNAVAILBLE_CAMERA_BLINDED" 3 "AP_UNAVAILBLE_ROAD_CLASS" 2 "AP_UNAVAILBLE_LOST_MAP_LOCALIZATION" 1 "AP_UNAVAILBLE_MCU_DISABLED" 0 "AP_UNAVAILBLE_NONE" ;
VAL_ 1014 APP_ussSequenceEnum 12 "APP_USS_SEQUENCE_FMS_FAST" 2 "APP_USS_SEQUENCE_UPA" 0 "APP_USS_SEQUENCE_FMS_SLOW" ;
